VERSION ""

NS_ :

BS_:

BU_: BMS ECC EVBUS_Virtual_ECU GW OBC VCU

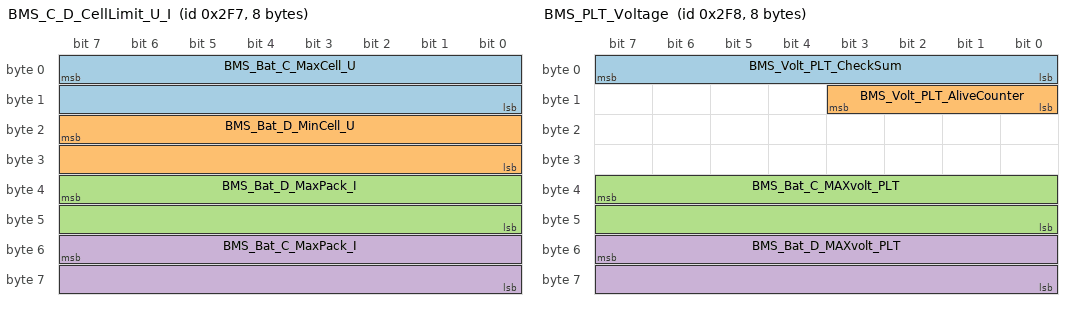
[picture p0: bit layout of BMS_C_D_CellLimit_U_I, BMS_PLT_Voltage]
BO_ 759 BMS_C_D_CellLimit_U_I: 8 BMS
 SG_ BMS_Bat_C_MaxCell_U : 7|16@0+ (0.1,0) [0|6553.5] "mV"  GW,VCU
 SG_ BMS_Bat_D_MinCell_U : 23|16@0+ (0.1,0) [0|6553.5] "mV"  ECC,GW,OBC,VCU
 SG_ BMS_Bat_D_MaxPack_I : 39|16@0+ (0.02,0) [0|1310.7] "A"  ECC,GW,OBC,VCU
 SG_ BMS_Bat_C_MaxPack_I : 55|16@0+ (0.02,0) [0|1310.7] "A"  GW,VCU

BO_ 760 BMS_PLT_Voltage: 8 BMS
 SG_ BMS_Volt_PLT_CheckSum : 7|8@0+ (1,0) [0|255] ""  GW,VCU
 SG_ BMS_Volt_PLT_AliveCounter : 11|4@0+ (1,0) [0|14] ""  GW,VCU
 SG_ BMS_Bat_C_MAXvolt_PLT : 39|16@0+ (0.02,0) [0|1310.7] "V"  GW,VCU
 SG_ BMS_Bat_D_MAXvolt_PLT : 55|16@0+ (0.02,0) [0|1310.7] "V"  GW,VCU

BO_ 792 ESP_0x318: 8 GW
 SG_ ESP_318_CheckSum : 7|8@0+ (1,0) [0|255] ""  BMS,ECC,OBC
 SG_ ESP_318_AliveCounter : 11|4@0+ (1,0) [0|14] ""  BMS,ECC,OBC
 SG_ ESP_BrkPedlStsVld : 13|2@0+ (1,0) [0|3] ""  ECC
 SG_ ESP_BrkPedlSts : 14|1@0+ (1,0) [0|1] ""  ECC
 SG_ ESP_VehSpdVld : 17|2@0+ (1,0) [0|3] ""  BMS,ECC,OBC
 SG_ ESP_SysActv : 20|1@0+ (1,0) [0|1] ""  ECC
 SG_ ESP_LampSwtOffIndcn : 21|1@0+ (1,0) [0|1] ""  ECC
 SG_ ESP_FltIndcn_EBD : 22|1@0+ (1,0) [0|1] ""  ECC
 SG_ ESP_FltIndcn_ABS : 23|1@0+ (1,0) [0|1] ""  ECC
 SG_ ESP_MilgRollgCntr_ODO : 31|16@0+ (1,0) [0|65535] "pulses"  ECC
 SG_ ESP_VehSpd : 47|16@0+ (0.1,0) [0|300] "km/h"  BMS,ECC,OBC
 SG_ ESP_IninModSigIndcn : 56|1@0+ (1,0) [0|1] ""  ECC
 SG_ ESP_FltIndcn_TCS : 57|1@0+ (1,0) [0|1] ""  ECC
 SG_ ESP_CtrlSts_HDC : 59|2@0+ (1,0) [0|3] ""  ECC
 SG_ ESP_AvlIndcn_HDC : 60|1@0+ (1,0) [0|1] ""  ECC
 SG_ ESP_NoBrkP : 61|1@0+ (1,0) [0|1] ""  ECC
 SG_ ESP_RDAEnaFlg : 62|1@0+ (1,0) [0|1] ""  ECC

BO_ 816 BMS_HVBatt_Status_2_TBOX: 16 BMS
 SG_ BMS_330_391_CheckSum : 7|8@0+ (1,0) [0|255] ""  GW,VCU
 SG_ BMS_330_391_AliveCounter : 11|4@0+ (1,0) [0|14] ""  GW,VCU
 SG_ BMS_VehInsulFltDisp : 16|1@0+ (1,0) [0|1] ""  GW
 SG_ BMS_PwrBattSysFltDisp : 17|1@0+ (1,0) [0|1] ""  GW
 SG_ BMS_PwrBattRmngCpSOC : 31|8@0+ (0.4,0) [0|100] "%"  ECC,GW,VCU
 SG_ BMS_PwrBattAvlCp : 39|16@0+ (0.01,0) [0|655.35] "Ah"  GW,VCU
 SG_ BMS_CellMinTAlrm : 48|1@0+ (1,0) [0|1] ""  GW,VCU
 SG_ BMS_PwrBattThermRunawayAlrm : 49|1@0+ (1,0) [0|1] ""  GW,VCU
 SG_ BMS_PwrBattOverT : 53|1@0+ (1,0) [0|1] ""  GW,VCU
 SG_ BMS_PwrBattInsulSts : 55|2@0+ (1,0) [0|3] ""  GW,VCU
 SG_ BMS_330_SSecOC_Fresh_Byte0 : 71|8@0+ (1,0) [0|255] ""  GW,VCU
 SG_ BMS_330_SSecOC_MAC_Byte0 : 79|8@0+ (1,0) [0|255] ""  GW,VCU
 SG_ BMS_330_SSecOC_MAC_Byte1 : 87|8@0+ (1,0) [0|255] ""  GW,VCU
 SG_ BMS_330_SSecOC_MAC_Byte2 : 95|8@0+ (1,0) [0|255] ""  GW,VCU

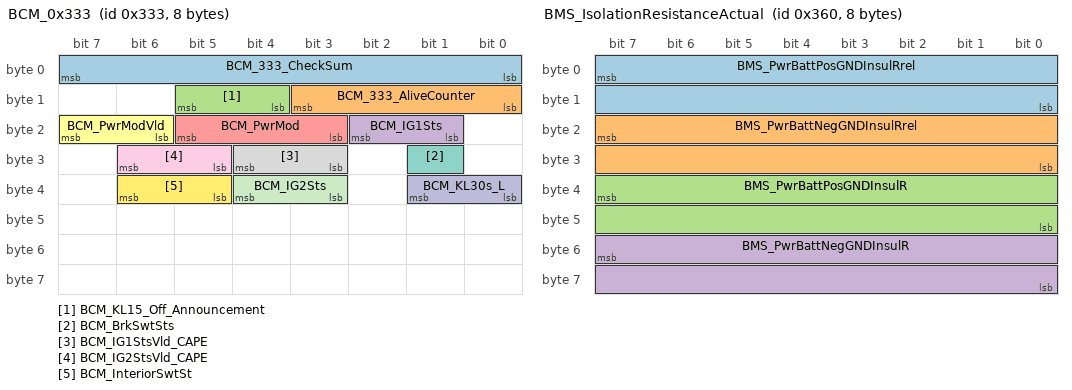
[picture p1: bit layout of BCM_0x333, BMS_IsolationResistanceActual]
BO_ 819 BCM_0x333: 8 GW
 SG_ BCM_333_CheckSum : 7|8@0+ (1,0) [0|255] ""  BMS,ECC,OBC,VCU
 SG_ BCM_333_AliveCounter : 11|4@0+ (1,0) [0|14] ""  BMS,ECC,OBC,VCU
 SG_ BCM_KL15_Off_Announcement : 13|2@0+ (1,0) [0|3] ""  ECC
 SG_ BCM_IG1Sts : 18|2@0+ (1,0) [0|3] ""  BMS,ECC
 SG_ BCM_PwrMod : 21|3@0+ (1,0) [0|7] ""  BMS,ECC,OBC,VCU
 SG_ BCM_PwrModVld : 23|2@0+ (1,0) [0|3] ""  BMS,ECC,OBC,VCU
 SG_ BCM_BrkSwtSts : 25|1@0+ (1,0) [0|1] ""  ECC
 SG_ BCM_IG1StsVld_CAPE : 28|2@0+ (1,0) [0|3] ""  BMS,ECC
 SG_ BCM_IG2StsVld_CAPE : 30|2@0+ (1,0) [0|3] ""  ECC
 SG_ BCM_KL30s_L : 33|2@0+ (1,0) [0|3] ""  ECC
 SG_ BCM_IG2Sts : 36|2@0+ (1,0) [0|3] ""  ECC
 SG_ BCM_InteriorSwtSt : 38|2@0+ (1,0) [0|3] ""  ECC

BO_ 856 VCU_0x358: 8 VCU
 SG_ VCU_358_CheckSum : 7|8@0+ (1,0) [0|255] ""  EVBUS_Virtual_ECU
 SG_ VCU_358_AliveCounter : 11|4@0+ (1,0) [0|14] ""  EVBUS_Virtual_ECU
 SG_ VCU_KickdwnFlg : 13|2@0+ (1,0) [0|3] ""  EVBUS_Virtual_ECU
 SG_ VCU_EPedlEnaSig : 15|1@0+ (1,0) [0|1] ""  EVBUS_Virtual_ECU
 SG_ VCU_ComLostFlt_ESP : 16|1@0+ (1,0) [0|1] ""  EVBUS_Virtual_ECU
 SG_ VCU_ComFlt_iBooster : 17|1@0+ (1,0) [0|1] ""  EVBUS_Virtual_ECU
 SG_ VCU_RegenLvlFb : 19|2@0+ (1,0) [0|3] ""  EVBUS_Virtual_ECU
 SG_ VCU_AccelModFb : 21|2@0+ (1,0) [0|3] ""  EVBUS_Virtual_ECU
 SG_ VCU_EPedlStsFb : 23|2@0+ (1,0) [0|3] ""  EVBUS_Virtual_ECU
 SG_ VCU_CcTrgSpdDisp : 31|8@0+ (1,0) [0|255] ""  EVBUS_Virtual_ECU
 SG_ VCU_Sts_CC_ICC : 35|4@0+ (1,0) [0|15] ""  EVBUS_Virtual_ECU
 SG_ VCU_CCIconDisp : 38|3@0+ (1,0) [0|7] ""  EVBUS_Virtual_ECU
 SG_ VCU_DispSpdUnit_CC : 39|1@0+ (1,0) [0|1] ""  EVBUS_Virtual_ECU
 SG_ VCU_BoostEnStat : 43|4@0+ (1,0) [0|15] ""  EVBUS_Virtual_ECU
 SG_ VCU_OTARdy_Fb : 45|2@0+ (1,0) [0|3] ""  EVBUS_Virtual_ECU
 SG_ VCU_OTA_ECUInhb_Req : 47|2@0+ (1,0) [0|3] ""  EVBUS_Virtual_ECU
 SG_ VCU_OTAVehCdnChk_ASIL : 49|2@0+ (1,0) [0|3] ""  BMS,ECC,OBC
 SG_ VCU_OTAVehInhb_ASIL_Fb : 51|2@0+ (1,0) [0|3] ""  BMS,ECC,OBC

BO_ 864 BMS_IsolationResistanceActual: 8 BMS
 SG_ BMS_PwrBattPosGNDInsulRrel : 7|16@0+ (1,0) [0|65535] "Ohm/V"  GW,VCU
 SG_ BMS_PwrBattNegGNDInsulRrel : 23|16@0+ (1,0) [0|65535] "Ohm/V"  GW,VCU
 SG_ BMS_PwrBattPosGNDInsulR : 39|16@0+ (1,0) [0|65535] "k¦¸"  GW,VCU
 SG_ BMS_PwrBattNegGNDInsulR : 55|16@0+ (1,0) [0|65535] "k¦¸"  GW,VCU

BO_ 882 BMS_CellTemp_CoolingHeating: 16 BMS
 SG_ BMS_372_382_CheckSum : 7|8@0+ (1,0) [0|255] ""  ECC,GW,VCU
 SG_ BMS_372_382_AliveCounter : 11|4@0+ (1,0) [0|14] ""  ECC,GW,VCU
 SG_ BMS_OTARdy_Fb : 13|2@0+ (1,0) [0|3] ""  GW
 SG_ BMS_CellMinT : 23|8@0+ (1,-48) [-48|207] "Degree Celsius"  ECC,GW,VCU
 SG_ BMS_CellDiffT : 31|8@0+ (1,0) [0|255] "Degree Celsius"  ECC,GW,VCU
 SG_ BMS_CellMaxT : 39|8@0+ (1,-48) [-48|207] "Degree Celsius"  ECC,GW,VCU
 SG_ BMS_BattAvrgT : 47|8@0+ (1,-48) [-48|207] "Degree Celsius"  ECC,GW,VCU
 SG_ BMS_PwrBattHeatgMngDmd : 49|2@0+ (1,0) [0|3] ""  ECC,GW,VCU
 SG_ BMS_ECCSysAllwDwnPwrCmd : 50|1@0+ (1,0) [0|1] ""  ECC,GW
 SG_ BMS_BattInlTDmd : 63|8@0+ (1,-48) [-48|207] ""  ECC,GW
 SG_ BMS_372_SSecOC_Fresh_Byte0 : 71|8@0+ (1,0) [0|255] ""  GW,VCU
 SG_ BMS_372_SSecOC_MAC_Byte0 : 79|8@0+ (1,0) [0|255] ""  GW,VCU
 SG_ BMS_372_SSecOC_MAC_Byte1 : 87|8@0+ (1,0) [0|255] ""  GW,VCU
 SG_ BMS_372_SSecOC_MAC_Byte2 : 95|8@0+ (1,0) [0|255] ""  GW,VCU

BO_ 883 ECC_0x373: 8 ECC
 SG_ ECC_CrtSts : 3|4@0+ (1,0) [0|15] ""  GW,VCU
 SG_ ECC_IninSts : 4|1@0+ (1,0) [0|1] ""  GW,VCU
 SG_ ECC_PwrSysHeatMngtSts : 6|2@0+ (1,0) [0|3] ""  GW,VCU
 SG_ ECC_ACSts : 7|1@0+ (1,0) [0|1] ""  GW,VCU
 SG_ ECC_AirClnSts : 8|1@0+ (1,0) [0|1] ""  GW,VCU
 SG_ ECC_WindSpdSts : 12|4@0+ (1,0) [0|15] ""  BMS,GW,VCU
 SG_ ECC_BackRowAirOutlModSts : 15|3@0+ (1,0) [0|7] ""  GW,VCU
 SG_ ECC_DrvrTSetSts : 23|8@0+ (0.5,0) [0|127.5] ""  GW,VCU
 SG_ ECC_PassTSetSts : 31|8@0+ (0.5,0) [0|127.5] ""  GW,VCU
 SG_ ECC_HeatSts : 32|1@0+ (1,0) [0|1] ""  BMS,GW,VCU
 SG_ ECC_AUTOSts : 33|1@0+ (1,0) [0|1] ""  GW,VCU
 SG_ ECC_SYNCSts : 34|1@0+ (1,0) [0|1] ""  GW,VCU
 SG_ ECC_InfoSysWrmColdDisp : 36|2@0+ (1,0) [0|3] ""  GW,VCU
 SG_ ECC_CircSts : 37|1@0+ (1,0) [0|1] ""  GW,VCU
 SG_ ECC_ParticleConcVld : 39|2@0+ (1,0) [0|3] ""  GW,VCU
 SG_ ECC_OutdT : 47|8@0+ (0.5,-48) [-48|79.5] "Degree Celsius"  BMS,GW,VCU
 SG_ ECC_OutdTVld : 49|2@0+ (1,0) [0|3] ""  BMS,GW,VCU
 SG_ ECC_MaxFrntDefrst : 50|1@0+ (1,0) [0|1] ""  GW,VCU
 SG_ ECC_HeatMngtSysFlt : 51|1@0+ (1,0) [0|1] ""  GW,VCU
 SG_ ECC_HeatMngtFctLim : 52|1@0+ (1,0) [0|1] ""  GW,VCU
 SG_ ECC_DrvrAirOutlMod : 55|3@0+ (1,0) [0|7] ""  GW,VCU
 SG_ ECC_PassAirOutlMod : 58|3@0+ (1,0) [0|7] ""  GW,VCU
 SG_ ECC_RemSts : 60|2@0+ (1,0) [0|3] ""  GW,VCU
 SG_ ECC_OTAInhbRdy : 62|2@0+ (1,0) [0|3] ""  GW,VCU

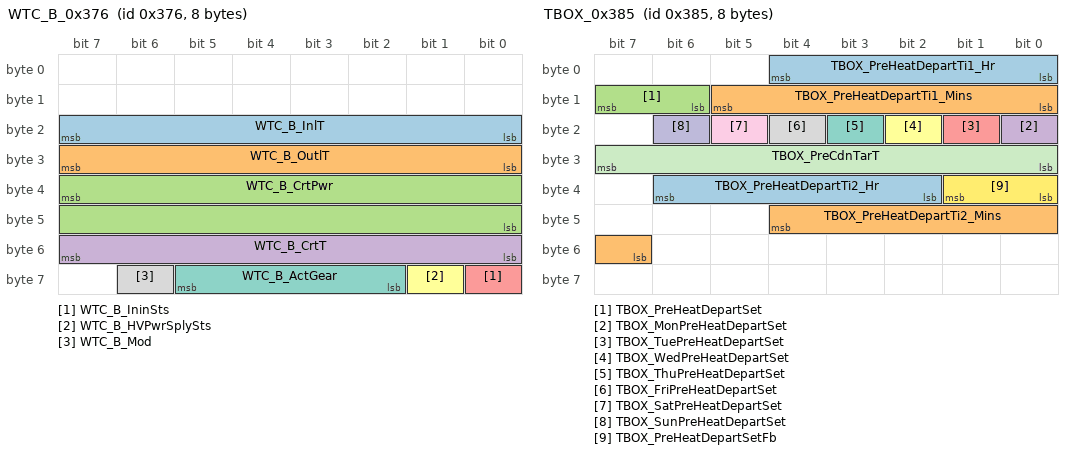
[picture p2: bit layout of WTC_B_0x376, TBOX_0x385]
BO_ 886 WTC_B_0x376: 8 ECC
 SG_ WTC_B_InlT : 23|8@0+ (1,-48) [-48|207] "Degree Celsius"  GW
 SG_ WTC_B_OutlT : 31|8@0+ (1,-48) [-48|207] "Degree Celsius"  GW
 SG_ WTC_B_CrtPwr : 39|16@0+ (1,0) [0|10000] ""  GW,VCU
 SG_ WTC_B_CrtT : 55|8@0+ (1,-48) [-48|207] "Degree Celsius"  GW
 SG_ WTC_B_IninSts : 56|1@0+ (1,0) [0|1] ""  GW
 SG_ WTC_B_HVPwrSplySts : 57|1@0+ (1,0) [0|1] ""  GW
 SG_ WTC_B_ActGear : 61|4@0+ (1,0) [0|15] ""  GW
 SG_ WTC_B_Mod : 62|1@0+ (1,0) [0|1] ""  BMS,GW,VCU

BO_ 901 TBOX_0x385: 8 GW
 SG_ TBOX_PreHeatDepartTi1_Hr : 4|5@0+ (1,0) [0|23] ""  EVBUS_Virtual_ECU
 SG_ TBOX_PreHeatDepartTi1_Mins : 13|6@0+ (1,0) [0|59] ""  EVBUS_Virtual_ECU
 SG_ TBOX_PreHeatDepartSet : 15|2@0+ (1,0) [0|3] ""  EVBUS_Virtual_ECU
 SG_ TBOX_MonPreHeatDepartSet : 16|1@0+ (1,0) [0|1] ""  EVBUS_Virtual_ECU
 SG_ TBOX_TuePreHeatDepartSet : 17|1@0+ (1,0) [0|1] ""  EVBUS_Virtual_ECU
 SG_ TBOX_WedPreHeatDepartSet : 18|1@0+ (1,0) [0|1] ""  EVBUS_Virtual_ECU
 SG_ TBOX_ThuPreHeatDepartSet : 19|1@0+ (1,0) [0|1] ""  EVBUS_Virtual_ECU
 SG_ TBOX_FriPreHeatDepartSet : 20|1@0+ (1,0) [0|1] ""  EVBUS_Virtual_ECU
 SG_ TBOX_SatPreHeatDepartSet : 21|1@0+ (1,0) [0|1] ""  EVBUS_Virtual_ECU
 SG_ TBOX_SunPreHeatDepartSet : 22|1@0+ (1,0) [0|1] ""  EVBUS_Virtual_ECU
 SG_ TBOX_PreCdnTarT : 31|8@0+ (0.5,0) [-48|255] "Degree Celsius"  VCU
 SG_ TBOX_PreHeatDepartSetFb : 33|2@0+ (1,0) [0|3] ""  EVBUS_Virtual_ECU
 SG_ TBOX_PreHeatDepartTi2_Hr : 38|5@0+ (1,0) [0|23] ""  EVBUS_Virtual_ECU
 SG_ TBOX_PreHeatDepartTi2_Mins : 44|6@0+ (1,0) [0|59] ""  EVBUS_Virtual_ECU

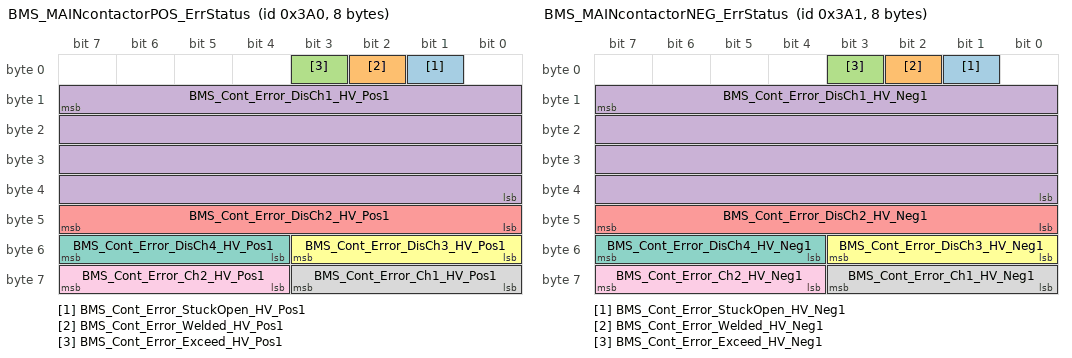
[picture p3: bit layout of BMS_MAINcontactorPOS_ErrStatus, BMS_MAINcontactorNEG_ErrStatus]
BO_ 928 BMS_MAINcontactorPOS_ErrStatus: 8 BMS
 SG_ BMS_Cont_Error_StuckOpen_HV_Pos1 : 1|1@0+ (1,0) [0|1] ""  GW,VCU
 SG_ BMS_Cont_Error_Welded_HV_Pos1 : 2|1@0+ (1,0) [0|1] ""  GW,VCU
 SG_ BMS_Cont_Error_Exceed_HV_Pos1 : 3|1@0+ (1,0) [0|1] ""  GW,VCU
 SG_ BMS_Cont_Error_DisCh1_HV_Pos1 : 15|32@0+ (1,0) [0|4294967295] ""  GW,VCU
 SG_ BMS_Cont_Error_DisCh2_HV_Pos1 : 47|8@0+ (1,0) [0|255] ""  GW,VCU
 SG_ BMS_Cont_Error_DisCh3_HV_Pos1 : 51|4@0+ (1,0) [0|15] ""  GW,VCU
 SG_ BMS_Cont_Error_DisCh4_HV_Pos1 : 55|4@0+ (1,0) [0|15] ""  GW,VCU
 SG_ BMS_Cont_Error_Ch1_HV_Pos1 : 59|4@0+ (1,0) [0|15] ""  GW,VCU
 SG_ BMS_Cont_Error_Ch2_HV_Pos1 : 63|4@0+ (1,0) [0|15] ""  GW,VCU

BO_ 929 BMS_MAINcontactorNEG_ErrStatus: 8 BMS
 SG_ BMS_Cont_Error_StuckOpen_HV_Neg1 : 1|1@0+ (1,0) [0|1] ""  GW,VCU
 SG_ BMS_Cont_Error_Welded_HV_Neg1 : 2|1@0+ (1,0) [0|1] ""  GW,VCU
 SG_ BMS_Cont_Error_Exceed_HV_Neg1 : 3|1@0+ (1,0) [0|1] ""  GW,VCU
 SG_ BMS_Cont_Error_DisCh1_HV_Neg1 : 15|32@0+ (1,0) [0|4294967295] ""  GW,VCU
 SG_ BMS_Cont_Error_DisCh2_HV_Neg1 : 47|8@0+ (1,0) [0|255] ""  GW,VCU
 SG_ BMS_Cont_Error_DisCh3_HV_Neg1 : 51|4@0+ (1,0) [0|15] ""  GW,VCU
 SG_ BMS_Cont_Error_DisCh4_HV_Neg1 : 55|4@0+ (1,0) [0|15] ""  GW,VCU
 SG_ BMS_Cont_Error_Ch1_HV_Neg1 : 59|4@0+ (1,0) [0|15] ""  GW,VCU
 SG_ BMS_Cont_Error_Ch2_HV_Neg1 : 63|4@0+ (1,0) [0|15] ""  GW,VCU

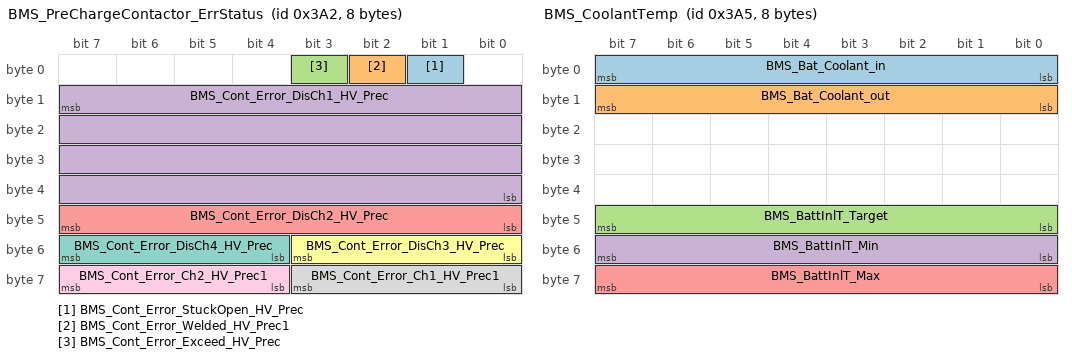
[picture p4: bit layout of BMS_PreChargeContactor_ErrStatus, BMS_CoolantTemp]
BO_ 930 BMS_PreChargeContactor_ErrStatus: 8 BMS
 SG_ BMS_Cont_Error_StuckOpen_HV_Prec : 1|1@0+ (1,0) [0|1] ""  GW,VCU
 SG_ BMS_Cont_Error_Welded_HV_Prec1 : 2|1@0+ (1,0) [0|1] ""  GW,VCU
 SG_ BMS_Cont_Error_Exceed_HV_Prec : 3|1@0+ (1,0) [0|1] ""  GW,VCU
 SG_ BMS_Cont_Error_DisCh1_HV_Prec : 15|32@0+ (1,0) [0|4294967295] ""  GW,VCU
 SG_ BMS_Cont_Error_DisCh2_HV_Prec : 47|8@0+ (1,0) [0|255] ""  GW,VCU
 SG_ BMS_Cont_Error_DisCh3_HV_Prec : 51|4@0+ (1,0) [0|15] ""  GW,VCU
 SG_ BMS_Cont_Error_DisCh4_HV_Prec : 55|4@0+ (1,0) [0|15] ""  GW,VCU
 SG_ BMS_Cont_Error_Ch1_HV_Prec1 : 59|4@0+ (1,0) [0|15] ""  GW,VCU
 SG_ BMS_Cont_Error_Ch2_HV_Prec1 : 63|4@0+ (1,0) [0|15] ""  GW,VCU

BO_ 933 BMS_CoolantTemp: 8 BMS
 SG_ BMS_Bat_Coolant_in : 7|8@0+ (0.5,-40) [-40|87.5] "Degree Celsius"  ECC,GW,VCU
 SG_ BMS_Bat_Coolant_out : 15|8@0+ (0.5,-40) [-40|87.5] "Degree Celsius"  ECC,GW,VCU
 SG_ BMS_BattInlT_Target : 47|8@0+ (1,-48) [-48|207] "Degree Celsius"  ECC,GW,VCU
 SG_ BMS_BattInlT_Min : 55|8@0+ (1,-48) [-48|207] "Degree Celsius"  ECC,GW,VCU
 SG_ BMS_BattInlT_Max : 63|8@0+ (1,-48) [-48|207] "Degree Celsius"  ECC,GW,VCU

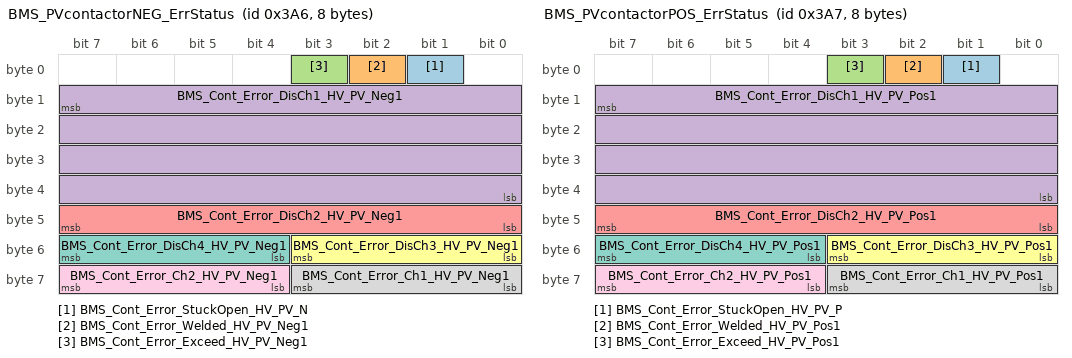
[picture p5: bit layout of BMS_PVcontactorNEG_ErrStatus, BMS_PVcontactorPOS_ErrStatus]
BO_ 934 BMS_PVcontactorNEG_ErrStatus: 8 BMS
 SG_ BMS_Cont_Error_StuckOpen_HV_PV_N : 1|1@0+ (1,0) [0|1] ""  GW,VCU
 SG_ BMS_Cont_Error_Welded_HV_PV_Neg1 : 2|1@0+ (1,0) [0|1] ""  GW,VCU
 SG_ BMS_Cont_Error_Exceed_HV_PV_Neg1 : 3|1@0+ (1,0) [0|1] ""  GW,VCU
 SG_ BMS_Cont_Error_DisCh1_HV_PV_Neg1 : 15|32@0+ (1,0) [0|4294967295] ""  GW,VCU
 SG_ BMS_Cont_Error_DisCh2_HV_PV_Neg1 : 47|8@0+ (1,0) [0|255] ""  GW,VCU
 SG_ BMS_Cont_Error_DisCh3_HV_PV_Neg1 : 51|4@0+ (1,0) [0|15] ""  GW,VCU
 SG_ BMS_Cont_Error_DisCh4_HV_PV_Neg1 : 55|4@0+ (1,0) [0|15] ""  GW,VCU
 SG_ BMS_Cont_Error_Ch1_HV_PV_Neg1 : 59|4@0+ (1,0) [0|15] ""  GW,VCU
 SG_ BMS_Cont_Error_Ch2_HV_PV_Neg1 : 63|4@0+ (1,0) [0|15] ""  GW,VCU

BO_ 935 BMS_PVcontactorPOS_ErrStatus: 8 BMS
 SG_ BMS_Cont_Error_StuckOpen_HV_PV_P : 1|1@0+ (1,0) [0|1] ""  GW,VCU
 SG_ BMS_Cont_Error_Welded_HV_PV_Pos1 : 2|1@0+ (1,0) [0|1] ""  GW,VCU
 SG_ BMS_Cont_Error_Exceed_HV_PV_Pos1 : 3|1@0+ (1,0) [0|1] ""  GW,VCU
 SG_ BMS_Cont_Error_DisCh1_HV_PV_Pos1 : 15|32@0+ (1,0) [0|4294967295] ""  GW,VCU
 SG_ BMS_Cont_Error_DisCh2_HV_PV_Pos1 : 47|8@0+ (1,0) [0|255] ""  GW,VCU
 SG_ BMS_Cont_Error_DisCh3_HV_PV_Pos1 : 51|4@0+ (1,0) [0|15] ""  GW,VCU
 SG_ BMS_Cont_Error_DisCh4_HV_PV_Pos1 : 55|4@0+ (1,0) [0|15] ""  GW,VCU
 SG_ BMS_Cont_Error_Ch1_HV_PV_Pos1 : 59|4@0+ (1,0) [0|15] ""  GW,VCU
 SG_ BMS_Cont_Error_Ch2_HV_PV_Pos1 : 63|4@0+ (1,0) [0|15] ""  GW,VCU

BO_ 1140 TBOX_0x474: 8 GW
 SG_ TBOX_ICC_UpdSched : 1|2@0+ (1,0) [0|3] ""  EVBUS_Virtual_ECU
 SG_ TBOX_OTAReq_BMS : 17|2@0+ (1,0) [0|3] ""  VCU
 SG_ TBOX_OTAReq_VCU : 19|2@0+ (1,0) [0|3] ""  VCU
 SG_ TBOX_OTAReq_ECC : 21|2@0+ (1,0) [0|3] ""  VCU
 SG_ TBOX_OTAReq_OBC : 23|2@0+ (1,0) [0|3] ""  VCU
 SG_ TBOX_OTAReq_MCU_F : 25|2@0+ (1,0) [0|3] ""  VCU
 SG_ TBOX_OTAReq_MCU_R : 27|2@0+ (1,0) [0|3] ""  VCU
 SG_ TBOX_OTAReq_ADAS : 29|2@0+ (1,0) [0|3] ""  VCU
 SG_ TBOX_OTAReq_FCM : 31|2@0+ (1,0) [0|3] ""  VCU
 SG_ TBOX_OTAReq_GW : 33|2@0+ (1,0) [0|3] ""  VCU
 SG_ TBOX_OTAReq_EPS : 35|2@0+ (1,0) [0|3] ""  VCU
 SG_ TBOX_OTAReq_ESP : 37|2@0+ (1,0) [0|3] ""  VCU
 SG_ TBOX_OTAReq_iBooster : 39|2@0+ (1,0) [0|3] ""  VCU
 SG_ TBOX_OTAReq_SCM : 41|2@0+ (1,0) [0|3] ""  VCU
 SG_ TBOX_OTAReq_ICC : 43|2@0+ (1,0) [0|3] ""  VCU
 SG_ TBOX_OTAReq_OHC : 45|2@0+ (1,0) [0|3] ""  VCU
 SG_ TBOX_OTAReq_BCM : 47|2@0+ (1,0) [0|3] ""  VCU
 SG_ TBOX_OTAReq_CIM : 49|2@0+ (1,0) [0|3] ""  VCU
 SG_ TBOX_OTAReq_PKC : 51|2@0+ (1,0) [0|3] ""  VCU
 SG_ TBOX_OTAReq_PLGM : 53|2@0+ (1,0) [0|3] ""  VCU
 SG_ TBOX_OTAReq_TRM : 55|2@0+ (1,0) [0|3] ""  VCU
 SG_ TBOX_OTAReq_DSMC : 57|2@0+ (1,0) [0|3] ""  VCU
 SG_ TBOX_OTAReq_PSM : 59|2@0+ (1,0) [0|3] ""  VCU
 SG_ TBOX_OTAReq_VSP : 61|2@0+ (1,0) [0|3] ""  VCU
 SG_ TBOX_OTAReq_TBOX : 63|2@0+ (1,0) [0|3] ""  VCU

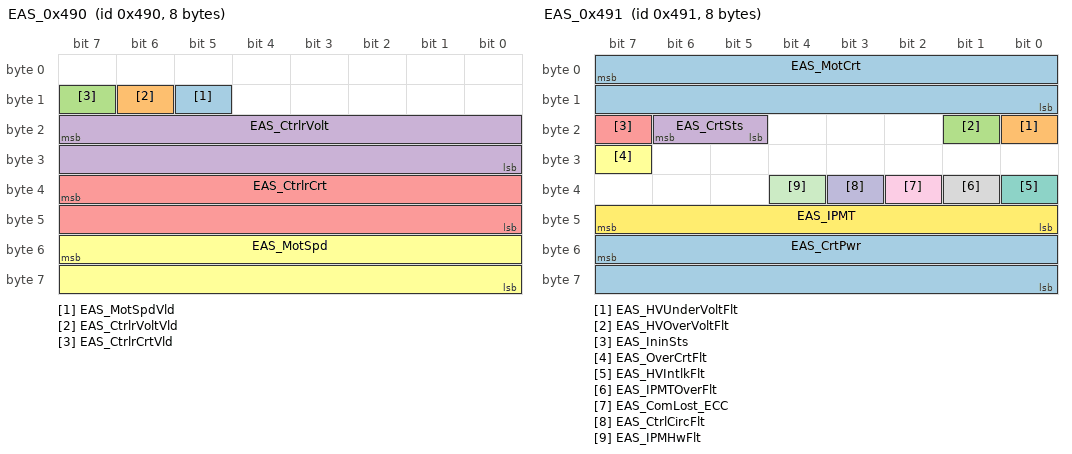
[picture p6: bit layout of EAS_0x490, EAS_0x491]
BO_ 1168 EAS_0x490: 8 ECC
 SG_ EAS_MotSpdVld : 13|1@0+ (1,0) [0|1] ""  BMS,GW,VCU
 SG_ EAS_CtrlrVoltVld : 14|1@0+ (1,0) [0|1] ""  BMS,GW,VCU
 SG_ EAS_CtrlrCrtVld : 15|1@0+ (1,0) [0|1] ""  BMS,GW,VCU
 SG_ EAS_CtrlrVolt : 23|16@0+ (0.02,0) [0|1310.7] "V"  BMS,GW,VCU
 SG_ EAS_CtrlrCrt : 39|16@0+ (0.02,0) [0|1310.7] "A"  BMS,GW,VCU
 SG_ EAS_MotSpd : 55|16@0+ (0.25,0) [0|16383.75] "rpm"  BMS,GW,VCU

BO_ 1169 EAS_0x491: 8 ECC
 SG_ EAS_MotCrt : 7|16@0+ (0.02,0) [0|1310.7] "A"  GW
 SG_ EAS_HVUnderVoltFlt : 16|1@0+ (1,0) [0|1] ""  GW
 SG_ EAS_HVOverVoltFlt : 17|1@0+ (1,0) [0|1] ""  GW
 SG_ EAS_CrtSts : 22|2@0+ (1,0) [0|3] ""  BMS,GW,VCU
 SG_ EAS_IninSts : 23|1@0+ (1,0) [0|1] ""  GW
 SG_ EAS_OverCrtFlt : 31|1@0+ (1,0) [0|1] ""  GW
 SG_ EAS_HVIntlkFlt : 32|1@0+ (1,0) [0|1] ""  GW,VCU
 SG_ EAS_IPMTOverFlt : 33|1@0+ (1,0) [0|1] ""  GW
 SG_ EAS_ComLost_ECC : 34|1@0+ (1,0) [0|1] ""  GW
 SG_ EAS_CtrlCircFlt : 35|1@0+ (1,0) [0|1] ""  GW
 SG_ EAS_IPMHwFlt : 36|1@0+ (1,0) [0|1] ""  GW
 SG_ EAS_IPMT : 47|8@0+ (1,-48) [-48|207] "Degree Celsius"  GW
 SG_ EAS_CrtPwr : 55|16@0+ (0.2,0) [0|13107] "W"  GW,VCU

BO_ 1268 TBOX_0x4F4: 16 GW
 SG_ TBOX_4F4_4F8_CheckSum : 7|8@0+ (1,0) [0|255] ""  EVBUS_Virtual_ECU
 SG_ TBOX_4F4_4F8_AliveCounter : 11|4@0+ (1,0) [0|14] ""  EVBUS_Virtual_ECU
 SG_ TBOX_Sw_upd : 13|2@0+ (1,0) [0|3] ""  VCU
 SG_ TBOX_Flsflg : 18|3@0+ (1,0) [0|7] ""  BMS,ECC,OBC,VCU
 SG_ TBOX_RemFlsh : 21|3@0+ (1,0) [0|7] ""  BMS,ECC,OBC,VCU
 SG_ TBOX_FobdGWPartBUSUDSCom : 23|2@0+ (1,0) [0|3] ""  VCU
 SG_ TBOX_RemChrgInsulFctReq : 25|2@0+ (1,0) [0|3] ""  VCU
 SG_ TBOX_EHUSetTrvlMod : 27|2@0+ (1,0) [0|3] ""  VCU
 SG_ TBOX_ResvACChrgOpenSts : 29|2@0+ (1,0) [0|3] ""  VCU
 SG_ TBOX_RemKL15PwrOnReq : 31|2@0+ (1,0) [0|3] ""  VCU
 SG_ TBOX_SetChrgEndSOC : 38|7@0+ (1,0) [0|100] "%"  VCU
 SG_ TBOX_PreCondTriggerReq : 42|3@0+ (1,0) [0|7] ""  VCU
 SG_ TBOX_BlowLvlReq : 45|3@0+ (1,0) [0|7] ""  VCU
 SG_ TBOX_ICC_UpdStrt : 47|2@0+ (1,0) [0|3] ""  VCU
 SG_ TBOX_VehiMod : 51|4@0+ (1,0) [0|15] ""  VCU
 SG_ TBOX_Crash_cfm : 53|2@0+ (1,0) [0|3] ""  VCU
 SG_ TBOX_SchedChrgnReq : 57|2@0+ (1,0) [0|3] ""  VCU
 SG_ TBOX_4F4_SSecOC_Fresh_Byte0 : 71|8@0+ (1,0) [0|255] ""  VCU
 SG_ TBOX_4F4_SSecOC_MAC_Byte0 : 79|8@0+ (1,0) [0|255] ""  VCU
 SG_ TBOX_4F4_SSecOC_MAC_Byte1 : 87|8@0+ (1,0) [0|255] ""  VCU
 SG_ TBOX_4F4_SSecOC_MAC_Byte2 : 95|8@0+ (1,0) [0|255] ""  VCU

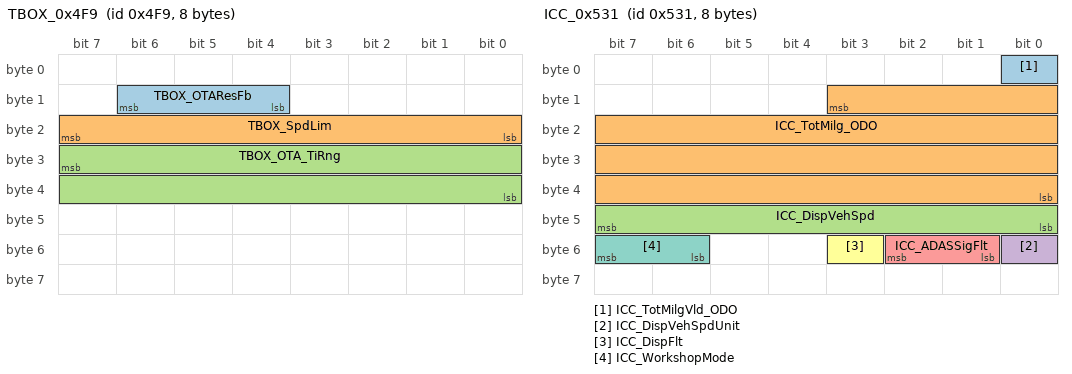
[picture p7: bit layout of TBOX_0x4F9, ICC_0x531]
BO_ 1273 TBOX_0x4F9: 8 GW
 SG_ TBOX_OTAResFb : 14|3@0+ (1,0) [0|7] ""  EVBUS_Virtual_ECU
 SG_ TBOX_SpdLim : 23|8@0+ (1,0) [0|255] "km/h"  EVBUS_Virtual_ECU
 SG_ TBOX_OTA_TiRng : 31|16@0+ (1,0) [0|65534] "mintue"  EVBUS_Virtual_ECU

BO_ 1287 VCU_0x507: 8 VCU
 SG_ VCU_OTAVehInhb_QM_Fb : 5|2@0+ (1,0) [0|3] ""  BMS,ECC,GW,OBC
 SG_ VCU_OTAVehCdnChk_QM_sts : 7|2@0+ (1,0) [0|3] ""  BMS,ECC,GW,OBC
 SG_ VCU_DrvAvl : 8|1@0+ (1,0) [0|1] ""  ECC,GW
 SG_ VCU_CllsnSigSts : 9|1@0+ (1,0) [0|1] ""  ECC,GW
 SG_ VCU_VehSts_GB : 13|2@0+ (1,0) [0|3] ""  ECC,GW
 SG_ VCU_MCUOverTFlt_GB : 14|1@0+ (1,0) [0|1] ""  ECC,GW
 SG_ VCU_DrvrMotOverTFlt_GB : 15|1@0+ (1,0) [0|1] ""  ECC,GW
 SG_ VCU_SOCTooLoAlrm : 16|1@0+ (1,0) [0|1] ""  ECC,GW
 SG_ VCU_SOCJumpAlrm : 17|1@0+ (1,0) [0|1] ""  ECC,GW
 SG_ VCU_PwrBattPackMismatAlrm : 18|1@0+ (1,0) [0|1] ""  ECC,GW
 SG_ VCU_SOCTooHiAlrm : 19|1@0+ (1,0) [0|1] ""  ECC,GW
 SG_ VCU_DCDCEnaCmd : 20|1@0+ (1,0) [0|1] ""  ECC,GW,OBC
 SG_ VCU_PwrBattECCEnaCmd : 22|1@0+ (1,0) [0|1] ""  ECC,GW
 SG_ VCU_MstRlyCtrlCmd : 23|1@0+ (1,0) [0|1] ""  ECC,GW
 SG_ VCU_DCDCOutpVoltCmd : 31|8@0+ (0.1,0) [0|25.5] "V"  ECC,GW,OBC
 SG_ VCU_CCCnctnVolt : 39|8@0+ (0.1,0) [0|25.5] "V"  ECC,GW
 SG_ VCU_GearSig_GB : 43|4@0+ (1,0) [0|15] ""  ECC,GW
 SG_ VCU_DrvrMotNr_GB : 47|4@0+ (1,0) [0|15] ""  ECC,GW
 SG_ VCU_BattVolt : 55|16@0+ (0.001,0) [0|65.535] "V"  BMS,ECC,GW,OBC

BO_ 1297 VCU_0x511: 8 VCU
 SG_ VCU_BMSLVWakeUpSts : 0|1@0+ (1,0) [0|1] ""  GW
 SG_ VCU_ONWakeUpSig : 1|1@0+ (1,0) [0|1] ""  GW
 SG_ VCU_FCWakeUpSig : 2|1@0+ (1,0) [0|1] ""  GW
 SG_ VCU_SCWakeUpSig : 3|1@0+ (1,0) [0|1] ""  GW
 SG_ VCU_RemWakeUpSig : 4|1@0+ (1,0) [0|1] ""  GW
 SG_ VCU_NetWakeUpSig : 5|1@0+ (1,0) [0|1] ""  GW
 SG_ VCU_LVWakeUpSts_PDU : 6|1@0+ (1,0) [0|1] ""  GW
 SG_ VCU_VehEOLFctFlg : 7|1@0+ (1,0) [0|1] ""  GW
 SG_ VCU_LVWakeUpSts_MCU : 8|1@0+ (1,0) [0|1] ""  GW
 SG_ VCU_PwrAntithefAllwtRdyFlg : 9|1@0+ (1,0) [0|1] ""  GW
 SG_ VCU_LVWakeUpSts_CCU : 10|1@0+ (1,0) [0|1] ""  GW
 SG_ VCU_RemECCEndCmd : 11|1@0+ (1,0) [0|1] ""  GW
 SG_ VCU_EvChrgElectcLockCtrlCmd : 13|2@0+ (1,0) [0|3] ""  GW,OBC
 SG_ VCU_RemPwrBattHeatgEndCmd : 14|1@0+ (1,0) [0|1] ""  GW
 SG_ VCU_RemChrgEndCmd : 15|1@0+ (1,0) [0|1] ""  GW
 SG_ VCU_V2L_TrAvl : 16|1@0+ (1,0) [0|1] ""  GW
 SG_ VCU_RemBattHeatgFailReason : 19|3@0+ (1,0) [0|7] ""  GW
 SG_ VCU_RemECCEndReason : 22|3@0+ (1,0) [0|7] ""  GW
 SG_ VCU_V2L_ChrgPortAvl : 23|1@0+ (1,0) [0|1] ""  GW
 SG_ VCU_RemChrgEndReason : 26|3@0+ (1,0) [0|7] ""  GW
 SG_ VCU_SchedChrgnStsFb : 28|2@0+ (1,0) [0|3] ""  GW
 SG_ VCU_V2V_Avl : 29|1@0+ (1,0) [0|1] ""  GW
 SG_ VCU_V2H_Avl : 30|1@0+ (1,0) [0|1] ""  GW
 SG_ VCU_V2G_Avl : 31|1@0+ (1,0) [0|1] ""  GW
 SG_ VCU_VehMod : 39|4@0+ (1,0) [0|15] ""  BMS,ECC,GW,OBC
 SG_ VCU_VehCrtChrgEndSOC : 46|7@0+ (1,0) [0|100] "%"  BMS,GW
 SG_ VCU_CalSwVers : 52|5@0+ (1,0) [0|31] ""  GW
 SG_ VCU_RemPwrBattPreheatgEndFlg : 53|1@0+ (1,0) [0|1] ""  GW
 SG_ VCU_VehOperMod : 60|5@0+ (1,0) [0|31] ""  GW
 SG_ VCU_VehRemRefrshModReq : 62|2@0+ (1,0) [0|3] ""  BMS,ECC,GW,OBC
 SG_ VCU_RemDTCPwrOnReq : 63|1@0+ (1,0) [0|1] ""  ECC,GW

BO_ 1329 ICC_0x531: 8 GW
 SG_ ICC_TotMilgVld_ODO : 0|1@0+ (1,0) [0|1] ""  BMS,ECC,OBC,VCU
 SG_ ICC_TotMilg_ODO : 11|28@0+ (0.01,0) [0|2000000] "km"  BMS,ECC,OBC,VCU
 SG_ ICC_DispVehSpd : 47|8@0+ (1,0) [0|255] ""  ECC,VCU
 SG_ ICC_DispVehSpdUnit : 48|1@0+ (1,0) [0|1] ""  ECC,VCU
 SG_ ICC_ADASSigFlt : 50|2@0+ (1,0) [0|3] ""  ECC
 SG_ ICC_DispFlt : 51|1@0+ (1,0) [0|1] ""  ECC,VCU
 SG_ ICC_WorkshopMode : 55|2@0+ (1,0) [0|3] ""  ECC,VCU

BO_ 1429 BMS_ChargingTime: 8 BMS
 SG_ BMS_RmChrgTi_FullChrg : 7|16@0+ (1,0) [0|65535] "min"  GW,VCU
 SG_ BMS_RmChrgTi_TrgtSoC : 23|16@0+ (1,0) [0|65535] "min"  GW,VCU

BO_ 1476 TBOX_0x5C4: 16 GW
 SG_ TBOX_OTA_ownCondchk : 1|2@0+ (1,0) [0|3] ""  BMS,ECC,OBC,VCU
 SG_ TBOX_TerminalRemWakeupSig : 2|1@0+ (1,0) [0|1] ""  VCU
 SG_ TBOX_RemSCModReq : 4|2@0+ (1,0) [0|3] ""  VCU
 SG_ TBOX_RemPwrBattOpenHeatgReq : 6|2@0+ (1,0) [0|3] ""  ECC,VCU
 SG_ TBOX_RemPwrBattResvHeatgReq : 7|1@0+ (1,0) [0|1] ""  ECC,VCU
 SG_ TBOX_RemInsdInfoDispEna : 12|1@0+ (1,0) [0|1] ""  EVBUS_Virtual_ECU
 SG_ TBOX_RemECCDefrstModReq : 14|2@0+ (1,0) [0|3] ""  ECC,VCU
 SG_ TBOX_RemECCResvDefrstReq : 15|1@0+ (1,0) [0|1] ""  ECC
 SG_ TBOX_RemECCSetT : 31|8@0+ (0.5,0) [0|127.5] "Degree Celsius"  ECC,VCU
 SG_ TBOX_RemResvECCSetT : 39|8@0+ (0.5,0) [0|127.5] "Degree Celsius"  ECC
 SG_ TBOX_RemSOCMax : 47|8@0+ (1,0) [0|100] ""  ECC,VCU
 SG_ TBOX_4GSigIND : 49|2@0+ (1,0) [0|3] ""  EVBUS_Virtual_ECU
 SG_ TBOX_Conn_Typ : 52|3@0+ (1,0) [0|7] ""  EVBUS_Virtual_ECU
 SG_ TBOX_TSPNotConn : 53|1@0+ (1,0) [0|1] ""  EVBUS_Virtual_ECU
 SG_ TBOX_EHUNotCONN : 54|1@0+ (1,0) [0|1] ""  EVBUS_Virtual_ECU
 SG_ TBOX_WIFIError : 55|1@0+ (1,0) [0|1] ""  EVBUS_Virtual_ECU
 SG_ TBOX_InnerBattError : 56|1@0+ (1,0) [0|1] ""  EVBUS_Virtual_ECU
 SG_ TBOX_VoltLow : 57|1@0+ (1,0) [0|1] ""  EVBUS_Virtual_ECU
 SG_ TBOX_VoltHigh : 58|1@0+ (1,0) [0|1] ""  EVBUS_Virtual_ECU
 SG_ TBOX_4GLoss : 59|1@0+ (1,0) [0|1] ""  EVBUS_Virtual_ECU
 SG_ TBOX_RemSWH_Req : 61|2@0+ (1,0) [0|3] ""  EVBUS_Virtual_ECU
 SG_ TBOX_OTAInhbReq : 63|2@0+ (1,0) [0|3] ""  VCU
 SG_ TBOX_5C4_SSecOC_Fresh_Byte0 : 71|8@0+ (1,0) [0|255] ""  ECC,VCU
 SG_ TBOX_5C4_SSecOC_MAC_Byte0 : 79|8@0+ (1,0) [0|255] ""  ECC,VCU
 SG_ TBOX_5C4_SSecOC_MAC_Byte1 : 87|8@0+ (1,0) [0|255] ""  ECC,VCU
 SG_ TBOX_5C4_SSecOC_MAC_Byte2 : 95|8@0+ (1,0) [0|255] ""  ECC,VCU

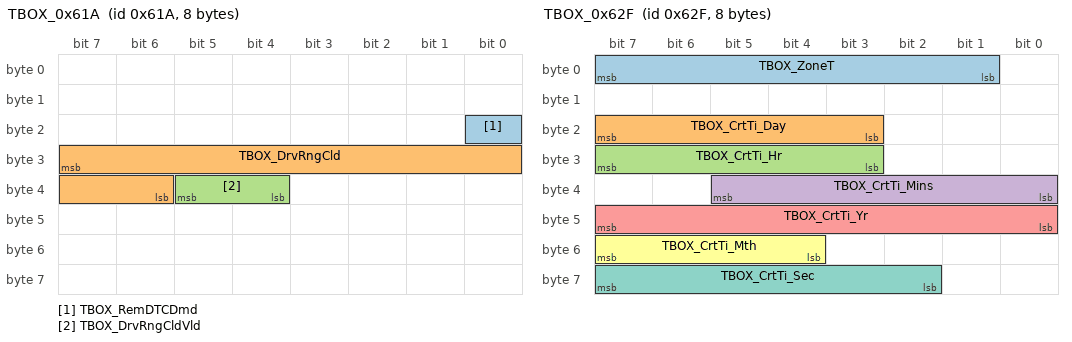
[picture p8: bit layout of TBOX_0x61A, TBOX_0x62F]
BO_ 1562 TBOX_0x61A: 8 GW
 SG_ TBOX_RemDTCDmd : 16|1@0+ (1,0) [0|1] ""  VCU
 SG_ TBOX_DrvRngCld : 31|10@0+ (1,0) [0|1000] "km"  VCU
 SG_ TBOX_DrvRngCldVld : 37|2@0+ (1,0) [0|3] ""  VCU

BO_ 1583 TBOX_0x62F: 8 GW
 SG_ TBOX_ZoneT : 7|7@0+ (15,-720) [-720|1185] "min"  ECC,EVBUS_Virtual_ECU
 SG_ TBOX_CrtTi_Day : 23|5@0+ (1,1) [1|31] "day"  BMS,ECC,OBC,VCU
 SG_ TBOX_CrtTi_Hr : 31|5@0+ (1,0) [0|23] "hour"  BMS,ECC,OBC,VCU
 SG_ TBOX_CrtTi_Mins : 37|6@0+ (1,0) [0|59] "mintue"  BMS,ECC,OBC,VCU
 SG_ TBOX_CrtTi_Yr : 47|8@0+ (1,2015) [2015|2270] "year"  BMS,ECC,OBC,VCU
 SG_ TBOX_CrtTi_Mth : 55|4@0+ (1,1) [1|12] "month"  BMS,ECC,OBC,VCU
 SG_ TBOX_CrtTi_Sec : 63|6@0+ (1,0) [0|59] "second"  BMS,ECC,OBC,VCU

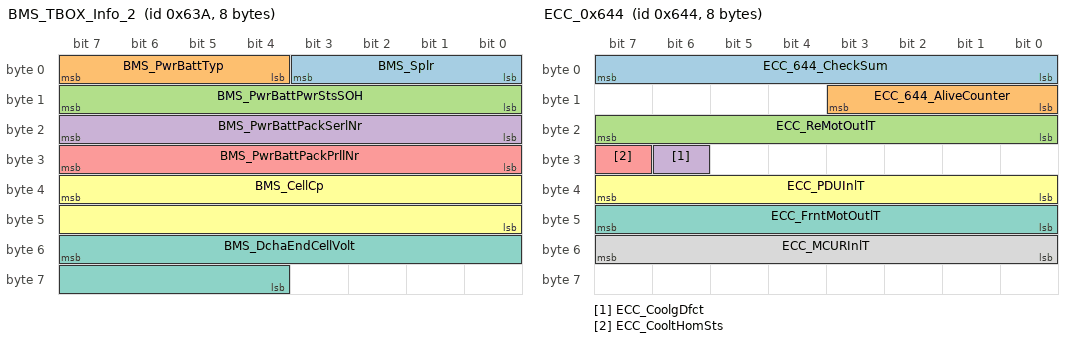
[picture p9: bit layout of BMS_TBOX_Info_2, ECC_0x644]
BO_ 1594 BMS_TBOX_Info_2: 8 BMS
 SG_ BMS_Splr : 3|4@0+ (1,0) [0|15] ""  GW,VCU
 SG_ BMS_PwrBattTyp : 7|4@0+ (1,0) [0|15] ""  GW,VCU
 SG_ BMS_PwrBattPwrStsSOH : 15|8@0+ (0.01,0) [0|2.55] "KW"  GW
 SG_ BMS_PwrBattPackSerlNr : 23|8@0+ (1,0) [0|255] ""  GW,VCU
 SG_ BMS_PwrBattPackPrllNr : 31|8@0+ (1,0) [0|255] ""  GW,VCU
 SG_ BMS_CellCp : 39|16@0+ (0.1,0) [0|6553.5] "Ah"  GW,VCU
 SG_ BMS_DchaEndCellVolt : 55|12@0+ (0.01,0) [0|25.5] "V"  GW,VCU

BO_ 1604 ECC_0x644: 8 ECC
 SG_ ECC_644_CheckSum : 7|8@0+ (1,0) [0|255] ""  GW,VCU
 SG_ ECC_644_AliveCounter : 11|4@0+ (1,0) [0|14] ""  GW,VCU
 SG_ ECC_ReMotOutlT : 23|8@0+ (1,-48) [-48|207] "Degree Celsius"  GW,VCU
 SG_ ECC_CoolgDfct : 30|1@0+ (1,0) [0|1] ""  BMS,GW,VCU
 SG_ ECC_CooltHomSts : 31|1@0+ (1,0) [0|1] ""  BMS,GW,VCU
 SG_ ECC_PDUInlT : 39|8@0+ (1,-48) [-48|207] "Degree Celsius"  GW,VCU
 SG_ ECC_FrntMotOutlT : 47|8@0+ (1,-48) [-48|207] "Degree Celsius"  GW,VCU
 SG_ ECC_MCURInlT : 55|8@0+ (1,-48) [-48|207] "Degree Celsius"  GW,VCU

CM_ SG_ 759 BMS_Bat_C_MaxCell_U "maximum cell voltage which is allowed in charge direction ";
CM_ SG_ 759 BMS_Bat_D_MinCell_U "minimum cell voltage level, which is allowed in discharge";
CM_ SG_ 759 BMS_Bat_D_MaxPack_I " maximum allowed current in discharge direction (depends on temperature)";
CM_ SG_ 759 BMS_Bat_C_MaxPack_I "maximum allowed current in charge direction (depends on temperature) When vehicle driving, this signal is used as a recharging (recuperation) current limit";
CM_ SG_ 760 BMS_Volt_PLT_CheckSum "CheckSum(E2E data ID: 0x89)";
CM_ SG_ 760 BMS_Volt_PLT_AliveCounter "Rolling counter";
CM_ SG_ 760 BMS_Bat_C_MAXvolt_PLT "predicted charge REESS voltage for long time [300s value]";
CM_ SG_ 760 BMS_Bat_D_MAXvolt_PLT "predicted discharge REESS voltage for long time [300s value]";
CM_ SG_ 792 ESP_318_CheckSum "ESP318_Message Checksum ( E2E data ID: 0x79)";
CM_ SG_ 792 ESP_318_AliveCounter "ESP 3318_Message counterESP_318_AliveCounter";
CM_ SG_ 792 ESP_BrkPedlStsVld "Effective position of brake pedal state validity of BRAKE_STATUS_ESP.";
CM_ SG_ 792 ESP_BrkPedlSts "Brake pedal state indicating brake pedal activated by driver or not.";
CM_ SG_ 792 ESP_VehSpdVld "ABS_ESC signal indicates whether the vehicle speed is valid When the diagnostic have set the failure code on this signal the value wil be 2.";
CM_ SG_ 792 ESP_SysActv "ESP works effectively Is used to indicate to the driver that the system is currently active. Not used for ABS.";
CM_ SG_ 792 ESP_LampSwtOffIndcn "ESP OFF indication Signal indicates to light up 'TCS/ESP off' lamp.-manual switch off of ESP function (on/off switch).Not used for ABS.";
CM_ SG_ 792 ESP_FltIndcn_EBD "EBD fault indication Signal indicates to light up EBD lamp.";
CM_ SG_ 792 ESP_FltIndcn_ABS "ABS fault indication Signal indicates to light up ABS lamp.";
CM_ SG_ 792 ESP_MilgRollgCntr_ODO "Mileage statistical pulse Odometer rolling count 1 pulse/bit. The value shall be set to zero at every ignition off and if the counter reach max value it starts from zero again.";
CM_ SG_ 792 ESP_VehSpd "Speed signal";
CM_ SG_ 792 ESP_IninModSigIndcn "The signal needs to cover the time of ESP and ABS fault signals caused by self-inspection. Signal indicates if ESP or ABS is in initialization mode or not.";
CM_ SG_ 792 ESP_FltIndcn_TCS "ESP/TCS fault indication Signal indicates failure monitoring of ESP function. Not used for ABS";
CM_ SG_ 792 ESP_CtrlSts_HDC "Indicate that the HDC is on/off or working, and the ADAS receives this signal to determine whether the ACC is off. HDC control(Off/On, not active braking/On, active braking).";
CM_ SG_ 792 ESP_AvlIndcn_HDC "Effective bit of HDC indicating HDC is available or not.";
CM_ SG_ 792 ESP_NoBrkP "When the vehicle is stationary, whether the function has braking force or not, whether it is braking.no brake pressure applied; generally it regards wheel cylinder presure.";
CM_ SG_ 792 ESP_RDAEnaFlg "ESP remote driving function enable flag position";
CM_ SG_ 816 BMS_330_391_CheckSum "BMS_330_Message checksum (E2E data ID: 0x3F)";
CM_ SG_ 816 BMS_330_391_AliveCounter "BMS_330_AliveCounter";
CM_ SG_ 816 BMS_VehInsulFltDisp "Vehicle insulation fault display";
CM_ SG_ 816 BMS_PwrBattSysFltDisp "Power battery system fault display";
CM_ SG_ 816 BMS_PwrBattRmngCpSOC "Remaining SOC";
CM_ SG_ 816 BMS_PwrBattAvlCp "Power battery capacity in kWh";
CM_ SG_ 816 BMS_CellMinTAlrm "cell temperature too low";
CM_ SG_ 816 BMS_PwrBattThermRunawayAlrm "Thermal Runaway detected ";
CM_ SG_ 816 BMS_PwrBattOverT "cell temperature too high";
CM_ SG_ 816 BMS_PwrBattInsulSts "Traction battery insulation state";
CM_ SG_ 816 BMS_330_SSecOC_Fresh_Byte0 "Short SecOC Fresh signal byte 0 on CAN";
CM_ SG_ 816 BMS_330_SSecOC_MAC_Byte0 "Short SecOC MAC signal byte 0 on CAN";
CM_ SG_ 816 BMS_330_SSecOC_MAC_Byte1 "Short SecOC MAC signal byte 1 on CAN";
CM_ SG_ 816 BMS_330_SSecOC_MAC_Byte2 "Short SecOC MAC signal byte 2 on CAN";
CM_ SG_ 819 BCM_333_CheckSum "BCM333_message checksum ( 0xCB)BCM_333_CheckSum";
CM_ SG_ 819 BCM_333_AliveCounter "BCM333_Packet counterBCM_333_AliveCounter";
CM_ SG_ 819 BCM_KL15_Off_Announcement "Before switching off the KL15 (5s), this signal gets active to inform other ECUs that the KL15 will be disabled in 5seconds if there are still no triggers to keep it active";
CM_ SG_ 819 BCM_IG1Sts "IG1 state";
CM_ SG_ 819 BCM_PwrMod "Power mode";
CM_ SG_ 819 BCM_PwrModVld "Effective value of power mode";
CM_ SG_ 819 BCM_BrkSwtSts "Brake switch status";
CM_ SG_ 819 BCM_IG1StsVld_CAPE "Effective value of IG1 state";
CM_ SG_ 819 BCM_IG2StsVld_CAPE "Effective value of IG2 state";
CM_ SG_ 819 BCM_KL30s_L "Logical State of KL30";
CM_ SG_ 819 BCM_IG2Sts "IG2 state";
CM_ SG_ 819 BCM_InteriorSwtSt "Interior switch status from LIN1";
CM_ SG_ 856 VCU_358_CheckSum "VCU_0x358_Message Check (E2E data ID: 0x47)";
CM_ SG_ 856 VCU_358_AliveCounter "VCU_0x358_Message counter";
CM_ SG_ 856 VCU_KickdwnFlg "status of kickdown function ";
CM_ SG_ 856 VCU_EPedlEnaSig "E-Pedal enable signal (TBD if required)";
CM_ SG_ 856 VCU_ComLostFlt_ESP "VCU and ESP communication related faults";
CM_ SG_ 856 VCU_ComFlt_iBooster "VCU and iBooster communication failure_U101587_E03";
CM_ SG_ 856 VCU_RegenLvlFb "Coasting Mode settings (Off, Normal, high) feedback to ICC";
CM_ SG_ 856 VCU_AccelModFb "Acceleration Mode setting (Low/Mid/High) feedback to ICC";
CM_ SG_ 856 VCU_EPedlStsFb "Pedal Comport Setting (One Pedal Drive / Roll / Creep) feedback to ICC";
CM_ SG_ 856 VCU_CcTrgSpdDisp "Cruise Control Target Speed display";
CM_ SG_ 856 VCU_Sts_CC_ICC "ACC status";
CM_ SG_ 856 VCU_CCIconDisp "ACC icon color";
CM_ SG_ 856 VCU_DispSpdUnit_CC "CC display speed unit";
CM_ SG_ 856 VCU_BoostEnStat "Boost Enable Status";
CM_ SG_ 856 VCU_OTARdy_Fb "VCU OTA ready status feedback";
CM_ SG_ 856 VCU_OTA_ECUInhb_Req "VCU OTA inhibit request to ECUs";
CM_ SG_ 856 VCU_OTAVehCdnChk_ASIL "ASIL A group OTA vehicle condition check status";
CM_ SG_ 856 VCU_OTAVehInhb_ASIL_Fb "ASIL A group OTA vehicle Inhibit feedback";
CM_ SG_ 864 BMS_PwrBattPosGNDInsulRrel "Relative Insulation resistance of positive pole of traction battery to GND";
CM_ SG_ 864 BMS_PwrBattNegGNDInsulRrel "Relative Insulation resistance of negative pole of traction battery to GND";
CM_ SG_ 864 BMS_PwrBattPosGNDInsulR "Insulation resistance of positive pole of traction battery to GND";
CM_ SG_ 864 BMS_PwrBattNegGNDInsulR "Insulation resistance of negative pole of traction battery to GND";
CM_ SG_ 882 BMS_372_382_CheckSum "BMS_372_Message checksum (E2E data ID: 0x1C); ";
CM_ SG_ 882 BMS_372_382_AliveCounter "BMS_372 _Message counterBMS_372_AliveCounter";
CM_ SG_ 882 BMS_OTARdy_Fb "BMS OTA ready status feedback";
CM_ SG_ 882 BMS_CellMinT "Minimum temperature of single cell";
CM_ SG_ 882 BMS_CellDiffT "Single cell temperature range";
CM_ SG_ 882 BMS_CellMaxT "Maximum temperature of single cell";
CM_ SG_ 882 BMS_BattAvrgT "Average temperature of battery pack";
CM_ SG_ 882 BMS_PwrBattHeatgMngDmd "Power battery thermal management requirements";
CM_ SG_ 882 BMS_ECCSysAllwDwnPwrCmd "Allowable power reduction instruction of A/C system";
CM_ SG_ 882 BMS_BattInlTDmd "Water inlet temperature requirements of battery pack";
CM_ SG_ 882 BMS_372_SSecOC_Fresh_Byte0 "Short SecOC Fresh signal byte 0 on CAN";
CM_ SG_ 882 BMS_372_SSecOC_MAC_Byte0 "Short SecOC MAC signal byte 0 on CAN";
CM_ SG_ 882 BMS_372_SSecOC_MAC_Byte1 "Short SecOC MAC signal byte 1 on CAN";
CM_ SG_ 882 BMS_372_SSecOC_MAC_Byte2 "Short SecOC MAC signal byte 2 on CAN";
CM_ SG_ 883 ECC_CrtSts "ECC current state";
CM_ SG_ 883 ECC_IninSts "ECC initialization state";
CM_ SG_ 883 ECC_PwrSysHeatMngtSts "Power system thermal management state";
CM_ SG_ 883 ECC_ACSts "A/C state";
CM_ SG_ 883 ECC_AirClnSts "Air purification state";
CM_ SG_ 883 ECC_WindSpdSts "Wind speed state";
CM_ SG_ 883 ECC_BackRowAirOutlModSts "Rear exhaust mode state";
CM_ SG_ 883 ECC_DrvrTSetSts "Main driving temperature setting state";
CM_ SG_ 883 ECC_PassTSetSts "Temperature setting state of front passenger";
CM_ SG_ 883 ECC_HeatSts "HEAT state";
CM_ SG_ 883 ECC_AUTOSts "A/C AUTO state";
CM_ SG_ 883 ECC_SYNCSts "SYNC state";
CM_ SG_ 883 ECC_InfoSysWrmColdDisp "Display of heating and cooling degree of entertainment system";
CM_ SG_ 883 ECC_CircSts "Cycle state";
CM_ SG_ 883 ECC_ParticleConcVld "Effective position of particle concentration";
CM_ SG_ 883 ECC_OutdT "Ambient temperature outside the vehicle";
CM_ SG_ 883 ECC_OutdTVld "Effective position of ambient temperature outside vehicle";
CM_ SG_ 883 ECC_MaxFrntDefrst "Max Front defrosting";
CM_ SG_ 883 ECC_HeatMngtSysFlt "Fault of thermal management system";
CM_ SG_ 883 ECC_HeatMngtFctLim "Requirement for Thermal Management Function of Occupant Compartment";
CM_ SG_ 883 ECC_DrvrAirOutlMod "Driver Air Outlet Mode";
CM_ SG_ 883 ECC_PassAirOutlMod "Front passenger air-out mode";
CM_ SG_ 883 ECC_RemSts "Operating status of remote A/C";
CM_ SG_ 883 ECC_OTAInhbRdy "OTA pre-condition and Inhibiting of all OTA relevant ECUs";
CM_ SG_ 886 WTC_B_InlT "WTC_B inlet temperature";
CM_ SG_ 886 WTC_B_OutlT "WTC_B outlet temperature";
CM_ SG_ 886 WTC_B_CrtPwr "WTC_B current power";
CM_ SG_ 886 WTC_B_CrtT "WTC_B Current operating temperature";
CM_ SG_ 886 WTC_B_IninSts "WTC_B initialization state";
CM_ SG_ 886 WTC_B_HVPwrSplySts "WTC_B high voltage power supply state";
CM_ SG_ 886 WTC_B_ActGear "WTC_B Actual gear";
CM_ SG_ 886 WTC_B_Mod "WTC_B current operating mode";
CM_ SG_ 901 TBOX_PreHeatDepartTi1_Hr "Time for preheating_Hour";
CM_ SG_ 901 TBOX_PreHeatDepartTi1_Mins "Time for preheating_Minutes";
CM_ SG_ 901 TBOX_PreHeatDepartSet "Preheating depart set";
CM_ SG_ 901 TBOX_MonPreHeatDepartSet "Preheating depart set_Monday";
CM_ SG_ 901 TBOX_TuePreHeatDepartSet "Preheating depart set_Tuesday";
CM_ SG_ 901 TBOX_WedPreHeatDepartSet "Preheating depart set_Wednesday";
CM_ SG_ 901 TBOX_ThuPreHeatDepartSet "Preheating depart set_Thursday";
CM_ SG_ 901 TBOX_FriPreHeatDepartSet "Preheating depart set_Friday";
CM_ SG_ 901 TBOX_SatPreHeatDepartSet "Preheating depart set_Saturday";
CM_ SG_ 901 TBOX_SunPreHeatDepartSet "Preheating depart set_Sunday";
CM_ SG_ 901 TBOX_PreCdnTarT "the pre-conditioning time of a specific tagret temperature";
CM_ SG_ 901 TBOX_PreHeatDepartSetFb "feedback signal for PreHeating time schedule";
CM_ SG_ 901 TBOX_PreHeatDepartTi2_Hr "Time for preheating_Hour";
CM_ SG_ 901 TBOX_PreHeatDepartTi2_Mins "Time for preheating_Minutes";
CM_ SG_ 928 BMS_Cont_Error_StuckOpen_HV_Pos1 "Relay is Open (F)";
CM_ SG_ 928 BMS_Cont_Error_Welded_HV_Pos1 "Relay is Welded (F)";
CM_ SG_ 928 BMS_Cont_Error_Exceed_HV_Pos1 "One of the relay counters is exceeded (F)";
CM_ SG_ 928 BMS_Cont_Error_DisCh1_HV_Pos1 "Number of times contactor opened under high current load";
CM_ SG_ 928 BMS_Cont_Error_DisCh2_HV_Pos1 "Number of times contactor opened under really high current load";
CM_ SG_ 928 BMS_Cont_Error_DisCh3_HV_Pos1 "Number of times contactor opened under really high current load";
CM_ SG_ 928 BMS_Cont_Error_DisCh4_HV_Pos1 "Number of times contactor opened under really high current load";
CM_ SG_ 928 BMS_Cont_Error_Ch1_HV_Pos1 "Number of times contactor opened under really high current load";
CM_ SG_ 928 BMS_Cont_Error_Ch2_HV_Pos1 "Number of times contactor opened under really high current load";
CM_ SG_ 929 BMS_Cont_Error_StuckOpen_HV_Neg1 "Relay is Open (F)";
CM_ SG_ 929 BMS_Cont_Error_Welded_HV_Neg1 "Relay is Welded (F)";
CM_ SG_ 929 BMS_Cont_Error_Exceed_HV_Neg1 "One of the relay counters is exceeded (F)";
CM_ SG_ 929 BMS_Cont_Error_DisCh1_HV_Neg1 "Number of times contactor opened under high current load";
CM_ SG_ 929 BMS_Cont_Error_DisCh2_HV_Neg1 "Number of times contactor opened under really high current load";
CM_ SG_ 929 BMS_Cont_Error_DisCh3_HV_Neg1 "Number of times contactor opened under really high current load";
CM_ SG_ 929 BMS_Cont_Error_DisCh4_HV_Neg1 "Number of times contactor opened under really high current load";
CM_ SG_ 929 BMS_Cont_Error_Ch1_HV_Neg1 "Number of times contactor opened under really high current load";
CM_ SG_ 929 BMS_Cont_Error_Ch2_HV_Neg1 "Number of times contactor opened under really high current load";
CM_ SG_ 930 BMS_Cont_Error_StuckOpen_HV_Prec "Relay is Open (F)";
CM_ SG_ 930 BMS_Cont_Error_Welded_HV_Prec1 "Relay is Welded (F)";
CM_ SG_ 930 BMS_Cont_Error_Exceed_HV_Prec "One of the relay counters is exceeded (F)";
CM_ SG_ 930 BMS_Cont_Error_DisCh1_HV_Prec "Number of times contactor opened under high current load";
CM_ SG_ 930 BMS_Cont_Error_DisCh2_HV_Prec "Number of times contactor opened under really high current load";
CM_ SG_ 930 BMS_Cont_Error_DisCh3_HV_Prec "Number of times contactor opened under really high current load";
CM_ SG_ 930 BMS_Cont_Error_DisCh4_HV_Prec "Number of times contactor opened under really high current load";
CM_ SG_ 930 BMS_Cont_Error_Ch1_HV_Prec1 "Number of times contactor opened under really high current load";
CM_ SG_ 930 BMS_Cont_Error_Ch2_HV_Prec1 "Number of times contactor opened under really high current load";
CM_ SG_ 933 BMS_Bat_Coolant_in "Actual coolant REESS inlet temperature [Deg Cel]";
CM_ SG_ 933 BMS_Bat_Coolant_out "Actual coolant REESS outlet temperature [Deg Cel]";
CM_ SG_ 933 BMS_BattInlT_Target "Target Coolant inlet Temperature of battery";
CM_ SG_ 933 BMS_BattInlT_Min "Target Coolant inlet Minimum Temperature of battery";
CM_ SG_ 933 BMS_BattInlT_Max "Target Coolant inlet Maximum Temperature of battery";
CM_ SG_ 934 BMS_Cont_Error_StuckOpen_HV_PV_N "Relay is Open (F)";
CM_ SG_ 934 BMS_Cont_Error_Welded_HV_PV_Neg1 "Relay is Welded (F)";
CM_ SG_ 934 BMS_Cont_Error_Exceed_HV_PV_Neg1 "One of the relay counters is exceeded (F)";
CM_ SG_ 934 BMS_Cont_Error_DisCh1_HV_PV_Neg1 "Number of times contactor opened under high current load";
CM_ SG_ 934 BMS_Cont_Error_DisCh2_HV_PV_Neg1 "Number of times contactor opened under really high current load";
CM_ SG_ 934 BMS_Cont_Error_DisCh3_HV_PV_Neg1 "Number of times contactor opened under really high current load";
CM_ SG_ 934 BMS_Cont_Error_DisCh4_HV_PV_Neg1 "Number of times contactor opened under really high current load";
CM_ SG_ 934 BMS_Cont_Error_Ch1_HV_PV_Neg1 "Number of times contactor opened under really high current load";
CM_ SG_ 934 BMS_Cont_Error_Ch2_HV_PV_Neg1 "Number of times contactor opened under really high current load";
CM_ SG_ 935 BMS_Cont_Error_StuckOpen_HV_PV_P "Relay is Open (F)";
CM_ SG_ 935 BMS_Cont_Error_Welded_HV_PV_Pos1 "Relay is Welded (F)";
CM_ SG_ 935 BMS_Cont_Error_Exceed_HV_PV_Pos1 "One of the relay counters is exceeded (F)";
CM_ SG_ 935 BMS_Cont_Error_DisCh1_HV_PV_Pos1 "Number of times contactor opened under high current load";
CM_ SG_ 935 BMS_Cont_Error_DisCh2_HV_PV_Pos1 "Number of times contactor opened under really high current load";
CM_ SG_ 935 BMS_Cont_Error_DisCh3_HV_PV_Pos1 "Number of times contactor opened under really high current load";
CM_ SG_ 935 BMS_Cont_Error_DisCh4_HV_PV_Pos1 "Number of times contactor opened under really high current load";
CM_ SG_ 935 BMS_Cont_Error_Ch1_HV_PV_Pos1 "Number of times contactor opened under really high current load";
CM_ SG_ 935 BMS_Cont_Error_Ch2_HV_PV_Pos1 "Number of times contactor opened under really high current load";
CM_ SG_ 1140 TBOX_ICC_UpdSched "TBOX needs to inform ICC when that time arrives so that ICC can display the appropriate notification to the driver";
CM_ SG_ 1140 TBOX_OTAReq_BMS "OTA request on BMS (HV mode and HV light mode)";
CM_ SG_ 1140 TBOX_OTAReq_VCU "OTA request on VCU (HV mode and HV light mode)";
CM_ SG_ 1140 TBOX_OTAReq_ECC "OTA request on ECC (HV mode and HV light mode)";
CM_ SG_ 1140 TBOX_OTAReq_OBC "OTA request on OBC (HV mode and HV light mode)";
CM_ SG_ 1140 TBOX_OTAReq_MCU_F "OTA request on MCU_F (HV mode and HV light mode)";
CM_ SG_ 1140 TBOX_OTAReq_MCU_R "OTA request onMCU_R (HV mode and HV light mode)";
CM_ SG_ 1140 TBOX_OTAReq_ADAS "OTA request on ADAS (HV mode and HV light mode)";
CM_ SG_ 1140 TBOX_OTAReq_FCM "OTA request on FCM (HV mode and HV light mode)";
CM_ SG_ 1140 TBOX_OTAReq_GW "OTA request on GW (HV mode and HV light mode)";
CM_ SG_ 1140 TBOX_OTAReq_EPS "OTA request on EPS (HV mode and HV light mode)";
CM_ SG_ 1140 TBOX_OTAReq_ESP "OTA request on ESp (HV mode and HV light mode)";
CM_ SG_ 1140 TBOX_OTAReq_iBooster "OTA request on iBooster (HV mode and HV light mode)";
CM_ SG_ 1140 TBOX_OTAReq_SCM "OTA request on SCM (HV mode and HV light mode)";
CM_ SG_ 1140 TBOX_OTAReq_ICC "OTA request on ICC (HV mode and HV light mode)";
CM_ SG_ 1140 TBOX_OTAReq_OHC "OTA request on OHC (HV mode and HV light mode)";
CM_ SG_ 1140 TBOX_OTAReq_BCM "OTA request on BCM (HV mode and HV light mode)";
CM_ SG_ 1140 TBOX_OTAReq_CIM "OTA request on CIM (HV mode and HV light mode)";
CM_ SG_ 1140 TBOX_OTAReq_PKC "OTA request on PKC (HV mode and HV light mode)";
CM_ SG_ 1140 TBOX_OTAReq_PLGM "OTA request on PLGM (HV mode and HV light mode)";
CM_ SG_ 1140 TBOX_OTAReq_TRM "OTA request on TRM (HV mode and HV light mode)";
CM_ SG_ 1140 TBOX_OTAReq_DSMC "OTA request on DSMC (HV mode and HV light mode)";
CM_ SG_ 1140 TBOX_OTAReq_PSM "OTA request on PSM (HV mode and HV light mode)";
CM_ SG_ 1140 TBOX_OTAReq_VSP "OTA request on VSP (HV mode and HV light mode)";
CM_ SG_ 1140 TBOX_OTAReq_TBOX "OTA request on TBOX (HV mode and HV light mode)";
CM_ SG_ 1168 EAS_MotSpdVld "Effective position of compressor motor speed value";
CM_ SG_ 1168 EAS_CtrlrVoltVld "Effective bit of compressor controller voltage value";
CM_ SG_ 1168 EAS_CtrlrCrtVld "Effective current value of compressor controller";
CM_ SG_ 1168 EAS_CtrlrVolt "Compressor controller bus voltage";
CM_ SG_ 1168 EAS_CtrlrCrt "Compressor controller bus current";
CM_ SG_ 1168 EAS_MotSpd "Compressor motor speed";
CM_ SG_ 1169 EAS_MotCrt "Compressor motor current";
CM_ SG_ 1169 EAS_HVUnderVoltFlt "Compressor high pressure undervoltage fault_P166616_E00";
CM_ SG_ 1169 EAS_HVOverVoltFlt "Compressor high pressure overvoltage fault_P166517_E00";
CM_ SG_ 1169 EAS_CrtSts "EAS current state";
CM_ SG_ 1169 EAS_IninSts "EAS initialization state";
CM_ SG_ 1169 EAS_OverCrtFlt "Compressor overcurrent fault_P166719_E00";
CM_ SG_ 1169 EAS_HVIntlkFlt "High pressure interlock failure of compressor_P166F94_E00";
CM_ SG_ 1169 EAS_IPMTOverFlt "Compressor IPM overtemperature fault_P166098_E00";
CM_ SG_ 1169 EAS_ComLost_ECC "Lost communication between EAS and ECC_U170187_E00";
CM_ SG_ 1169 EAS_CtrlCircFlt "Compressor control circuit faulty_P166909_E00";
CM_ SG_ 1169 EAS_IPMHwFlt "Compressor IPM hardware faulty_P166200_E00";
CM_ SG_ 1169 EAS_IPMT "Compressor IPM temperature";
CM_ SG_ 1169 EAS_CrtPwr "Compressor current power";
CM_ SG_ 1268 TBOX_4F4_4F8_CheckSum "TBOX_4F8_message checksum ( E2E data ID:0xC2 )";
CM_ SG_ 1268 TBOX_4F4_4F8_AliveCounter "TBOX_4F8_message counter";
CM_ SG_ 1268 TBOX_Flsflg "TBOX Flash flag";
CM_ SG_ 1268 TBOX_FobdGWPartBUSUDSCom "Forbidden UDS communication of some network segments of GW";
CM_ SG_ 1268 TBOX_RemChrgInsulFctReq "Remote charging insulation function request";
CM_ SG_ 1268 TBOX_EHUSetTrvlMod "TBOX Setup Travel Mode";
CM_ SG_ 1268 TBOX_ResvACChrgOpenSts "TBOX reservation AC charging on state";
CM_ SG_ 1268 TBOX_RemKL15PwrOnReq "TBOX remote KL15 power-on request";
CM_ SG_ 1268 TBOX_SetChrgEndSOC "TBOX Set charge cut-off SOC value";
CM_ SG_ 1268 TBOX_PreCondTriggerReq "TBOX sends a trigger [PreCondTrigger] to start pre-conditioning to VCU";
CM_ SG_ 1268 TBOX_BlowLvlReq "TBOX send blowlevel to ECC";
CM_ SG_ 1268 TBOX_VehiMod "Vehicle Mode(TBD)";
CM_ SG_ 1268 TBOX_Crash_cfm "Crash comfirm signal from TBOX to ESP.";
CM_ SG_ 1268 TBOX_SchedChrgnReq "TBOX send the Scheduled Charging Request to VCU";
CM_ SG_ 1268 TBOX_4F4_SSecOC_Fresh_Byte0 "Short SecOC Fresh signal byte 0 on CAN";
CM_ SG_ 1268 TBOX_4F4_SSecOC_MAC_Byte0 "Short SecOC MAC signal byte 0 on CAN";
CM_ SG_ 1268 TBOX_4F4_SSecOC_MAC_Byte1 "Short SecOC MAC signal byte 1 on CAN";
CM_ SG_ 1268 TBOX_4F4_SSecOC_MAC_Byte2 "Short SecOC MAC signal byte 2 on CAN";
CM_ SG_ 1273 TBOX_OTAResFb "OTA flash finished result feedback";
CM_ SG_ 1273 TBOX_SpdLim "Signal which set the speed limit on ICC";
CM_ SG_ 1273 TBOX_OTA_TiRng "TBOX OTA flash Time range to ICC";
CM_ SG_ 1287 VCU_OTAVehInhb_QM_Fb "QM group OTA vehicle Inhibit feedback";
CM_ SG_ 1287 VCU_OTAVehCdnChk_QM_sts "QM group OTA vehicle condition check status";
CM_ SG_ 1287 VCU_DrvAvl "Driving effective";
CM_ SG_ 1287 VCU_CllsnSigSts "Impact signal state_P103C00_E03";
CM_ SG_ 1287 VCU_VehSts_GB "Vehicle state (national standard)";
CM_ SG_ 1287 VCU_MCUOverTFlt_GB "MCU over-temperature fault (national standard)";
CM_ SG_ 1287 VCU_DrvrMotOverTFlt_GB "Over temperature fault of driving motor (national standard)";
CM_ SG_ 1287 VCU_SOCTooLoAlrm "Alarm if SOC is too low_P101221_E00";
CM_ SG_ 1287 VCU_SOCJumpAlrm "SOC jump alarming_P101327_E00";
CM_ SG_ 1287 VCU_PwrBattPackMismatAlrm "Power pack mismatch alarming_P101101_E00";
CM_ SG_ 1287 VCU_SOCTooHiAlrm "Overhigh SOC alarm_P101222_E00";
CM_ SG_ 1287 VCU_DCDCEnaCmd "DCDC Enable Command";
CM_ SG_ 1287 VCU_PwrBattECCEnaCmd "Power battery air conditioning system enable command";
CM_ SG_ 1287 VCU_MstRlyCtrlCmd "VCU main relay control command";
CM_ SG_ 1287 VCU_DCDCOutpVoltCmd "DCDC output voltage command";
CM_ SG_ 1287 VCU_CCCnctnVolt "CC connection voltage value";
CM_ SG_ 1287 VCU_GearSig_GB "Gear signal (national standard)";
CM_ SG_ 1287 VCU_DrvrMotNr_GB "Number of driving motors (national standard)";
CM_ SG_ 1287 VCU_BattVolt "Battery voltage";
CM_ SG_ 1297 VCU_BMSLVWakeUpSts "BMS low-voltage wake-up state";
CM_ SG_ 1297 VCU_ONWakeUpSig "ON gear wake-up signal";
CM_ SG_ 1297 VCU_FCWakeUpSig "Fast charging wake-up signal";
CM_ SG_ 1297 VCU_SCWakeUpSig "Slow charging wake-up signal";
CM_ SG_ 1297 VCU_RemWakeUpSig "Remote wake-up signal";
CM_ SG_ 1297 VCU_NetWakeUpSig "Network wake-up signal";
CM_ SG_ 1297 VCU_LVWakeUpSts_PDU "Low-voltage wake-up state of PDU";
CM_ SG_ 1297 VCU_VehEOLFctFlg "Vehicle EOL function flag position";
CM_ SG_ 1297 VCU_LVWakeUpSts_MCU "MCU low-voltage wake-up state";
CM_ SG_ 1297 VCU_PwrAntithefAllwtRdyFlg "Power anti-theft allowable READY flag position";
CM_ SG_ 1297 VCU_LVWakeUpSts_CCU "CCU low-voltage wake-up state";
CM_ SG_ 1297 VCU_RemECCEndCmd "Remote A/C end instruction";
CM_ SG_ 1297 VCU_EvChrgElectcLockCtrlCmd "EV charge inlet electronic lock command";
CM_ SG_ 1297 VCU_RemPwrBattHeatgEndCmd "Remote traction battery heating end command";
CM_ SG_ 1297 VCU_RemChrgEndCmd "Remote charging end command";
CM_ SG_ 1297 VCU_V2L_TrAvl "V2L Trunk Available from VCU";
CM_ SG_ 1297 VCU_RemBattHeatgFailReason "Failure reason of remote battery heating";
CM_ SG_ 1297 VCU_RemECCEndReason "End reason of remote A/C";
CM_ SG_ 1297 VCU_V2L_ChrgPortAvl "V2L Charge Port Available";
CM_ SG_ 1297 VCU_RemChrgEndReason "End reason of remote charging";
CM_ SG_ 1297 VCU_SchedChrgnStsFb "VCU Feedback the scheduled Charging progress/status to TBOX";
CM_ SG_ 1297 VCU_V2V_Avl "VCU_V2VAvailable";
CM_ SG_ 1297 VCU_V2H_Avl "VCU_V2HAvailable";
CM_ SG_ 1297 VCU_V2G_Avl "VCU_V2GAvailable";
CM_ SG_ 1297 VCU_VehMod "Vehicle mode";
CM_ SG_ 1297 VCU_VehCrtChrgEndSOC "Vehicle current charging cutoff SOC value";
CM_ SG_ 1297 VCU_CalSwVers "VCU calibration software version number";
CM_ SG_ 1297 VCU_RemPwrBattPreheatgEndFlg "The remote traction battery preheating end flag";
CM_ SG_ 1297 VCU_VehOperMod "Vehicle operation condition";
CM_ SG_ 1297 VCU_VehRemRefrshModReq "Vehicle remote flashing mode requirements";
CM_ SG_ 1297 VCU_RemDTCPwrOnReq "Remote diagnosis of power-on demand";
CM_ SG_ 1329 ICC_TotMilgVld_ODO "Effective bit of ODO total mileage";
CM_ SG_ 1329 ICC_TotMilg_ODO "ODO total mileage";
CM_ SG_ 1329 ICC_DispVehSpd "Display speed";
CM_ SG_ 1329 ICC_DispVehSpdUnit "Display vehicle speed unit";
CM_ SG_ 1329 ICC_ADASSigFlt "Instrument ADAS signal fault";
CM_ SG_ 1329 ICC_DispFlt "Instrument display failure";
CM_ SG_ 1329 ICC_WorkshopMode "Setting by customer over display before he wants to tow the vehicle (=Rescue (Workshop Mode)";
CM_ SG_ 1429 BMS_RmChrgTi_FullChrg "Remaining charge time to 100% (full charge)SoC)";
CM_ SG_ 1429 BMS_RmChrgTi_TrgtSoC "Remaining charge time to desired target SOC";
CM_ SG_ 1476 TBOX_OTA_ownCondchk "TBOX request ECUs to check own conditions for OTA";
CM_ SG_ 1476 TBOX_TerminalRemWakeupSig "Terminal remote wake-up signal";
CM_ SG_ 1476 TBOX_RemSCModReq "Remote charging mode request

";
CM_ SG_ 1476 TBOX_RemPwrBattOpenHeatgReq "Remote traction battery ON heating request";
CM_ SG_ 1476 TBOX_RemPwrBattResvHeatgReq "Remote traction battery heating reservation request";
CM_ SG_ 1476 TBOX_RemInsdInfoDispEna "Remote interior information display enabling";
CM_ SG_ 1476 TBOX_RemECCDefrstModReq "A/C defrosting mode request";
CM_ SG_ 1476 TBOX_RemECCResvDefrstReq "Remote A/C Reservation Defrosting Request";
CM_ SG_ 1476 TBOX_RemECCSetT "Remote A/C set temperature value";
CM_ SG_ 1476 TBOX_RemResvECCSetT "Reserved A/C set temperature value remotely";
CM_ SG_ 1476 TBOX_RemSOCMax "User setting of remote power battery heating cutoff SOC value";
CM_ SG_ 1476 TBOX_4GSigIND "4 G signal strength indication";
CM_ SG_ 1476 TBOX_TSPNotConn "Cannot connect to TSP";
CM_ SG_ 1476 TBOX_EHUNotCONN "Fault of USB communication with audio and entertainment system";
CM_ SG_ 1476 TBOX_WIFIError "WIFI fault";
CM_ SG_ 1476 TBOX_InnerBattError "Built-in battery fault";
CM_ SG_ 1476 TBOX_VoltLow "Low voltage fault";
CM_ SG_ 1476 TBOX_VoltHigh "Overvoltage fault";
CM_ SG_ 1476 TBOX_4GLoss "4 G signal loss fault";
CM_ SG_ 1476 TBOX_RemSWH_Req "Remote Function Steering Wheel Heating Request";
CM_ SG_ 1476 TBOX_OTAInhbReq "TBOX request inhibit function to VCU";
CM_ SG_ 1476 TBOX_5C4_SSecOC_Fresh_Byte0 "Short SecOC Fresh signal byte 0 on CAN";
CM_ SG_ 1476 TBOX_5C4_SSecOC_MAC_Byte0 "Short SecOC MAC signal byte 0 on CAN";
CM_ SG_ 1476 TBOX_5C4_SSecOC_MAC_Byte1 "Short SecOC MAC signal byte 1 on CAN";
CM_ SG_ 1476 TBOX_5C4_SSecOC_MAC_Byte2 "Short SecOC MAC signal byte 2 on CAN";
CM_ SG_ 1562 TBOX_RemDTCDmd "Remote diagnosis requirement";
CM_ SG_ 1562 TBOX_DrvRngCld "Driving range prediction from the cloud service";
CM_ SG_ 1562 TBOX_DrvRngCldVld "Valid flag of signal TBOX_DrivRangeCld";
CM_ SG_ 1583 TBOX_CrtTi_Day "Current time_day";
CM_ SG_ 1583 TBOX_CrtTi_Hr "Current time_hour";
CM_ SG_ 1583 TBOX_CrtTi_Mins "Current time_min";
CM_ SG_ 1583 TBOX_CrtTi_Yr "Current time_year";
CM_ SG_ 1583 TBOX_CrtTi_Mth "Current time_month";
CM_ SG_ 1583 TBOX_CrtTi_Sec "Current time_seconds";
CM_ SG_ 1594 BMS_Splr "Power battery supplier";
CM_ SG_ 1594 BMS_PwrBattTyp "Power battery type";
CM_ SG_ 1594 BMS_PwrBattPwrStsSOH "Traction battery power state SOH";
CM_ SG_ 1594 BMS_PwrBattPackSerlNr "series number of traction battery PACK";
CM_ SG_ 1594 BMS_PwrBattPackPrllNr "Traction battery PACK parallel number";
CM_ SG_ 1594 BMS_CellCp "Single cell capacity";
CM_ SG_ 1594 BMS_DchaEndCellVolt "Discharge cut-off monomer voltage value";
CM_ SG_ 1604 ECC_644_CheckSum "ECC_644_Message checksum (E2E data ID: 0x14)";
CM_ SG_ 1604 ECC_644_AliveCounter "ECC_644_Message Counter";
CM_ SG_ 1604 ECC_ReMotOutlT "Rear motor outlet water temperature";
CM_ SG_ 1604 ECC_CoolgDfct "ECC HVB Thermal status:cooling defect";
CM_ SG_ 1604 ECC_CooltHomSts "?Coolant homogenisation status";
CM_ SG_ 1604 ECC_PDUInlT "Water temperature at PDU inlet";
CM_ SG_ 1604 ECC_FrntMotOutlT "Water temperature at front motor outlet";
CM_ SG_ 1604 ECC_MCURInlT "MCU_R inlet temperature";
BA_DEF_ SG_  "sigExplanation" STRING ;
BA_DEF_ SG_  "sigConfig" STRING ;
BA_DEF_ SG_  "sigSecLevel" STRING ;
BA_DEF_ SG_  "GenSigSendType" ENUM  "Cyclic","OnWrite","OnWriteWithRepetition","OnChange","OnChangeWithRepetition","IfActive","IfActiveWithRepetition","NoSigSendType";
BA_DEF_ SG_  "GenSigInactiveValue" INT 0 0;
BA_DEF_ SG_  "GenSigStartValue" INT 0 0;
BA_DEF_ SG_  "GenSigCycleTime" INT 0 0;
BA_DEF_ BO_  "E2EP01DataId" INT 0 65535;
BA_DEF_ BO_  "E2EP01DataLength" INT 0 65535;
BA_DEF_ BO_  "GenMsgStartDelayTime" INT 0 65535;
BA_DEF_ BO_  "GenMsgILSupport" ENUM  "No","Yes";
BA_DEF_ BO_  "VFrameFormat" ENUM  "StandardCAN","ExtendedCAN","reserved","reserved","reserved","reserved","reserved","reserved","reserved","reserved","reserved","reserved","reserved","reserved","StandardCAN_FD","ExtendedCAN_FD";
BA_DEF_ BO_  "CANFD_BRS" ENUM  "0","1";
BA_DEF_ BO_  "GenMsgDelayTime" INT 0 0;
BA_DEF_ BO_  "GenMsgNrOfRepetition" INT 0 0;
BA_DEF_ BO_  "GenMsgCycleTimeFast" INT 0 0;
BA_DEF_ BO_  "SCP_FreshnessValueTxLength" INT 0 512;
BA_DEF_ BO_  "SCL_CryptographicMessageID" INT 0 65535;
BA_DEF_ BO_  "SCP_FreshnessValueLength" INT 0 512;
BA_DEF_ BO_  "SCP_FreshnessValueId" INT 0 65535;
BA_DEF_ BO_  "GenMsgCycleTime" INT 0 0;
BA_DEF_ BO_  "SCP_DataId" INT 0 65535;
BA_DEF_ BO_  "GenMsgSendType" ENUM  "Cyclic","NotUsed","NotUsed","NotUsed","NotUsed","NotUsed","NotUsed","IfActive","NoMsgSendType";
BA_DEF_ BO_  "SCP_AuthInfoTxLength" INT 0 512;
BA_DEF_ BO_  "SC_LinkPos" INT 0 65535;
BA_DEF_ BO_  "SC_Message" ENUM  "No","Yes","Yes, split message";
BA_DEF_ SG_  "SystemSignalLongSymbol" STRING ;
BA_DEF_REL_ BU_SG_REL_  "SC_Verification" ENUM  "No","Yes";
BA_DEF_DEF_  "sigExplanation" "";
BA_DEF_DEF_  "sigConfig" "";
BA_DEF_DEF_  "sigSecLevel" "";
BA_DEF_DEF_  "GenSigSendType" "Cyclic";
BA_DEF_DEF_  "GenSigInactiveValue" 0;
BA_DEF_DEF_  "GenSigStartValue" 0;
BA_DEF_DEF_  "GenSigCycleTime" 0;
BA_DEF_DEF_  "E2EP01DataId" 0;
BA_DEF_DEF_  "E2EP01DataLength" 0;
BA_DEF_DEF_  "GenMsgStartDelayTime" 0;
BA_DEF_DEF_  "GenMsgILSupport" "Yes";
BA_DEF_DEF_  "VFrameFormat" "StandardCAN";
BA_DEF_DEF_  "CANFD_BRS" "1";
BA_DEF_DEF_  "GenMsgDelayTime" 0;
BA_DEF_DEF_  "GenMsgNrOfRepetition" 0;
BA_DEF_DEF_  "GenMsgCycleTimeFast" 0;
BA_DEF_DEF_  "SCP_FreshnessValueTxLength" 0;
BA_DEF_DEF_  "SCL_CryptographicMessageID" 0;
BA_DEF_DEF_  "SCP_FreshnessValueLength" 0;
BA_DEF_DEF_  "SCP_FreshnessValueId" 0;
BA_DEF_DEF_  "GenMsgCycleTime" 0;
BA_DEF_DEF_  "SCP_DataId" 0;
BA_DEF_DEF_  "GenMsgSendType" "Cyclic";
BA_DEF_DEF_  "SCP_AuthInfoTxLength" 0;
BA_DEF_DEF_  "SC_LinkPos" 0;
BA_DEF_DEF_  "SC_Message" "No";
BA_DEF_DEF_REL_ "SC_Verification" "No";
BA_DEF_DEF_  "SystemSignalLongSymbol" "";
BA_ "GenMsgCycleTime" BO_ 759 100;
BA_ "VFrameFormat" BO_ 759 14;
BA_ "GenMsgCycleTime" BO_ 760 100;
BA_ "E2EP01DataLength" BO_ 760 64;
BA_ "E2EP01DataId" BO_ 760 137;
BA_ "VFrameFormat" BO_ 760 14;
BA_ "GenMsgCycleTime" BO_ 792 20;
BA_ "E2EP01DataLength" BO_ 792 64;
BA_ "E2EP01DataId" BO_ 792 121;
BA_ "VFrameFormat" BO_ 792 14;
BA_ "SC_Message" BO_ 816 1;
BA_ "SC_LinkPos" BO_ 816 64;
BA_ "SCP_AuthInfoTxLength" BO_ 816 24;
BA_ "SCP_DataId" BO_ 816 816;
BA_ "GenMsgCycleTime" BO_ 816 50;
BA_ "SCP_FreshnessValueId" BO_ 816 816;
BA_ "SCP_FreshnessValueLength" BO_ 816 64;
BA_ "SCL_CryptographicMessageID" BO_ 816 816;
BA_ "SCP_FreshnessValueTxLength" BO_ 816 8;
BA_ "E2EP01DataLength" BO_ 816 64;
BA_ "E2EP01DataId" BO_ 816 63;
BA_ "VFrameFormat" BO_ 816 14;
BA_ "GenMsgCycleTime" BO_ 819 50;
BA_ "E2EP01DataLength" BO_ 819 64;
BA_ "E2EP01DataId" BO_ 819 203;
BA_ "VFrameFormat" BO_ 819 14;
BA_ "GenMsgCycleTime" BO_ 856 100;
BA_ "E2EP01DataLength" BO_ 856 64;
BA_ "E2EP01DataId" BO_ 856 71;
BA_ "VFrameFormat" BO_ 856 14;
BA_ "GenMsgCycleTime" BO_ 864 100;
BA_ "VFrameFormat" BO_ 864 14;
BA_ "SC_Message" BO_ 882 1;
BA_ "SC_LinkPos" BO_ 882 64;
BA_ "SCP_AuthInfoTxLength" BO_ 882 24;
BA_ "SCP_DataId" BO_ 882 882;
BA_ "GenMsgCycleTime" BO_ 882 100;
BA_ "SCP_FreshnessValueId" BO_ 882 882;
BA_ "SCP_FreshnessValueLength" BO_ 882 64;
BA_ "SCL_CryptographicMessageID" BO_ 882 882;
BA_ "SCP_FreshnessValueTxLength" BO_ 882 8;
BA_ "E2EP01DataLength" BO_ 882 64;
BA_ "E2EP01DataId" BO_ 882 28;
BA_ "VFrameFormat" BO_ 882 14;
BA_ "GenMsgCycleTime" BO_ 883 100;
BA_ "VFrameFormat" BO_ 883 14;
BA_ "GenMsgCycleTime" BO_ 886 100;
BA_ "VFrameFormat" BO_ 886 14;
BA_ "GenMsgCycleTime" BO_ 901 100;
BA_ "GenMsgCycleTimeFast" BO_ 901 10;
BA_ "GenMsgNrOfRepetition" BO_ 901 5;
BA_ "GenMsgDelayTime" BO_ 901 10;
BA_ "VFrameFormat" BO_ 901 14;
BA_ "GenMsgCycleTime" BO_ 928 500;
BA_ "VFrameFormat" BO_ 928 14;
BA_ "GenMsgCycleTime" BO_ 929 500;
BA_ "VFrameFormat" BO_ 929 14;
BA_ "GenMsgCycleTime" BO_ 930 500;
BA_ "VFrameFormat" BO_ 930 14;
BA_ "GenMsgCycleTime" BO_ 933 500;
BA_ "VFrameFormat" BO_ 933 14;
BA_ "GenMsgCycleTime" BO_ 934 500;
BA_ "VFrameFormat" BO_ 934 14;
BA_ "GenMsgCycleTime" BO_ 935 500;
BA_ "VFrameFormat" BO_ 935 14;
BA_ "GenMsgCycleTime" BO_ 1140 1000;
BA_ "VFrameFormat" BO_ 1140 14;
BA_ "GenMsgCycleTime" BO_ 1168 100;
BA_ "VFrameFormat" BO_ 1168 14;
BA_ "GenMsgCycleTime" BO_ 1169 100;
BA_ "VFrameFormat" BO_ 1169 14;
BA_ "SC_Message" BO_ 1268 1;
BA_ "SC_LinkPos" BO_ 1268 64;
BA_ "SCP_AuthInfoTxLength" BO_ 1268 24;
BA_ "SCP_DataId" BO_ 1268 1268;
BA_ "GenMsgCycleTime" BO_ 1268 100;
BA_ "SCP_FreshnessValueId" BO_ 1268 1268;
BA_ "SCP_FreshnessValueLength" BO_ 1268 64;
BA_ "SCL_CryptographicMessageID" BO_ 1268 1268;
BA_ "SCP_FreshnessValueTxLength" BO_ 1268 8;
BA_ "GenMsgCycleTimeFast" BO_ 1268 10;
BA_ "GenMsgNrOfRepetition" BO_ 1268 5;
BA_ "GenMsgDelayTime" BO_ 1268 10;
BA_ "GenMsgStartDelayTime" BO_ 1268 70;
BA_ "E2EP01DataLength" BO_ 1268 64;
BA_ "E2EP01DataId" BO_ 1268 194;
BA_ "VFrameFormat" BO_ 1268 14;
BA_ "GenMsgCycleTime" BO_ 1273 200;
BA_ "GenMsgDelayTime" BO_ 1273 110;
BA_ "GenMsgStartDelayTime" BO_ 1273 110;
BA_ "VFrameFormat" BO_ 1273 14;
BA_ "GenMsgCycleTime" BO_ 1287 100;
BA_ "VFrameFormat" BO_ 1287 14;
BA_ "GenMsgCycleTime" BO_ 1297 100;
BA_ "VFrameFormat" BO_ 1297 14;
BA_ "GenMsgCycleTime" BO_ 1329 100;
BA_ "VFrameFormat" BO_ 1329 14;
BA_ "GenMsgCycleTime" BO_ 1429 1000;
BA_ "VFrameFormat" BO_ 1429 14;
BA_ "SC_Message" BO_ 1476 1;
BA_ "SC_LinkPos" BO_ 1476 64;
BA_ "SCP_AuthInfoTxLength" BO_ 1476 24;
BA_ "SCP_DataId" BO_ 1476 1476;
BA_ "GenMsgCycleTime" BO_ 1476 100;
BA_ "SCP_FreshnessValueId" BO_ 1476 1476;
BA_ "SCP_FreshnessValueLength" BO_ 1476 64;
BA_ "SCL_CryptographicMessageID" BO_ 1476 1476;
BA_ "SCP_FreshnessValueTxLength" BO_ 1476 8;
BA_ "GenMsgDelayTime" BO_ 1476 90;
BA_ "GenMsgStartDelayTime" BO_ 1476 90;
BA_ "VFrameFormat" BO_ 1476 14;
BA_ "GenMsgCycleTime" BO_ 1562 1000;
BA_ "GenMsgCycleTimeFast" BO_ 1562 1000;
BA_ "VFrameFormat" BO_ 1562 14;
BA_ "GenMsgCycleTime" BO_ 1583 1000;
BA_ "GenMsgStartDelayTime" BO_ 1583 195;
BA_ "VFrameFormat" BO_ 1583 14;
BA_ "GenMsgCycleTime" BO_ 1594 1000;
BA_ "VFrameFormat" BO_ 1594 14;
BA_ "GenMsgCycleTime" BO_ 1604 1000;
BA_ "E2EP01DataLength" BO_ 1604 64;
BA_ "E2EP01DataId" BO_ 1604 20;
BA_ "VFrameFormat" BO_ 1604 14;
BA_ "sigSecLevel" SG_ 759 BMS_Bat_C_MaxCell_U "null";
BA_ "sigConfig" SG_ 759 BMS_Bat_C_MaxCell_U "null";
BA_ "sigExplanation" SG_ 759 BMS_Bat_C_MaxCell_U "null";
BA_ "sigSecLevel" SG_ 759 BMS_Bat_D_MinCell_U "B";
BA_ "sigConfig" SG_ 759 BMS_Bat_D_MinCell_U "null";
BA_ "sigExplanation" SG_ 759 BMS_Bat_D_MinCell_U "null";
BA_ "sigSecLevel" SG_ 759 BMS_Bat_D_MaxPack_I "A(B)";
BA_ "sigConfig" SG_ 759 BMS_Bat_D_MaxPack_I "null";
BA_ "sigExplanation" SG_ 759 BMS_Bat_D_MaxPack_I "null";
BA_ "sigSecLevel" SG_ 759 BMS_Bat_C_MaxPack_I "A(B)";
BA_ "sigConfig" SG_ 759 BMS_Bat_C_MaxPack_I "null";
BA_ "sigExplanation" SG_ 759 BMS_Bat_C_MaxPack_I "null";
BA_ "sigSecLevel" SG_ 760 BMS_Volt_PLT_CheckSum "null";
BA_ "sigConfig" SG_ 760 BMS_Volt_PLT_CheckSum "null";
BA_ "sigExplanation" SG_ 760 BMS_Volt_PLT_CheckSum "null";
BA_ "sigSecLevel" SG_ 760 BMS_Volt_PLT_AliveCounter "null";
BA_ "sigConfig" SG_ 760 BMS_Volt_PLT_AliveCounter "null";
BA_ "sigExplanation" SG_ 760 BMS_Volt_PLT_AliveCounter "null";
BA_ "sigSecLevel" SG_ 760 BMS_Bat_C_MAXvolt_PLT "null";
BA_ "sigConfig" SG_ 760 BMS_Bat_C_MAXvolt_PLT "null";
BA_ "sigExplanation" SG_ 760 BMS_Bat_C_MAXvolt_PLT "null";
BA_ "sigSecLevel" SG_ 760 BMS_Bat_D_MAXvolt_PLT "null";
BA_ "sigConfig" SG_ 760 BMS_Bat_D_MAXvolt_PLT "null";
BA_ "sigExplanation" SG_ 760 BMS_Bat_D_MAXvolt_PLT "null";
BA_ "sigSecLevel" SG_ 792 ESP_318_CheckSum "null";
BA_ "sigConfig" SG_ 792 ESP_318_CheckSum "null";
BA_ "sigExplanation" SG_ 792 ESP_318_CheckSum "null";
BA_ "sigSecLevel" SG_ 792 ESP_318_AliveCounter "null";
BA_ "sigConfig" SG_ 792 ESP_318_AliveCounter "null";
BA_ "sigExplanation" SG_ 792 ESP_318_AliveCounter "null";
BA_ "sigSecLevel" SG_ 792 ESP_BrkPedlStsVld "C";
BA_ "sigConfig" SG_ 792 ESP_BrkPedlStsVld "null";
BA_ "sigExplanation" SG_ 792 ESP_BrkPedlStsVld "null";
BA_ "sigSecLevel" SG_ 792 ESP_BrkPedlSts "C";
BA_ "sigConfig" SG_ 792 ESP_BrkPedlSts "null";
BA_ "sigExplanation" SG_ 792 ESP_BrkPedlSts "null";
BA_ "sigSecLevel" SG_ 792 ESP_VehSpdVld "B";
BA_ "sigConfig" SG_ 792 ESP_VehSpdVld "null";
BA_ "sigExplanation" SG_ 792 ESP_VehSpdVld "null";
BA_ "sigSecLevel" SG_ 792 ESP_SysActv "null";
BA_ "sigConfig" SG_ 792 ESP_SysActv "null";
BA_ "sigExplanation" SG_ 792 ESP_SysActv "null";
BA_ "sigSecLevel" SG_ 792 ESP_LampSwtOffIndcn "null";
BA_ "sigConfig" SG_ 792 ESP_LampSwtOffIndcn "null";
BA_ "sigExplanation" SG_ 792 ESP_LampSwtOffIndcn "null";
BA_ "sigSecLevel" SG_ 792 ESP_FltIndcn_EBD "null";
BA_ "sigConfig" SG_ 792 ESP_FltIndcn_EBD "null";
BA_ "sigExplanation" SG_ 792 ESP_FltIndcn_EBD "null";
BA_ "sigSecLevel" SG_ 792 ESP_FltIndcn_ABS "B";
BA_ "sigConfig" SG_ 792 ESP_FltIndcn_ABS "null";
BA_ "sigExplanation" SG_ 792 ESP_FltIndcn_ABS "null";
BA_ "sigSecLevel" SG_ 792 ESP_MilgRollgCntr_ODO "null";
BA_ "sigConfig" SG_ 792 ESP_MilgRollgCntr_ODO "null";
BA_ "sigExplanation" SG_ 792 ESP_MilgRollgCntr_ODO "null";
BA_ "sigSecLevel" SG_ 792 ESP_VehSpd "B";
BA_ "sigConfig" SG_ 792 ESP_VehSpd "null";
BA_ "sigExplanation" SG_ 792 ESP_VehSpd "null";
BA_ "sigSecLevel" SG_ 792 ESP_IninModSigIndcn "null";
BA_ "sigConfig" SG_ 792 ESP_IninModSigIndcn "null";
BA_ "sigExplanation" SG_ 792 ESP_IninModSigIndcn "null";
BA_ "sigSecLevel" SG_ 792 ESP_FltIndcn_TCS "B";
BA_ "sigConfig" SG_ 792 ESP_FltIndcn_TCS "null";
BA_ "sigExplanation" SG_ 792 ESP_FltIndcn_TCS "null";
BA_ "sigSecLevel" SG_ 792 ESP_CtrlSts_HDC "null";
BA_ "sigConfig" SG_ 792 ESP_CtrlSts_HDC "null";
BA_ "sigExplanation" SG_ 792 ESP_CtrlSts_HDC "null";
BA_ "sigSecLevel" SG_ 792 ESP_AvlIndcn_HDC "null";
BA_ "sigConfig" SG_ 792 ESP_AvlIndcn_HDC "null";
BA_ "sigExplanation" SG_ 792 ESP_AvlIndcn_HDC "null";
BA_ "sigSecLevel" SG_ 792 ESP_NoBrkP "null";
BA_ "sigConfig" SG_ 792 ESP_NoBrkP "null";
BA_ "sigExplanation" SG_ 792 ESP_NoBrkP "null";
BA_ "sigSecLevel" SG_ 792 ESP_RDAEnaFlg "null";
BA_ "sigConfig" SG_ 792 ESP_RDAEnaFlg "null";
BA_ "sigExplanation" SG_ 792 ESP_RDAEnaFlg "null";
BA_ "sigSecLevel" SG_ 816 BMS_330_391_CheckSum "null";
BA_ "sigConfig" SG_ 816 BMS_330_391_CheckSum "null";
BA_ "sigExplanation" SG_ 816 BMS_330_391_CheckSum "null";
BA_ "sigSecLevel" SG_ 816 BMS_330_391_AliveCounter "null";
BA_ "sigConfig" SG_ 816 BMS_330_391_AliveCounter "null";
BA_ "sigExplanation" SG_ 816 BMS_330_391_AliveCounter "null";
BA_ "sigSecLevel" SG_ 816 BMS_VehInsulFltDisp "null";
BA_ "sigConfig" SG_ 816 BMS_VehInsulFltDisp "null";
BA_ "sigExplanation" SG_ 816 BMS_VehInsulFltDisp "null";
BA_ "sigSecLevel" SG_ 816 BMS_PwrBattSysFltDisp "null";
BA_ "sigConfig" SG_ 816 BMS_PwrBattSysFltDisp "null";
BA_ "sigExplanation" SG_ 816 BMS_PwrBattSysFltDisp "null";
BA_ "sigSecLevel" SG_ 816 BMS_PwrBattRmngCpSOC "null";
BA_ "sigConfig" SG_ 816 BMS_PwrBattRmngCpSOC "null";
BA_ "sigExplanation" SG_ 816 BMS_PwrBattRmngCpSOC "null";
BA_ "sigSecLevel" SG_ 816 BMS_PwrBattAvlCp "null";
BA_ "sigConfig" SG_ 816 BMS_PwrBattAvlCp "null";
BA_ "sigExplanation" SG_ 816 BMS_PwrBattAvlCp "null";
BA_ "sigSecLevel" SG_ 816 BMS_CellMinTAlrm "null";
BA_ "sigConfig" SG_ 816 BMS_CellMinTAlrm "null";
BA_ "sigExplanation" SG_ 816 BMS_CellMinTAlrm "null";
BA_ "sigSecLevel" SG_ 816 BMS_PwrBattThermRunawayAlrm "null";
BA_ "sigConfig" SG_ 816 BMS_PwrBattThermRunawayAlrm "null";
BA_ "sigExplanation" SG_ 816 BMS_PwrBattThermRunawayAlrm "null";
BA_ "sigSecLevel" SG_ 816 BMS_PwrBattOverT "null";
BA_ "sigConfig" SG_ 816 BMS_PwrBattOverT "null";
BA_ "sigExplanation" SG_ 816 BMS_PwrBattOverT "null";
BA_ "sigSecLevel" SG_ 816 BMS_PwrBattInsulSts "null";
BA_ "sigConfig" SG_ 816 BMS_PwrBattInsulSts "null";
BA_ "sigExplanation" SG_ 816 BMS_PwrBattInsulSts "null";
BA_ "sigSecLevel" SG_ 816 BMS_330_SSecOC_Fresh_Byte0 "null";
BA_ "sigConfig" SG_ 816 BMS_330_SSecOC_Fresh_Byte0 "null";
BA_ "sigExplanation" SG_ 816 BMS_330_SSecOC_Fresh_Byte0 "null";
BA_ "sigSecLevel" SG_ 816 BMS_330_SSecOC_MAC_Byte0 "null";
BA_ "sigConfig" SG_ 816 BMS_330_SSecOC_MAC_Byte0 "null";
BA_ "sigExplanation" SG_ 816 BMS_330_SSecOC_MAC_Byte0 "null";
BA_ "sigSecLevel" SG_ 816 BMS_330_SSecOC_MAC_Byte1 "null";
BA_ "sigConfig" SG_ 816 BMS_330_SSecOC_MAC_Byte1 "null";
BA_ "sigExplanation" SG_ 816 BMS_330_SSecOC_MAC_Byte1 "null";
BA_ "sigSecLevel" SG_ 816 BMS_330_SSecOC_MAC_Byte2 "null";
BA_ "sigConfig" SG_ 816 BMS_330_SSecOC_MAC_Byte2 "null";
BA_ "sigExplanation" SG_ 816 BMS_330_SSecOC_MAC_Byte2 "null";
BA_ "sigSecLevel" SG_ 819 BCM_333_CheckSum "null";
BA_ "sigConfig" SG_ 819 BCM_333_CheckSum "null";
BA_ "sigExplanation" SG_ 819 BCM_333_CheckSum "null";
BA_ "sigSecLevel" SG_ 819 BCM_333_AliveCounter "null";
BA_ "sigConfig" SG_ 819 BCM_333_AliveCounter "null";
BA_ "sigExplanation" SG_ 819 BCM_333_AliveCounter "null";
BA_ "sigSecLevel" SG_ 819 BCM_KL15_Off_Announcement "null";
BA_ "sigConfig" SG_ 819 BCM_KL15_Off_Announcement "null";
BA_ "sigExplanation" SG_ 819 BCM_KL15_Off_Announcement "null";
BA_ "sigSecLevel" SG_ 819 BCM_IG1Sts "null";
BA_ "sigConfig" SG_ 819 BCM_IG1Sts "null";
BA_ "sigExplanation" SG_ 819 BCM_IG1Sts "null";
BA_ "sigSecLevel" SG_ 819 BCM_PwrMod "B";
BA_ "sigConfig" SG_ 819 BCM_PwrMod "null";
BA_ "sigExplanation" SG_ 819 BCM_PwrMod "null";
BA_ "sigSecLevel" SG_ 819 BCM_PwrModVld "B";
BA_ "sigConfig" SG_ 819 BCM_PwrModVld "null";
BA_ "sigExplanation" SG_ 819 BCM_PwrModVld "null";
BA_ "sigSecLevel" SG_ 819 BCM_BrkSwtSts "null";
BA_ "sigConfig" SG_ 819 BCM_BrkSwtSts "null";
BA_ "sigExplanation" SG_ 819 BCM_BrkSwtSts "null";
BA_ "sigSecLevel" SG_ 819 BCM_IG1StsVld_CAPE "null";
BA_ "sigConfig" SG_ 819 BCM_IG1StsVld_CAPE "null";
BA_ "sigExplanation" SG_ 819 BCM_IG1StsVld_CAPE "null";
BA_ "sigSecLevel" SG_ 819 BCM_IG2StsVld_CAPE "null";
BA_ "sigConfig" SG_ 819 BCM_IG2StsVld_CAPE "null";
BA_ "sigExplanation" SG_ 819 BCM_IG2StsVld_CAPE "null";
BA_ "sigSecLevel" SG_ 819 BCM_KL30s_L "null";
BA_ "sigConfig" SG_ 819 BCM_KL30s_L "null";
BA_ "sigExplanation" SG_ 819 BCM_KL30s_L "null";
BA_ "sigSecLevel" SG_ 819 BCM_IG2Sts "null";
BA_ "sigConfig" SG_ 819 BCM_IG2Sts "null";
BA_ "sigExplanation" SG_ 819 BCM_IG2Sts "null";
BA_ "sigSecLevel" SG_ 819 BCM_InteriorSwtSt "null";
BA_ "sigConfig" SG_ 819 BCM_InteriorSwtSt "null";
BA_ "sigExplanation" SG_ 819 BCM_InteriorSwtSt "null";
BA_ "sigSecLevel" SG_ 856 VCU_358_CheckSum "null";
BA_ "sigConfig" SG_ 856 VCU_358_CheckSum "null";
BA_ "sigExplanation" SG_ 856 VCU_358_CheckSum "null";
BA_ "sigSecLevel" SG_ 856 VCU_358_AliveCounter "null";
BA_ "sigConfig" SG_ 856 VCU_358_AliveCounter "null";
BA_ "sigExplanation" SG_ 856 VCU_358_AliveCounter "null";
BA_ "sigSecLevel" SG_ 856 VCU_EPedlEnaSig "null";
BA_ "sigConfig" SG_ 856 VCU_EPedlEnaSig "null";
BA_ "sigExplanation" SG_ 856 VCU_EPedlEnaSig "null";
BA_ "sigSecLevel" SG_ 856 VCU_ComLostFlt_ESP "null";
BA_ "sigConfig" SG_ 856 VCU_ComLostFlt_ESP "null";
BA_ "sigExplanation" SG_ 856 VCU_ComLostFlt_ESP "null";
BA_ "sigSecLevel" SG_ 856 VCU_ComFlt_iBooster "null";
BA_ "sigConfig" SG_ 856 VCU_ComFlt_iBooster "null";
BA_ "sigExplanation" SG_ 856 VCU_ComFlt_iBooster "null";
BA_ "sigSecLevel" SG_ 856 VCU_RegenLvlFb "null";
BA_ "sigConfig" SG_ 856 VCU_RegenLvlFb "null";
BA_ "sigExplanation" SG_ 856 VCU_RegenLvlFb "null";
BA_ "sigSecLevel" SG_ 856 VCU_AccelModFb "null";
BA_ "sigConfig" SG_ 856 VCU_AccelModFb "null";
BA_ "sigExplanation" SG_ 856 VCU_AccelModFb "null";
BA_ "sigSecLevel" SG_ 856 VCU_EPedlStsFb "null";
BA_ "sigConfig" SG_ 856 VCU_EPedlStsFb "null";
BA_ "sigExplanation" SG_ 856 VCU_EPedlStsFb "null";
BA_ "sigSecLevel" SG_ 856 VCU_CcTrgSpdDisp "null";
BA_ "sigConfig" SG_ 856 VCU_CcTrgSpdDisp "null";
BA_ "sigExplanation" SG_ 856 VCU_CcTrgSpdDisp "null";
BA_ "sigSecLevel" SG_ 856 VCU_Sts_CC_ICC "null";
BA_ "sigConfig" SG_ 856 VCU_Sts_CC_ICC "null";
BA_ "sigExplanation" SG_ 856 VCU_Sts_CC_ICC "null";
BA_ "sigSecLevel" SG_ 856 VCU_CCIconDisp "null";
BA_ "sigConfig" SG_ 856 VCU_CCIconDisp "null";
BA_ "sigExplanation" SG_ 856 VCU_CCIconDisp "null";
BA_ "sigSecLevel" SG_ 856 VCU_DispSpdUnit_CC "null";
BA_ "sigConfig" SG_ 856 VCU_DispSpdUnit_CC "null";
BA_ "sigExplanation" SG_ 856 VCU_DispSpdUnit_CC "null";
BA_ "sigSecLevel" SG_ 864 BMS_PwrBattPosGNDInsulRrel "null";
BA_ "sigConfig" SG_ 864 BMS_PwrBattPosGNDInsulRrel "null";
BA_ "sigExplanation" SG_ 864 BMS_PwrBattPosGNDInsulRrel "null";
BA_ "sigSecLevel" SG_ 864 BMS_PwrBattNegGNDInsulRrel "null";
BA_ "sigConfig" SG_ 864 BMS_PwrBattNegGNDInsulRrel "null";
BA_ "sigExplanation" SG_ 864 BMS_PwrBattNegGNDInsulRrel "null";
BA_ "sigSecLevel" SG_ 864 BMS_PwrBattPosGNDInsulR "null";
BA_ "sigConfig" SG_ 864 BMS_PwrBattPosGNDInsulR "null";
BA_ "sigExplanation" SG_ 864 BMS_PwrBattPosGNDInsulR "null";
BA_ "sigSecLevel" SG_ 864 BMS_PwrBattNegGNDInsulR "null";
BA_ "sigConfig" SG_ 864 BMS_PwrBattNegGNDInsulR "null";
BA_ "sigExplanation" SG_ 864 BMS_PwrBattNegGNDInsulR "null";
BA_ "sigSecLevel" SG_ 882 BMS_372_382_CheckSum "null";
BA_ "sigConfig" SG_ 882 BMS_372_382_CheckSum "null";
BA_ "sigExplanation" SG_ 882 BMS_372_382_CheckSum "null";
BA_ "sigSecLevel" SG_ 882 BMS_372_382_AliveCounter "null";
BA_ "sigConfig" SG_ 882 BMS_372_382_AliveCounter "null";
BA_ "sigExplanation" SG_ 882 BMS_372_382_AliveCounter "null";
BA_ "GenSigStartValue" SG_ 882 BMS_CellMinT 48;
BA_ "sigSecLevel" SG_ 882 BMS_CellMinT "null";
BA_ "sigConfig" SG_ 882 BMS_CellMinT "null";
BA_ "sigExplanation" SG_ 882 BMS_CellMinT "null";
BA_ "sigSecLevel" SG_ 882 BMS_CellDiffT "null";
BA_ "sigConfig" SG_ 882 BMS_CellDiffT "null";
BA_ "sigExplanation" SG_ 882 BMS_CellDiffT "null";
BA_ "GenSigStartValue" SG_ 882 BMS_CellMaxT 48;
BA_ "sigSecLevel" SG_ 882 BMS_CellMaxT "A(B)";
BA_ "sigConfig" SG_ 882 BMS_CellMaxT "null";
BA_ "sigExplanation" SG_ 882 BMS_CellMaxT "null";
BA_ "GenSigStartValue" SG_ 882 BMS_BattAvrgT 48;
BA_ "sigSecLevel" SG_ 882 BMS_BattAvrgT "null";
BA_ "sigConfig" SG_ 882 BMS_BattAvrgT "null";
BA_ "sigExplanation" SG_ 882 BMS_BattAvrgT "null";
BA_ "sigSecLevel" SG_ 882 BMS_PwrBattHeatgMngDmd "null";
BA_ "sigConfig" SG_ 882 BMS_PwrBattHeatgMngDmd "null";
BA_ "sigExplanation" SG_ 882 BMS_PwrBattHeatgMngDmd "null";
BA_ "sigSecLevel" SG_ 882 BMS_ECCSysAllwDwnPwrCmd "null";
BA_ "sigConfig" SG_ 882 BMS_ECCSysAllwDwnPwrCmd "null";
BA_ "sigExplanation" SG_ 882 BMS_ECCSysAllwDwnPwrCmd "null";
BA_ "GenSigStartValue" SG_ 882 BMS_BattInlTDmd 48;
BA_ "sigSecLevel" SG_ 882 BMS_BattInlTDmd "null";
BA_ "sigConfig" SG_ 882 BMS_BattInlTDmd "null";
BA_ "sigExplanation" SG_ 882 BMS_BattInlTDmd "null";
BA_ "sigSecLevel" SG_ 882 BMS_372_SSecOC_Fresh_Byte0 "null";
BA_ "sigConfig" SG_ 882 BMS_372_SSecOC_Fresh_Byte0 "null";
BA_ "sigExplanation" SG_ 882 BMS_372_SSecOC_Fresh_Byte0 "null";
BA_ "sigSecLevel" SG_ 882 BMS_372_SSecOC_MAC_Byte0 "null";
BA_ "sigConfig" SG_ 882 BMS_372_SSecOC_MAC_Byte0 "null";
BA_ "sigExplanation" SG_ 882 BMS_372_SSecOC_MAC_Byte0 "null";
BA_ "sigSecLevel" SG_ 882 BMS_372_SSecOC_MAC_Byte1 "null";
BA_ "sigConfig" SG_ 882 BMS_372_SSecOC_MAC_Byte1 "null";
BA_ "sigExplanation" SG_ 882 BMS_372_SSecOC_MAC_Byte1 "null";
BA_ "sigSecLevel" SG_ 882 BMS_372_SSecOC_MAC_Byte2 "null";
BA_ "sigConfig" SG_ 882 BMS_372_SSecOC_MAC_Byte2 "null";
BA_ "sigExplanation" SG_ 882 BMS_372_SSecOC_MAC_Byte2 "null";
BA_ "sigSecLevel" SG_ 883 ECC_CrtSts "null";
BA_ "sigConfig" SG_ 883 ECC_CrtSts "null";
BA_ "sigExplanation" SG_ 883 ECC_CrtSts "null";
BA_ "sigSecLevel" SG_ 883 ECC_IninSts "null";
BA_ "sigConfig" SG_ 883 ECC_IninSts "null";
BA_ "sigExplanation" SG_ 883 ECC_IninSts "null";
BA_ "sigSecLevel" SG_ 883 ECC_PwrSysHeatMngtSts "null";
BA_ "sigConfig" SG_ 883 ECC_PwrSysHeatMngtSts "null";
BA_ "sigExplanation" SG_ 883 ECC_PwrSysHeatMngtSts "null";
BA_ "sigSecLevel" SG_ 883 ECC_ACSts "null";
BA_ "sigConfig" SG_ 883 ECC_ACSts "null";
BA_ "sigExplanation" SG_ 883 ECC_ACSts "null";
BA_ "sigSecLevel" SG_ 883 ECC_AirClnSts "null";
BA_ "sigConfig" SG_ 883 ECC_AirClnSts "null";
BA_ "sigExplanation" SG_ 883 ECC_AirClnSts "null";
BA_ "sigSecLevel" SG_ 883 ECC_WindSpdSts "null";
BA_ "sigConfig" SG_ 883 ECC_WindSpdSts "null";
BA_ "sigExplanation" SG_ 883 ECC_WindSpdSts "null";
BA_ "sigSecLevel" SG_ 883 ECC_BackRowAirOutlModSts "null";
BA_ "sigConfig" SG_ 883 ECC_BackRowAirOutlModSts "null";
BA_ "sigExplanation" SG_ 883 ECC_BackRowAirOutlModSts "null";
BA_ "sigSecLevel" SG_ 883 ECC_DrvrTSetSts "null";
BA_ "sigConfig" SG_ 883 ECC_DrvrTSetSts "null";
BA_ "sigExplanation" SG_ 883 ECC_DrvrTSetSts "null";
BA_ "sigSecLevel" SG_ 883 ECC_PassTSetSts "null";
BA_ "sigConfig" SG_ 883 ECC_PassTSetSts "null";
BA_ "sigExplanation" SG_ 883 ECC_PassTSetSts "null";
BA_ "sigSecLevel" SG_ 883 ECC_HeatSts "null";
BA_ "sigConfig" SG_ 883 ECC_HeatSts "null";
BA_ "sigExplanation" SG_ 883 ECC_HeatSts "null";
BA_ "sigSecLevel" SG_ 883 ECC_AUTOSts "null";
BA_ "sigConfig" SG_ 883 ECC_AUTOSts "null";
BA_ "sigExplanation" SG_ 883 ECC_AUTOSts "null";
BA_ "sigSecLevel" SG_ 883 ECC_SYNCSts "null";
BA_ "sigConfig" SG_ 883 ECC_SYNCSts "null";
BA_ "sigExplanation" SG_ 883 ECC_SYNCSts "null";
BA_ "sigSecLevel" SG_ 883 ECC_InfoSysWrmColdDisp "null";
BA_ "sigConfig" SG_ 883 ECC_InfoSysWrmColdDisp "null";
BA_ "sigExplanation" SG_ 883 ECC_InfoSysWrmColdDisp "null";
BA_ "sigSecLevel" SG_ 883 ECC_CircSts "null";
BA_ "sigConfig" SG_ 883 ECC_CircSts "null";
BA_ "sigExplanation" SG_ 883 ECC_CircSts "null";
BA_ "sigSecLevel" SG_ 883 ECC_ParticleConcVld "null";
BA_ "sigConfig" SG_ 883 ECC_ParticleConcVld "null";
BA_ "sigExplanation" SG_ 883 ECC_ParticleConcVld "null";
BA_ "GenSigStartValue" SG_ 883 ECC_OutdT 48;
BA_ "sigSecLevel" SG_ 883 ECC_OutdT "null";
BA_ "sigConfig" SG_ 883 ECC_OutdT "null";
BA_ "sigExplanation" SG_ 883 ECC_OutdT "null";
BA_ "sigSecLevel" SG_ 883 ECC_OutdTVld "null";
BA_ "sigConfig" SG_ 883 ECC_OutdTVld "null";
BA_ "sigExplanation" SG_ 883 ECC_OutdTVld "null";
BA_ "sigSecLevel" SG_ 883 ECC_MaxFrntDefrst "null";
BA_ "sigConfig" SG_ 883 ECC_MaxFrntDefrst "null";
BA_ "sigExplanation" SG_ 883 ECC_MaxFrntDefrst "null";
BA_ "sigSecLevel" SG_ 883 ECC_HeatMngtSysFlt "null";
BA_ "sigConfig" SG_ 883 ECC_HeatMngtSysFlt "null";
BA_ "sigExplanation" SG_ 883 ECC_HeatMngtSysFlt "null";
BA_ "sigSecLevel" SG_ 883 ECC_HeatMngtFctLim "null";
BA_ "sigConfig" SG_ 883 ECC_HeatMngtFctLim "null";
BA_ "sigExplanation" SG_ 883 ECC_HeatMngtFctLim "null";
BA_ "sigSecLevel" SG_ 883 ECC_DrvrAirOutlMod "null";
BA_ "sigConfig" SG_ 883 ECC_DrvrAirOutlMod "null";
BA_ "sigExplanation" SG_ 883 ECC_DrvrAirOutlMod "null";
BA_ "sigSecLevel" SG_ 883 ECC_PassAirOutlMod "null";
BA_ "sigConfig" SG_ 883 ECC_PassAirOutlMod "null";
BA_ "sigExplanation" SG_ 883 ECC_PassAirOutlMod "null";
BA_ "sigSecLevel" SG_ 883 ECC_RemSts "null";
BA_ "sigConfig" SG_ 883 ECC_RemSts "null";
BA_ "sigExplanation" SG_ 883 ECC_RemSts "null";
BA_ "sigSecLevel" SG_ 886 WTC_B_InlT "null";
BA_ "sigConfig" SG_ 886 WTC_B_InlT "null";
BA_ "sigExplanation" SG_ 886 WTC_B_InlT "null";
BA_ "sigSecLevel" SG_ 886 WTC_B_OutlT "null";
BA_ "sigConfig" SG_ 886 WTC_B_OutlT "null";
BA_ "sigExplanation" SG_ 886 WTC_B_OutlT "null";
BA_ "sigSecLevel" SG_ 886 WTC_B_CrtPwr "null";
BA_ "sigConfig" SG_ 886 WTC_B_CrtPwr "null";
BA_ "sigExplanation" SG_ 886 WTC_B_CrtPwr "null";
BA_ "sigSecLevel" SG_ 886 WTC_B_CrtT "null";
BA_ "sigConfig" SG_ 886 WTC_B_CrtT "null";
BA_ "sigExplanation" SG_ 886 WTC_B_CrtT "null";
BA_ "sigSecLevel" SG_ 886 WTC_B_IninSts "null";
BA_ "sigConfig" SG_ 886 WTC_B_IninSts "null";
BA_ "sigExplanation" SG_ 886 WTC_B_IninSts "null";
BA_ "sigSecLevel" SG_ 886 WTC_B_HVPwrSplySts "null";
BA_ "sigConfig" SG_ 886 WTC_B_HVPwrSplySts "null";
BA_ "sigExplanation" SG_ 886 WTC_B_HVPwrSplySts "null";
BA_ "sigSecLevel" SG_ 886 WTC_B_ActGear "null";
BA_ "sigConfig" SG_ 886 WTC_B_ActGear "null";
BA_ "sigExplanation" SG_ 886 WTC_B_ActGear "null";
BA_ "sigSecLevel" SG_ 886 WTC_B_Mod "null";
BA_ "sigConfig" SG_ 886 WTC_B_Mod "null";
BA_ "sigExplanation" SG_ 886 WTC_B_Mod "null";
BA_ "sigSecLevel" SG_ 901 TBOX_PreHeatDepartTi1_Hr "null";
BA_ "sigConfig" SG_ 901 TBOX_PreHeatDepartTi1_Hr "null";
BA_ "sigExplanation" SG_ 901 TBOX_PreHeatDepartTi1_Hr "null";
BA_ "sigSecLevel" SG_ 901 TBOX_PreHeatDepartTi1_Mins "null";
BA_ "sigConfig" SG_ 901 TBOX_PreHeatDepartTi1_Mins "null";
BA_ "sigExplanation" SG_ 901 TBOX_PreHeatDepartTi1_Mins "null";
BA_ "sigSecLevel" SG_ 901 TBOX_PreHeatDepartSet "null";
BA_ "sigConfig" SG_ 901 TBOX_PreHeatDepartSet "null";
BA_ "sigExplanation" SG_ 901 TBOX_PreHeatDepartSet "null";
BA_ "sigSecLevel" SG_ 901 TBOX_MonPreHeatDepartSet "null";
BA_ "sigConfig" SG_ 901 TBOX_MonPreHeatDepartSet "null";
BA_ "sigExplanation" SG_ 901 TBOX_MonPreHeatDepartSet "null";
BA_ "sigSecLevel" SG_ 901 TBOX_TuePreHeatDepartSet "null";
BA_ "sigConfig" SG_ 901 TBOX_TuePreHeatDepartSet "null";
BA_ "sigExplanation" SG_ 901 TBOX_TuePreHeatDepartSet "null";
BA_ "sigSecLevel" SG_ 901 TBOX_WedPreHeatDepartSet "null";
BA_ "sigConfig" SG_ 901 TBOX_WedPreHeatDepartSet "null";
BA_ "sigExplanation" SG_ 901 TBOX_WedPreHeatDepartSet "null";
BA_ "sigSecLevel" SG_ 901 TBOX_ThuPreHeatDepartSet "null";
BA_ "sigConfig" SG_ 901 TBOX_ThuPreHeatDepartSet "null";
BA_ "sigExplanation" SG_ 901 TBOX_ThuPreHeatDepartSet "null";
BA_ "sigSecLevel" SG_ 901 TBOX_FriPreHeatDepartSet "null";
BA_ "sigConfig" SG_ 901 TBOX_FriPreHeatDepartSet "null";
BA_ "sigExplanation" SG_ 901 TBOX_FriPreHeatDepartSet "null";
BA_ "sigSecLevel" SG_ 901 TBOX_SatPreHeatDepartSet "null";
BA_ "sigConfig" SG_ 901 TBOX_SatPreHeatDepartSet "null";
BA_ "sigExplanation" SG_ 901 TBOX_SatPreHeatDepartSet "null";
BA_ "sigSecLevel" SG_ 901 TBOX_SunPreHeatDepartSet "null";
BA_ "sigConfig" SG_ 901 TBOX_SunPreHeatDepartSet "null";
BA_ "sigExplanation" SG_ 901 TBOX_SunPreHeatDepartSet "null";
BA_ "sigSecLevel" SG_ 901 TBOX_PreCdnTarT "null";
BA_ "sigConfig" SG_ 901 TBOX_PreCdnTarT "null";
BA_ "sigExplanation" SG_ 901 TBOX_PreCdnTarT "null";
BA_ "sigSecLevel" SG_ 928 BMS_Cont_Error_StuckOpen_HV_Pos1 "null";
BA_ "sigConfig" SG_ 928 BMS_Cont_Error_StuckOpen_HV_Pos1 "null";
BA_ "sigExplanation" SG_ 928 BMS_Cont_Error_StuckOpen_HV_Pos1 "null";
BA_ "sigSecLevel" SG_ 928 BMS_Cont_Error_Welded_HV_Pos1 "null";
BA_ "sigConfig" SG_ 928 BMS_Cont_Error_Welded_HV_Pos1 "null";
BA_ "sigExplanation" SG_ 928 BMS_Cont_Error_Welded_HV_Pos1 "null";
BA_ "sigSecLevel" SG_ 928 BMS_Cont_Error_Exceed_HV_Pos1 "null";
BA_ "sigConfig" SG_ 928 BMS_Cont_Error_Exceed_HV_Pos1 "null";
BA_ "sigExplanation" SG_ 928 BMS_Cont_Error_Exceed_HV_Pos1 "null";
BA_ "sigSecLevel" SG_ 928 BMS_Cont_Error_DisCh1_HV_Pos1 "null";
BA_ "sigConfig" SG_ 928 BMS_Cont_Error_DisCh1_HV_Pos1 "null";
BA_ "sigExplanation" SG_ 928 BMS_Cont_Error_DisCh1_HV_Pos1 "null";
BA_ "sigSecLevel" SG_ 928 BMS_Cont_Error_DisCh2_HV_Pos1 "null";
BA_ "sigConfig" SG_ 928 BMS_Cont_Error_DisCh2_HV_Pos1 "null";
BA_ "sigExplanation" SG_ 928 BMS_Cont_Error_DisCh2_HV_Pos1 "null";
BA_ "sigSecLevel" SG_ 928 BMS_Cont_Error_DisCh3_HV_Pos1 "null";
BA_ "sigConfig" SG_ 928 BMS_Cont_Error_DisCh3_HV_Pos1 "null";
BA_ "sigExplanation" SG_ 928 BMS_Cont_Error_DisCh3_HV_Pos1 "null";
BA_ "sigSecLevel" SG_ 928 BMS_Cont_Error_DisCh4_HV_Pos1 "null";
BA_ "sigConfig" SG_ 928 BMS_Cont_Error_DisCh4_HV_Pos1 "null";
BA_ "sigExplanation" SG_ 928 BMS_Cont_Error_DisCh4_HV_Pos1 "null";
BA_ "sigSecLevel" SG_ 928 BMS_Cont_Error_Ch1_HV_Pos1 "null";
BA_ "sigConfig" SG_ 928 BMS_Cont_Error_Ch1_HV_Pos1 "null";
BA_ "sigExplanation" SG_ 928 BMS_Cont_Error_Ch1_HV_Pos1 "null";
BA_ "sigSecLevel" SG_ 928 BMS_Cont_Error_Ch2_HV_Pos1 "null";
BA_ "sigConfig" SG_ 928 BMS_Cont_Error_Ch2_HV_Pos1 "null";
BA_ "sigExplanation" SG_ 928 BMS_Cont_Error_Ch2_HV_Pos1 "null";
BA_ "sigSecLevel" SG_ 929 BMS_Cont_Error_StuckOpen_HV_Neg1 "null";
BA_ "sigConfig" SG_ 929 BMS_Cont_Error_StuckOpen_HV_Neg1 "null";
BA_ "sigExplanation" SG_ 929 BMS_Cont_Error_StuckOpen_HV_Neg1 "null";
BA_ "sigSecLevel" SG_ 929 BMS_Cont_Error_Welded_HV_Neg1 "null";
BA_ "sigConfig" SG_ 929 BMS_Cont_Error_Welded_HV_Neg1 "null";
BA_ "sigExplanation" SG_ 929 BMS_Cont_Error_Welded_HV_Neg1 "null";
BA_ "sigSecLevel" SG_ 929 BMS_Cont_Error_Exceed_HV_Neg1 "null";
BA_ "sigConfig" SG_ 929 BMS_Cont_Error_Exceed_HV_Neg1 "null";
BA_ "sigExplanation" SG_ 929 BMS_Cont_Error_Exceed_HV_Neg1 "null";
BA_ "sigSecLevel" SG_ 929 BMS_Cont_Error_DisCh1_HV_Neg1 "null";
BA_ "sigConfig" SG_ 929 BMS_Cont_Error_DisCh1_HV_Neg1 "null";
BA_ "sigExplanation" SG_ 929 BMS_Cont_Error_DisCh1_HV_Neg1 "null";
BA_ "sigSecLevel" SG_ 929 BMS_Cont_Error_DisCh2_HV_Neg1 "null";
BA_ "sigConfig" SG_ 929 BMS_Cont_Error_DisCh2_HV_Neg1 "null";
BA_ "sigExplanation" SG_ 929 BMS_Cont_Error_DisCh2_HV_Neg1 "null";
BA_ "sigSecLevel" SG_ 929 BMS_Cont_Error_DisCh3_HV_Neg1 "null";
BA_ "sigConfig" SG_ 929 BMS_Cont_Error_DisCh3_HV_Neg1 "null";
BA_ "sigExplanation" SG_ 929 BMS_Cont_Error_DisCh3_HV_Neg1 "null";
BA_ "sigSecLevel" SG_ 929 BMS_Cont_Error_DisCh4_HV_Neg1 "null";
BA_ "sigConfig" SG_ 929 BMS_Cont_Error_DisCh4_HV_Neg1 "null";
BA_ "sigExplanation" SG_ 929 BMS_Cont_Error_DisCh4_HV_Neg1 "null";
BA_ "sigSecLevel" SG_ 929 BMS_Cont_Error_Ch1_HV_Neg1 "null";
BA_ "sigConfig" SG_ 929 BMS_Cont_Error_Ch1_HV_Neg1 "null";
BA_ "sigExplanation" SG_ 929 BMS_Cont_Error_Ch1_HV_Neg1 "null";
BA_ "sigSecLevel" SG_ 929 BMS_Cont_Error_Ch2_HV_Neg1 "null";
BA_ "sigConfig" SG_ 929 BMS_Cont_Error_Ch2_HV_Neg1 "null";
BA_ "sigExplanation" SG_ 929 BMS_Cont_Error_Ch2_HV_Neg1 "null";
BA_ "sigSecLevel" SG_ 930 BMS_Cont_Error_StuckOpen_HV_Prec "null";
BA_ "sigConfig" SG_ 930 BMS_Cont_Error_StuckOpen_HV_Prec "null";
BA_ "sigExplanation" SG_ 930 BMS_Cont_Error_StuckOpen_HV_Prec "null";
BA_ "SystemSignalLongSymbol" SG_ 930 BMS_Cont_Error_StuckOpen_HV_Prec "BMS_Cont_Error_StuckOpen_HV_Prec1";
BA_ "sigSecLevel" SG_ 930 BMS_Cont_Error_Welded_HV_Prec1 "null";
BA_ "sigConfig" SG_ 930 BMS_Cont_Error_Welded_HV_Prec1 "null";
BA_ "sigExplanation" SG_ 930 BMS_Cont_Error_Welded_HV_Prec1 "null";
BA_ "sigSecLevel" SG_ 930 BMS_Cont_Error_Exceed_HV_Prec "null";
BA_ "sigConfig" SG_ 930 BMS_Cont_Error_Exceed_HV_Prec "null";
BA_ "sigExplanation" SG_ 930 BMS_Cont_Error_Exceed_HV_Prec "null";
BA_ "sigSecLevel" SG_ 930 BMS_Cont_Error_DisCh1_HV_Prec "null";
BA_ "sigConfig" SG_ 930 BMS_Cont_Error_DisCh1_HV_Prec "null";
BA_ "sigExplanation" SG_ 930 BMS_Cont_Error_DisCh1_HV_Prec "null";
BA_ "sigSecLevel" SG_ 930 BMS_Cont_Error_DisCh2_HV_Prec "null";
BA_ "sigConfig" SG_ 930 BMS_Cont_Error_DisCh2_HV_Prec "null";
BA_ "sigExplanation" SG_ 930 BMS_Cont_Error_DisCh2_HV_Prec "null";
BA_ "sigSecLevel" SG_ 930 BMS_Cont_Error_DisCh3_HV_Prec "null";
BA_ "sigConfig" SG_ 930 BMS_Cont_Error_DisCh3_HV_Prec "null";
BA_ "sigExplanation" SG_ 930 BMS_Cont_Error_DisCh3_HV_Prec "null";
BA_ "sigSecLevel" SG_ 930 BMS_Cont_Error_DisCh4_HV_Prec "null";
BA_ "sigConfig" SG_ 930 BMS_Cont_Error_DisCh4_HV_Prec "null";
BA_ "sigExplanation" SG_ 930 BMS_Cont_Error_DisCh4_HV_Prec "null";
BA_ "sigSecLevel" SG_ 930 BMS_Cont_Error_Ch1_HV_Prec1 "null";
BA_ "sigConfig" SG_ 930 BMS_Cont_Error_Ch1_HV_Prec1 "null";
BA_ "sigExplanation" SG_ 930 BMS_Cont_Error_Ch1_HV_Prec1 "null";
BA_ "sigSecLevel" SG_ 930 BMS_Cont_Error_Ch2_HV_Prec1 "null";
BA_ "sigConfig" SG_ 930 BMS_Cont_Error_Ch2_HV_Prec1 "null";
BA_ "sigExplanation" SG_ 930 BMS_Cont_Error_Ch2_HV_Prec1 "null";
BA_ "sigSecLevel" SG_ 933 BMS_Bat_Coolant_in "null";
BA_ "sigConfig" SG_ 933 BMS_Bat_Coolant_in "null";
BA_ "sigExplanation" SG_ 933 BMS_Bat_Coolant_in "null";
BA_ "sigSecLevel" SG_ 933 BMS_Bat_Coolant_out "null";
BA_ "sigConfig" SG_ 933 BMS_Bat_Coolant_out "null";
BA_ "sigExplanation" SG_ 933 BMS_Bat_Coolant_out "null";
BA_ "GenSigStartValue" SG_ 933 BMS_BattInlT_Target 48;
BA_ "sigSecLevel" SG_ 933 BMS_BattInlT_Target "null";
BA_ "sigConfig" SG_ 933 BMS_BattInlT_Target "null";
BA_ "sigExplanation" SG_ 933 BMS_BattInlT_Target "null";
BA_ "GenSigStartValue" SG_ 933 BMS_BattInlT_Min 48;
BA_ "sigSecLevel" SG_ 933 BMS_BattInlT_Min "null";
BA_ "sigConfig" SG_ 933 BMS_BattInlT_Min "null";
BA_ "sigExplanation" SG_ 933 BMS_BattInlT_Min "null";
BA_ "GenSigStartValue" SG_ 933 BMS_BattInlT_Max 48;
BA_ "sigSecLevel" SG_ 933 BMS_BattInlT_Max "null";
BA_ "sigConfig" SG_ 933 BMS_BattInlT_Max "null";
BA_ "sigExplanation" SG_ 933 BMS_BattInlT_Max "null";
BA_ "sigSecLevel" SG_ 934 BMS_Cont_Error_StuckOpen_HV_PV_N "null";
BA_ "sigConfig" SG_ 934 BMS_Cont_Error_StuckOpen_HV_PV_N "null";
BA_ "sigExplanation" SG_ 934 BMS_Cont_Error_StuckOpen_HV_PV_N "null";
BA_ "SystemSignalLongSymbol" SG_ 934 BMS_Cont_Error_StuckOpen_HV_PV_N "BMS_Cont_Error_StuckOpen_HV_PV_Neg1";
BA_ "sigSecLevel" SG_ 934 BMS_Cont_Error_Welded_HV_PV_Neg1 "null";
BA_ "sigConfig" SG_ 934 BMS_Cont_Error_Welded_HV_PV_Neg1 "null";
BA_ "sigExplanation" SG_ 934 BMS_Cont_Error_Welded_HV_PV_Neg1 "null";
BA_ "sigSecLevel" SG_ 934 BMS_Cont_Error_Exceed_HV_PV_Neg1 "null";
BA_ "sigConfig" SG_ 934 BMS_Cont_Error_Exceed_HV_PV_Neg1 "null";
BA_ "sigExplanation" SG_ 934 BMS_Cont_Error_Exceed_HV_PV_Neg1 "null";
BA_ "sigSecLevel" SG_ 934 BMS_Cont_Error_DisCh1_HV_PV_Neg1 "null";
BA_ "sigConfig" SG_ 934 BMS_Cont_Error_DisCh1_HV_PV_Neg1 "null";
BA_ "sigExplanation" SG_ 934 BMS_Cont_Error_DisCh1_HV_PV_Neg1 "null";
BA_ "sigSecLevel" SG_ 934 BMS_Cont_Error_DisCh2_HV_PV_Neg1 "null";
BA_ "sigConfig" SG_ 934 BMS_Cont_Error_DisCh2_HV_PV_Neg1 "null";
BA_ "sigExplanation" SG_ 934 BMS_Cont_Error_DisCh2_HV_PV_Neg1 "null";
BA_ "sigSecLevel" SG_ 934 BMS_Cont_Error_DisCh3_HV_PV_Neg1 "null";
BA_ "sigConfig" SG_ 934 BMS_Cont_Error_DisCh3_HV_PV_Neg1 "null";
BA_ "sigExplanation" SG_ 934 BMS_Cont_Error_DisCh3_HV_PV_Neg1 "null";
BA_ "sigSecLevel" SG_ 934 BMS_Cont_Error_DisCh4_HV_PV_Neg1 "null";
BA_ "sigConfig" SG_ 934 BMS_Cont_Error_DisCh4_HV_PV_Neg1 "null";
BA_ "sigExplanation" SG_ 934 BMS_Cont_Error_DisCh4_HV_PV_Neg1 "null";
BA_ "sigSecLevel" SG_ 934 BMS_Cont_Error_Ch1_HV_PV_Neg1 "null";
BA_ "sigConfig" SG_ 934 BMS_Cont_Error_Ch1_HV_PV_Neg1 "null";
BA_ "sigExplanation" SG_ 934 BMS_Cont_Error_Ch1_HV_PV_Neg1 "null";
BA_ "sigSecLevel" SG_ 934 BMS_Cont_Error_Ch2_HV_PV_Neg1 "null";
BA_ "sigConfig" SG_ 934 BMS_Cont_Error_Ch2_HV_PV_Neg1 "null";
BA_ "sigExplanation" SG_ 934 BMS_Cont_Error_Ch2_HV_PV_Neg1 "null";
BA_ "sigSecLevel" SG_ 935 BMS_Cont_Error_StuckOpen_HV_PV_P "null";
BA_ "sigConfig" SG_ 935 BMS_Cont_Error_StuckOpen_HV_PV_P "null";
BA_ "sigExplanation" SG_ 935 BMS_Cont_Error_StuckOpen_HV_PV_P "null";
BA_ "SystemSignalLongSymbol" SG_ 935 BMS_Cont_Error_StuckOpen_HV_PV_P "BMS_Cont_Error_StuckOpen_HV_PV_Pos1";
BA_ "sigSecLevel" SG_ 935 BMS_Cont_Error_Welded_HV_PV_Pos1 "null";
BA_ "sigConfig" SG_ 935 BMS_Cont_Error_Welded_HV_PV_Pos1 "null";
BA_ "sigExplanation" SG_ 935 BMS_Cont_Error_Welded_HV_PV_Pos1 "null";
BA_ "sigSecLevel" SG_ 935 BMS_Cont_Error_Exceed_HV_PV_Pos1 "null";
BA_ "sigConfig" SG_ 935 BMS_Cont_Error_Exceed_HV_PV_Pos1 "null";
BA_ "sigExplanation" SG_ 935 BMS_Cont_Error_Exceed_HV_PV_Pos1 "null";
BA_ "sigSecLevel" SG_ 935 BMS_Cont_Error_DisCh1_HV_PV_Pos1 "null";
BA_ "sigConfig" SG_ 935 BMS_Cont_Error_DisCh1_HV_PV_Pos1 "null";
BA_ "sigExplanation" SG_ 935 BMS_Cont_Error_DisCh1_HV_PV_Pos1 "null";
BA_ "sigSecLevel" SG_ 935 BMS_Cont_Error_DisCh2_HV_PV_Pos1 "null";
BA_ "sigConfig" SG_ 935 BMS_Cont_Error_DisCh2_HV_PV_Pos1 "null";
BA_ "sigExplanation" SG_ 935 BMS_Cont_Error_DisCh2_HV_PV_Pos1 "null";
BA_ "sigSecLevel" SG_ 935 BMS_Cont_Error_DisCh3_HV_PV_Pos1 "null";
BA_ "sigConfig" SG_ 935 BMS_Cont_Error_DisCh3_HV_PV_Pos1 "null";
BA_ "sigExplanation" SG_ 935 BMS_Cont_Error_DisCh3_HV_PV_Pos1 "null";
BA_ "sigSecLevel" SG_ 935 BMS_Cont_Error_DisCh4_HV_PV_Pos1 "null";
BA_ "sigConfig" SG_ 935 BMS_Cont_Error_DisCh4_HV_PV_Pos1 "null";
BA_ "sigExplanation" SG_ 935 BMS_Cont_Error_DisCh4_HV_PV_Pos1 "null";
BA_ "sigSecLevel" SG_ 935 BMS_Cont_Error_Ch1_HV_PV_Pos1 "null";
BA_ "sigConfig" SG_ 935 BMS_Cont_Error_Ch1_HV_PV_Pos1 "null";
BA_ "sigExplanation" SG_ 935 BMS_Cont_Error_Ch1_HV_PV_Pos1 "null";
BA_ "sigSecLevel" SG_ 935 BMS_Cont_Error_Ch2_HV_PV_Pos1 "null";
BA_ "sigConfig" SG_ 935 BMS_Cont_Error_Ch2_HV_PV_Pos1 "null";
BA_ "sigExplanation" SG_ 935 BMS_Cont_Error_Ch2_HV_PV_Pos1 "null";
BA_ "GenSigSendType" SG_ 1140 TBOX_ICC_UpdSched 1;
BA_ "sigSecLevel" SG_ 1168 EAS_MotSpdVld "null";
BA_ "sigConfig" SG_ 1168 EAS_MotSpdVld "null";
BA_ "sigExplanation" SG_ 1168 EAS_MotSpdVld "null";
BA_ "sigSecLevel" SG_ 1168 EAS_CtrlrVoltVld "null";
BA_ "sigConfig" SG_ 1168 EAS_CtrlrVoltVld "null";
BA_ "sigExplanation" SG_ 1168 EAS_CtrlrVoltVld "null";
BA_ "sigSecLevel" SG_ 1168 EAS_CtrlrCrtVld "null";
BA_ "sigConfig" SG_ 1168 EAS_CtrlrCrtVld "null";
BA_ "sigExplanation" SG_ 1168 EAS_CtrlrCrtVld "null";
BA_ "sigSecLevel" SG_ 1168 EAS_CtrlrVolt "null";
BA_ "sigConfig" SG_ 1168 EAS_CtrlrVolt "null";
BA_ "sigExplanation" SG_ 1168 EAS_CtrlrVolt "null";
BA_ "sigSecLevel" SG_ 1168 EAS_CtrlrCrt "null";
BA_ "sigConfig" SG_ 1168 EAS_CtrlrCrt "null";
BA_ "sigExplanation" SG_ 1168 EAS_CtrlrCrt "null";
BA_ "sigSecLevel" SG_ 1168 EAS_MotSpd "null";
BA_ "sigConfig" SG_ 1168 EAS_MotSpd "null";
BA_ "sigExplanation" SG_ 1168 EAS_MotSpd "null";
BA_ "sigSecLevel" SG_ 1169 EAS_MotCrt "null";
BA_ "sigConfig" SG_ 1169 EAS_MotCrt "null";
BA_ "sigExplanation" SG_ 1169 EAS_MotCrt "null";
BA_ "sigSecLevel" SG_ 1169 EAS_HVUnderVoltFlt "null";
BA_ "sigConfig" SG_ 1169 EAS_HVUnderVoltFlt "null";
BA_ "sigExplanation" SG_ 1169 EAS_HVUnderVoltFlt "null";
BA_ "sigSecLevel" SG_ 1169 EAS_HVOverVoltFlt "null";
BA_ "sigConfig" SG_ 1169 EAS_HVOverVoltFlt "null";
BA_ "sigExplanation" SG_ 1169 EAS_HVOverVoltFlt "null";
BA_ "sigSecLevel" SG_ 1169 EAS_CrtSts "null";
BA_ "sigConfig" SG_ 1169 EAS_CrtSts "null";
BA_ "sigExplanation" SG_ 1169 EAS_CrtSts "null";
BA_ "sigSecLevel" SG_ 1169 EAS_IninSts "null";
BA_ "sigConfig" SG_ 1169 EAS_IninSts "null";
BA_ "sigExplanation" SG_ 1169 EAS_IninSts "null";
BA_ "sigSecLevel" SG_ 1169 EAS_OverCrtFlt "null";
BA_ "sigConfig" SG_ 1169 EAS_OverCrtFlt "null";
BA_ "sigExplanation" SG_ 1169 EAS_OverCrtFlt "null";
BA_ "sigSecLevel" SG_ 1169 EAS_HVIntlkFlt "null";
BA_ "sigConfig" SG_ 1169 EAS_HVIntlkFlt "null";
BA_ "sigExplanation" SG_ 1169 EAS_HVIntlkFlt "null";
BA_ "sigSecLevel" SG_ 1169 EAS_IPMTOverFlt "null";
BA_ "sigConfig" SG_ 1169 EAS_IPMTOverFlt "null";
BA_ "sigExplanation" SG_ 1169 EAS_IPMTOverFlt "null";
BA_ "sigSecLevel" SG_ 1169 EAS_ComLost_ECC "null";
BA_ "sigConfig" SG_ 1169 EAS_ComLost_ECC "null";
BA_ "sigExplanation" SG_ 1169 EAS_ComLost_ECC "null";
BA_ "sigSecLevel" SG_ 1169 EAS_CtrlCircFlt "null";
BA_ "sigConfig" SG_ 1169 EAS_CtrlCircFlt "null";
BA_ "sigExplanation" SG_ 1169 EAS_CtrlCircFlt "null";
BA_ "sigSecLevel" SG_ 1169 EAS_IPMHwFlt "null";
BA_ "sigConfig" SG_ 1169 EAS_IPMHwFlt "null";
BA_ "sigExplanation" SG_ 1169 EAS_IPMHwFlt "null";
BA_ "sigSecLevel" SG_ 1169 EAS_IPMT "null";
BA_ "sigConfig" SG_ 1169 EAS_IPMT "null";
BA_ "sigExplanation" SG_ 1169 EAS_IPMT "null";
BA_ "sigSecLevel" SG_ 1169 EAS_CrtPwr "null";
BA_ "sigConfig" SG_ 1169 EAS_CrtPwr "null";
BA_ "sigExplanation" SG_ 1169 EAS_CrtPwr "null";
BA_ "sigSecLevel" SG_ 1268 TBOX_4F4_4F8_CheckSum "null";
BA_ "sigConfig" SG_ 1268 TBOX_4F4_4F8_CheckSum "null";
BA_ "sigExplanation" SG_ 1268 TBOX_4F4_4F8_CheckSum "null";
BA_ "sigSecLevel" SG_ 1268 TBOX_4F4_4F8_AliveCounter "null";
BA_ "sigConfig" SG_ 1268 TBOX_4F4_4F8_AliveCounter "null";
BA_ "sigExplanation" SG_ 1268 TBOX_4F4_4F8_AliveCounter "null";
BA_ "GenSigSendType" SG_ 1268 TBOX_Sw_upd 2;
BA_ "GenSigSendType" SG_ 1268 TBOX_RemFlsh 2;
BA_ "GenSigSendType" SG_ 1268 TBOX_FobdGWPartBUSUDSCom 2;
BA_ "sigSecLevel" SG_ 1268 TBOX_FobdGWPartBUSUDSCom "null";
BA_ "sigConfig" SG_ 1268 TBOX_FobdGWPartBUSUDSCom "null";
BA_ "sigExplanation" SG_ 1268 TBOX_FobdGWPartBUSUDSCom "null";
BA_ "GenSigSendType" SG_ 1268 TBOX_RemChrgInsulFctReq 2;
BA_ "sigSecLevel" SG_ 1268 TBOX_RemChrgInsulFctReq "null";
BA_ "sigConfig" SG_ 1268 TBOX_RemChrgInsulFctReq "null";
BA_ "sigExplanation" SG_ 1268 TBOX_RemChrgInsulFctReq "null";
BA_ "sigSecLevel" SG_ 1268 TBOX_EHUSetTrvlMod "null";
BA_ "sigConfig" SG_ 1268 TBOX_EHUSetTrvlMod "null";
BA_ "sigExplanation" SG_ 1268 TBOX_EHUSetTrvlMod "null";
BA_ "sigSecLevel" SG_ 1268 TBOX_ResvACChrgOpenSts "null";
BA_ "sigConfig" SG_ 1268 TBOX_ResvACChrgOpenSts "null";
BA_ "sigExplanation" SG_ 1268 TBOX_ResvACChrgOpenSts "null";
BA_ "GenSigSendType" SG_ 1268 TBOX_RemKL15PwrOnReq 2;
BA_ "sigSecLevel" SG_ 1268 TBOX_RemKL15PwrOnReq "null";
BA_ "sigConfig" SG_ 1268 TBOX_RemKL15PwrOnReq "null";
BA_ "sigExplanation" SG_ 1268 TBOX_RemKL15PwrOnReq "null";
BA_ "sigSecLevel" SG_ 1268 TBOX_SetChrgEndSOC "null";
BA_ "sigConfig" SG_ 1268 TBOX_SetChrgEndSOC "null";
BA_ "sigExplanation" SG_ 1268 TBOX_SetChrgEndSOC "null";
BA_ "sigSecLevel" SG_ 1268 TBOX_PreCondTriggerReq "null";
BA_ "sigConfig" SG_ 1268 TBOX_PreCondTriggerReq "null";
BA_ "sigExplanation" SG_ 1268 TBOX_PreCondTriggerReq "null";
BA_ "sigSecLevel" SG_ 1268 TBOX_BlowLvlReq "null";
BA_ "sigConfig" SG_ 1268 TBOX_BlowLvlReq "null";
BA_ "sigExplanation" SG_ 1268 TBOX_BlowLvlReq "null";
BA_ "GenSigSendType" SG_ 1268 TBOX_ICC_UpdStrt 2;
BA_ "sigSecLevel" SG_ 1268 TBOX_VehiMod "null";
BA_ "sigConfig" SG_ 1268 TBOX_VehiMod "null";
BA_ "sigExplanation" SG_ 1268 TBOX_VehiMod "null";
BA_ "GenSigCycleTime" SG_ 1268 TBOX_Crash_cfm 100;
BA_ "GenSigInactiveValue" SG_ 1268 TBOX_Crash_cfm 1;
BA_ "GenSigSendType" SG_ 1268 TBOX_Crash_cfm 4;
BA_ "sigSecLevel" SG_ 1268 TBOX_4F4_SSecOC_Fresh_Byte0 "null";
BA_ "sigConfig" SG_ 1268 TBOX_4F4_SSecOC_Fresh_Byte0 "null";
BA_ "sigExplanation" SG_ 1268 TBOX_4F4_SSecOC_Fresh_Byte0 "null";
BA_ "sigSecLevel" SG_ 1268 TBOX_4F4_SSecOC_MAC_Byte0 "null";
BA_ "sigConfig" SG_ 1268 TBOX_4F4_SSecOC_MAC_Byte0 "null";
BA_ "sigExplanation" SG_ 1268 TBOX_4F4_SSecOC_MAC_Byte0 "null";
BA_ "sigSecLevel" SG_ 1268 TBOX_4F4_SSecOC_MAC_Byte1 "null";
BA_ "sigConfig" SG_ 1268 TBOX_4F4_SSecOC_MAC_Byte1 "null";
BA_ "sigExplanation" SG_ 1268 TBOX_4F4_SSecOC_MAC_Byte1 "null";
BA_ "sigSecLevel" SG_ 1268 TBOX_4F4_SSecOC_MAC_Byte2 "null";
BA_ "sigConfig" SG_ 1268 TBOX_4F4_SSecOC_MAC_Byte2 "null";
BA_ "sigExplanation" SG_ 1268 TBOX_4F4_SSecOC_MAC_Byte2 "null";
BA_ "sigSecLevel" SG_ 1287 VCU_DrvAvl "null";
BA_ "sigConfig" SG_ 1287 VCU_DrvAvl "null";
BA_ "sigExplanation" SG_ 1287 VCU_DrvAvl "null";
BA_ "sigSecLevel" SG_ 1287 VCU_CllsnSigSts "null";
BA_ "sigConfig" SG_ 1287 VCU_CllsnSigSts "null";
BA_ "sigExplanation" SG_ 1287 VCU_CllsnSigSts "null";
BA_ "sigSecLevel" SG_ 1287 VCU_VehSts_GB "null";
BA_ "sigConfig" SG_ 1287 VCU_VehSts_GB "null";
BA_ "sigExplanation" SG_ 1287 VCU_VehSts_GB "null";
BA_ "sigSecLevel" SG_ 1287 VCU_MCUOverTFlt_GB "null";
BA_ "sigConfig" SG_ 1287 VCU_MCUOverTFlt_GB "null";
BA_ "sigExplanation" SG_ 1287 VCU_MCUOverTFlt_GB "null";
BA_ "sigSecLevel" SG_ 1287 VCU_DrvrMotOverTFlt_GB "null";
BA_ "sigConfig" SG_ 1287 VCU_DrvrMotOverTFlt_GB "null";
BA_ "sigExplanation" SG_ 1287 VCU_DrvrMotOverTFlt_GB "null";
BA_ "sigSecLevel" SG_ 1287 VCU_SOCTooLoAlrm "null";
BA_ "sigConfig" SG_ 1287 VCU_SOCTooLoAlrm "null";
BA_ "sigExplanation" SG_ 1287 VCU_SOCTooLoAlrm "null";
BA_ "sigSecLevel" SG_ 1287 VCU_SOCJumpAlrm "null";
BA_ "sigConfig" SG_ 1287 VCU_SOCJumpAlrm "null";
BA_ "sigExplanation" SG_ 1287 VCU_SOCJumpAlrm "null";
BA_ "sigSecLevel" SG_ 1287 VCU_PwrBattPackMismatAlrm "null";
BA_ "sigConfig" SG_ 1287 VCU_PwrBattPackMismatAlrm "null";
BA_ "sigExplanation" SG_ 1287 VCU_PwrBattPackMismatAlrm "null";
BA_ "sigSecLevel" SG_ 1287 VCU_SOCTooHiAlrm "null";
BA_ "sigConfig" SG_ 1287 VCU_SOCTooHiAlrm "null";
BA_ "sigExplanation" SG_ 1287 VCU_SOCTooHiAlrm "null";
BA_ "sigSecLevel" SG_ 1287 VCU_DCDCEnaCmd "null";
BA_ "sigConfig" SG_ 1287 VCU_DCDCEnaCmd "null";
BA_ "sigExplanation" SG_ 1287 VCU_DCDCEnaCmd "null";
BA_ "sigSecLevel" SG_ 1287 VCU_PwrBattECCEnaCmd "null";
BA_ "sigConfig" SG_ 1287 VCU_PwrBattECCEnaCmd "null";
BA_ "sigExplanation" SG_ 1287 VCU_PwrBattECCEnaCmd "null";
BA_ "sigSecLevel" SG_ 1287 VCU_MstRlyCtrlCmd "null";
BA_ "sigConfig" SG_ 1287 VCU_MstRlyCtrlCmd "null";
BA_ "sigExplanation" SG_ 1287 VCU_MstRlyCtrlCmd "null";
BA_ "sigSecLevel" SG_ 1287 VCU_DCDCOutpVoltCmd "null";
BA_ "sigConfig" SG_ 1287 VCU_DCDCOutpVoltCmd "null";
BA_ "sigExplanation" SG_ 1287 VCU_DCDCOutpVoltCmd "null";
BA_ "sigSecLevel" SG_ 1287 VCU_CCCnctnVolt "null";
BA_ "sigConfig" SG_ 1287 VCU_CCCnctnVolt "null";
BA_ "sigExplanation" SG_ 1287 VCU_CCCnctnVolt "null";
BA_ "sigSecLevel" SG_ 1287 VCU_GearSig_GB "null";
BA_ "sigConfig" SG_ 1287 VCU_GearSig_GB "null";
BA_ "sigExplanation" SG_ 1287 VCU_GearSig_GB "null";
BA_ "sigSecLevel" SG_ 1287 VCU_DrvrMotNr_GB "null";
BA_ "sigConfig" SG_ 1287 VCU_DrvrMotNr_GB "null";
BA_ "sigExplanation" SG_ 1287 VCU_DrvrMotNr_GB "null";
BA_ "sigSecLevel" SG_ 1287 VCU_BattVolt "null";
BA_ "sigConfig" SG_ 1287 VCU_BattVolt "null";
BA_ "sigExplanation" SG_ 1287 VCU_BattVolt "null";
BA_ "sigSecLevel" SG_ 1297 VCU_BMSLVWakeUpSts "null";
BA_ "sigConfig" SG_ 1297 VCU_BMSLVWakeUpSts "null";
BA_ "sigExplanation" SG_ 1297 VCU_BMSLVWakeUpSts "null";
BA_ "sigSecLevel" SG_ 1297 VCU_ONWakeUpSig "null";
BA_ "sigConfig" SG_ 1297 VCU_ONWakeUpSig "null";
BA_ "sigExplanation" SG_ 1297 VCU_ONWakeUpSig "null";
BA_ "sigSecLevel" SG_ 1297 VCU_FCWakeUpSig "null";
BA_ "sigConfig" SG_ 1297 VCU_FCWakeUpSig "null";
BA_ "sigExplanation" SG_ 1297 VCU_FCWakeUpSig "null";
BA_ "sigSecLevel" SG_ 1297 VCU_SCWakeUpSig "null";
BA_ "sigConfig" SG_ 1297 VCU_SCWakeUpSig "null";
BA_ "sigExplanation" SG_ 1297 VCU_SCWakeUpSig "null";
BA_ "sigSecLevel" SG_ 1297 VCU_RemWakeUpSig "null";
BA_ "sigConfig" SG_ 1297 VCU_RemWakeUpSig "null";
BA_ "sigExplanation" SG_ 1297 VCU_RemWakeUpSig "null";
BA_ "sigSecLevel" SG_ 1297 VCU_NetWakeUpSig "null";
BA_ "sigConfig" SG_ 1297 VCU_NetWakeUpSig "null";
BA_ "sigExplanation" SG_ 1297 VCU_NetWakeUpSig "null";
BA_ "sigSecLevel" SG_ 1297 VCU_LVWakeUpSts_PDU "null";
BA_ "sigConfig" SG_ 1297 VCU_LVWakeUpSts_PDU "null";
BA_ "sigExplanation" SG_ 1297 VCU_LVWakeUpSts_PDU "null";
BA_ "sigSecLevel" SG_ 1297 VCU_VehEOLFctFlg "null";
BA_ "sigConfig" SG_ 1297 VCU_VehEOLFctFlg "null";
BA_ "sigExplanation" SG_ 1297 VCU_VehEOLFctFlg "null";
BA_ "sigSecLevel" SG_ 1297 VCU_LVWakeUpSts_MCU "null";
BA_ "sigConfig" SG_ 1297 VCU_LVWakeUpSts_MCU "null";
BA_ "sigExplanation" SG_ 1297 VCU_LVWakeUpSts_MCU "null";
BA_ "sigSecLevel" SG_ 1297 VCU_PwrAntithefAllwtRdyFlg "null";
BA_ "sigConfig" SG_ 1297 VCU_PwrAntithefAllwtRdyFlg "null";
BA_ "sigExplanation" SG_ 1297 VCU_PwrAntithefAllwtRdyFlg "null";
BA_ "sigSecLevel" SG_ 1297 VCU_LVWakeUpSts_CCU "null";
BA_ "sigConfig" SG_ 1297 VCU_LVWakeUpSts_CCU "null";
BA_ "sigExplanation" SG_ 1297 VCU_LVWakeUpSts_CCU "null";
BA_ "sigSecLevel" SG_ 1297 VCU_RemECCEndCmd "null";
BA_ "sigConfig" SG_ 1297 VCU_RemECCEndCmd "null";
BA_ "sigExplanation" SG_ 1297 VCU_RemECCEndCmd "null";
BA_ "sigSecLevel" SG_ 1297 VCU_EvChrgElectcLockCtrlCmd "null";
BA_ "sigConfig" SG_ 1297 VCU_EvChrgElectcLockCtrlCmd "null";
BA_ "sigExplanation" SG_ 1297 VCU_EvChrgElectcLockCtrlCmd "null";
BA_ "sigSecLevel" SG_ 1297 VCU_RemPwrBattHeatgEndCmd "null";
BA_ "sigConfig" SG_ 1297 VCU_RemPwrBattHeatgEndCmd "null";
BA_ "sigExplanation" SG_ 1297 VCU_RemPwrBattHeatgEndCmd "null";
BA_ "sigSecLevel" SG_ 1297 VCU_RemChrgEndCmd "null";
BA_ "sigConfig" SG_ 1297 VCU_RemChrgEndCmd "null";
BA_ "sigExplanation" SG_ 1297 VCU_RemChrgEndCmd "null";
BA_ "sigSecLevel" SG_ 1297 VCU_RemBattHeatgFailReason "null";
BA_ "sigConfig" SG_ 1297 VCU_RemBattHeatgFailReason "null";
BA_ "sigExplanation" SG_ 1297 VCU_RemBattHeatgFailReason "null";
BA_ "sigSecLevel" SG_ 1297 VCU_RemECCEndReason "null";
BA_ "sigConfig" SG_ 1297 VCU_RemECCEndReason "null";
BA_ "sigExplanation" SG_ 1297 VCU_RemECCEndReason "null";
BA_ "sigSecLevel" SG_ 1297 VCU_RemChrgEndReason "null";
BA_ "sigConfig" SG_ 1297 VCU_RemChrgEndReason "null";
BA_ "sigExplanation" SG_ 1297 VCU_RemChrgEndReason "null";
BA_ "GenSigStartValue" SG_ 1297 VCU_VehMod 14;
BA_ "sigSecLevel" SG_ 1297 VCU_VehMod "null";
BA_ "sigConfig" SG_ 1297 VCU_VehMod "null";
BA_ "sigExplanation" SG_ 1297 VCU_VehMod "null";
BA_ "sigSecLevel" SG_ 1297 VCU_VehCrtChrgEndSOC "null";
BA_ "sigConfig" SG_ 1297 VCU_VehCrtChrgEndSOC "null";
BA_ "sigExplanation" SG_ 1297 VCU_VehCrtChrgEndSOC "null";
BA_ "sigSecLevel" SG_ 1297 VCU_CalSwVers "null";
BA_ "sigConfig" SG_ 1297 VCU_CalSwVers "null";
BA_ "sigExplanation" SG_ 1297 VCU_CalSwVers "null";
BA_ "sigSecLevel" SG_ 1297 VCU_RemPwrBattPreheatgEndFlg "null";
BA_ "sigConfig" SG_ 1297 VCU_RemPwrBattPreheatgEndFlg "null";
BA_ "sigExplanation" SG_ 1297 VCU_RemPwrBattPreheatgEndFlg "null";
BA_ "sigSecLevel" SG_ 1297 VCU_VehOperMod "null";
BA_ "sigConfig" SG_ 1297 VCU_VehOperMod "null";
BA_ "sigExplanation" SG_ 1297 VCU_VehOperMod "null";
BA_ "sigSecLevel" SG_ 1297 VCU_VehRemRefrshModReq "null";
BA_ "sigConfig" SG_ 1297 VCU_VehRemRefrshModReq "null";
BA_ "sigExplanation" SG_ 1297 VCU_VehRemRefrshModReq "null";
BA_ "sigSecLevel" SG_ 1297 VCU_RemDTCPwrOnReq "null";
BA_ "sigConfig" SG_ 1297 VCU_RemDTCPwrOnReq "null";
BA_ "sigExplanation" SG_ 1297 VCU_RemDTCPwrOnReq "null";
BA_ "sigSecLevel" SG_ 1329 ICC_TotMilgVld_ODO "null";
BA_ "sigConfig" SG_ 1329 ICC_TotMilgVld_ODO "null";
BA_ "sigExplanation" SG_ 1329 ICC_TotMilgVld_ODO "null";
BA_ "sigSecLevel" SG_ 1329 ICC_TotMilg_ODO "null";
BA_ "sigConfig" SG_ 1329 ICC_TotMilg_ODO "null";
BA_ "sigExplanation" SG_ 1329 ICC_TotMilg_ODO "null";
BA_ "sigSecLevel" SG_ 1329 ICC_DispVehSpd "null";
BA_ "sigConfig" SG_ 1329 ICC_DispVehSpd "null";
BA_ "sigExplanation" SG_ 1329 ICC_DispVehSpd "null";
BA_ "sigSecLevel" SG_ 1329 ICC_DispVehSpdUnit "null";
BA_ "sigConfig" SG_ 1329 ICC_DispVehSpdUnit "null";
BA_ "sigExplanation" SG_ 1329 ICC_DispVehSpdUnit "null";
BA_ "sigSecLevel" SG_ 1329 ICC_ADASSigFlt "null";
BA_ "sigConfig" SG_ 1329 ICC_ADASSigFlt "null";
BA_ "sigExplanation" SG_ 1329 ICC_ADASSigFlt "null";
BA_ "sigSecLevel" SG_ 1329 ICC_DispFlt "null";
BA_ "sigConfig" SG_ 1329 ICC_DispFlt "null";
BA_ "sigExplanation" SG_ 1329 ICC_DispFlt "null";
BA_ "sigSecLevel" SG_ 1429 BMS_RmChrgTi_FullChrg "null";
BA_ "sigConfig" SG_ 1429 BMS_RmChrgTi_FullChrg "null";
BA_ "sigExplanation" SG_ 1429 BMS_RmChrgTi_FullChrg "null";
BA_ "sigSecLevel" SG_ 1429 BMS_RmChrgTi_TrgtSoC "null";
BA_ "sigConfig" SG_ 1429 BMS_RmChrgTi_TrgtSoC "null";
BA_ "sigExplanation" SG_ 1429 BMS_RmChrgTi_TrgtSoC "null";
BA_ "sigSecLevel" SG_ 1476 TBOX_TerminalRemWakeupSig "null";
BA_ "sigConfig" SG_ 1476 TBOX_TerminalRemWakeupSig "null";
BA_ "sigExplanation" SG_ 1476 TBOX_TerminalRemWakeupSig "null";
BA_ "sigSecLevel" SG_ 1476 TBOX_RemSCModReq "null";
BA_ "sigConfig" SG_ 1476 TBOX_RemSCModReq "null";
BA_ "sigExplanation" SG_ 1476 TBOX_RemSCModReq "null";
BA_ "sigSecLevel" SG_ 1476 TBOX_RemPwrBattOpenHeatgReq "null";
BA_ "sigConfig" SG_ 1476 TBOX_RemPwrBattOpenHeatgReq "null";
BA_ "sigExplanation" SG_ 1476 TBOX_RemPwrBattOpenHeatgReq "null";
BA_ "sigSecLevel" SG_ 1476 TBOX_RemPwrBattResvHeatgReq "null";
BA_ "sigConfig" SG_ 1476 TBOX_RemPwrBattResvHeatgReq "null";
BA_ "sigExplanation" SG_ 1476 TBOX_RemPwrBattResvHeatgReq "null";
BA_ "sigSecLevel" SG_ 1476 TBOX_RemInsdInfoDispEna "null";
BA_ "sigConfig" SG_ 1476 TBOX_RemInsdInfoDispEna "null";
BA_ "sigExplanation" SG_ 1476 TBOX_RemInsdInfoDispEna "null";
BA_ "sigSecLevel" SG_ 1476 TBOX_RemECCDefrstModReq "null";
BA_ "sigConfig" SG_ 1476 TBOX_RemECCDefrstModReq "null";
BA_ "sigExplanation" SG_ 1476 TBOX_RemECCDefrstModReq "null";
BA_ "sigSecLevel" SG_ 1476 TBOX_RemECCResvDefrstReq "null";
BA_ "sigConfig" SG_ 1476 TBOX_RemECCResvDefrstReq "null";
BA_ "sigExplanation" SG_ 1476 TBOX_RemECCResvDefrstReq "null";
BA_ "sigSecLevel" SG_ 1476 TBOX_RemECCSetT "null";
BA_ "sigConfig" SG_ 1476 TBOX_RemECCSetT "null";
BA_ "sigExplanation" SG_ 1476 TBOX_RemECCSetT "null";
BA_ "sigSecLevel" SG_ 1476 TBOX_RemResvECCSetT "null";
BA_ "sigConfig" SG_ 1476 TBOX_RemResvECCSetT "null";
BA_ "sigExplanation" SG_ 1476 TBOX_RemResvECCSetT "null";
BA_ "sigSecLevel" SG_ 1476 TBOX_RemSOCMax "null";
BA_ "sigConfig" SG_ 1476 TBOX_RemSOCMax "null";
BA_ "sigExplanation" SG_ 1476 TBOX_RemSOCMax "null";
BA_ "sigSecLevel" SG_ 1476 TBOX_4GSigIND "null";
BA_ "sigConfig" SG_ 1476 TBOX_4GSigIND "null";
BA_ "sigExplanation" SG_ 1476 TBOX_4GSigIND "null";
BA_ "sigSecLevel" SG_ 1476 TBOX_TSPNotConn "null";
BA_ "sigConfig" SG_ 1476 TBOX_TSPNotConn "null";
BA_ "sigExplanation" SG_ 1476 TBOX_TSPNotConn "null";
BA_ "sigSecLevel" SG_ 1476 TBOX_EHUNotCONN "null";
BA_ "sigConfig" SG_ 1476 TBOX_EHUNotCONN "null";
BA_ "sigExplanation" SG_ 1476 TBOX_EHUNotCONN "null";
BA_ "sigSecLevel" SG_ 1476 TBOX_WIFIError "null";
BA_ "sigConfig" SG_ 1476 TBOX_WIFIError "null";
BA_ "sigExplanation" SG_ 1476 TBOX_WIFIError "null";
BA_ "sigSecLevel" SG_ 1476 TBOX_InnerBattError "null";
BA_ "sigConfig" SG_ 1476 TBOX_InnerBattError "null";
BA_ "sigExplanation" SG_ 1476 TBOX_InnerBattError "null";
BA_ "sigSecLevel" SG_ 1476 TBOX_VoltLow "null";
BA_ "sigConfig" SG_ 1476 TBOX_VoltLow "null";
BA_ "sigExplanation" SG_ 1476 TBOX_VoltLow "null";
BA_ "sigSecLevel" SG_ 1476 TBOX_VoltHigh "null";
BA_ "sigConfig" SG_ 1476 TBOX_VoltHigh "null";
BA_ "sigExplanation" SG_ 1476 TBOX_VoltHigh "null";
BA_ "sigSecLevel" SG_ 1476 TBOX_4GLoss "null";
BA_ "sigConfig" SG_ 1476 TBOX_4GLoss "null";
BA_ "sigExplanation" SG_ 1476 TBOX_4GLoss "null";
BA_ "sigSecLevel" SG_ 1476 TBOX_RemSWH_Req "null";
BA_ "sigConfig" SG_ 1476 TBOX_RemSWH_Req "null";
BA_ "sigExplanation" SG_ 1476 TBOX_RemSWH_Req "null";
BA_ "sigSecLevel" SG_ 1476 TBOX_5C4_SSecOC_Fresh_Byte0 "null";
BA_ "sigConfig" SG_ 1476 TBOX_5C4_SSecOC_Fresh_Byte0 "null";
BA_ "sigExplanation" SG_ 1476 TBOX_5C4_SSecOC_Fresh_Byte0 "null";
BA_ "sigSecLevel" SG_ 1476 TBOX_5C4_SSecOC_MAC_Byte0 "null";
BA_ "sigConfig" SG_ 1476 TBOX_5C4_SSecOC_MAC_Byte0 "null";
BA_ "sigExplanation" SG_ 1476 TBOX_5C4_SSecOC_MAC_Byte0 "null";
BA_ "sigSecLevel" SG_ 1476 TBOX_5C4_SSecOC_MAC_Byte1 "null";
BA_ "sigConfig" SG_ 1476 TBOX_5C4_SSecOC_MAC_Byte1 "null";
BA_ "sigExplanation" SG_ 1476 TBOX_5C4_SSecOC_MAC_Byte1 "null";
BA_ "sigSecLevel" SG_ 1476 TBOX_5C4_SSecOC_MAC_Byte2 "null";
BA_ "sigConfig" SG_ 1476 TBOX_5C4_SSecOC_MAC_Byte2 "null";
BA_ "sigExplanation" SG_ 1476 TBOX_5C4_SSecOC_MAC_Byte2 "null";
BA_ "GenSigSendType" SG_ 1562 TBOX_RemDTCDmd 5;
BA_ "sigSecLevel" SG_ 1562 TBOX_RemDTCDmd "null";
BA_ "sigConfig" SG_ 1562 TBOX_RemDTCDmd "null";
BA_ "sigExplanation" SG_ 1562 TBOX_RemDTCDmd "null";
BA_ "GenSigStartValue" SG_ 1583 TBOX_ZoneT 48;
BA_ "sigSecLevel" SG_ 1583 TBOX_CrtTi_Day "null";
BA_ "sigConfig" SG_ 1583 TBOX_CrtTi_Day "null";
BA_ "sigExplanation" SG_ 1583 TBOX_CrtTi_Day "null";
BA_ "sigSecLevel" SG_ 1583 TBOX_CrtTi_Hr "null";
BA_ "sigConfig" SG_ 1583 TBOX_CrtTi_Hr "null";
BA_ "sigExplanation" SG_ 1583 TBOX_CrtTi_Hr "null";
BA_ "sigSecLevel" SG_ 1583 TBOX_CrtTi_Mins "null";
BA_ "sigConfig" SG_ 1583 TBOX_CrtTi_Mins "null";
BA_ "sigExplanation" SG_ 1583 TBOX_CrtTi_Mins "null";
BA_ "sigSecLevel" SG_ 1583 TBOX_CrtTi_Yr "null";
BA_ "sigConfig" SG_ 1583 TBOX_CrtTi_Yr "null";
BA_ "sigExplanation" SG_ 1583 TBOX_CrtTi_Yr "null";
BA_ "sigSecLevel" SG_ 1583 TBOX_CrtTi_Mth "null";
BA_ "sigConfig" SG_ 1583 TBOX_CrtTi_Mth "null";
BA_ "sigExplanation" SG_ 1583 TBOX_CrtTi_Mth "null";
BA_ "sigSecLevel" SG_ 1583 TBOX_CrtTi_Sec "null";
BA_ "sigConfig" SG_ 1583 TBOX_CrtTi_Sec "null";
BA_ "sigExplanation" SG_ 1583 TBOX_CrtTi_Sec "null";
BA_ "sigSecLevel" SG_ 1594 BMS_Splr "null";
BA_ "sigConfig" SG_ 1594 BMS_Splr "null";
BA_ "sigExplanation" SG_ 1594 BMS_Splr "null";
BA_ "sigSecLevel" SG_ 1594 BMS_PwrBattTyp "null";
BA_ "sigConfig" SG_ 1594 BMS_PwrBattTyp "null";
BA_ "sigExplanation" SG_ 1594 BMS_PwrBattTyp "null";
BA_ "sigSecLevel" SG_ 1594 BMS_PwrBattPwrStsSOH "null";
BA_ "sigConfig" SG_ 1594 BMS_PwrBattPwrStsSOH "null";
BA_ "sigExplanation" SG_ 1594 BMS_PwrBattPwrStsSOH "null";
BA_ "sigSecLevel" SG_ 1594 BMS_PwrBattPackSerlNr "null";
BA_ "sigConfig" SG_ 1594 BMS_PwrBattPackSerlNr "null";
BA_ "sigExplanation" SG_ 1594 BMS_PwrBattPackSerlNr "null";
BA_ "sigSecLevel" SG_ 1594 BMS_PwrBattPackPrllNr "null";
BA_ "sigConfig" SG_ 1594 BMS_PwrBattPackPrllNr "null";
BA_ "sigExplanation" SG_ 1594 BMS_PwrBattPackPrllNr "null";
BA_ "sigSecLevel" SG_ 1594 BMS_CellCp "null";
BA_ "sigConfig" SG_ 1594 BMS_CellCp "null";
BA_ "sigExplanation" SG_ 1594 BMS_CellCp "null";
BA_ "sigSecLevel" SG_ 1594 BMS_DchaEndCellVolt "null";
BA_ "sigConfig" SG_ 1594 BMS_DchaEndCellVolt "null";
BA_ "sigExplanation" SG_ 1594 BMS_DchaEndCellVolt "null";
BA_ "sigSecLevel" SG_ 1604 ECC_644_CheckSum "null";
BA_ "sigConfig" SG_ 1604 ECC_644_CheckSum "null";
BA_ "sigExplanation" SG_ 1604 ECC_644_CheckSum "null";
BA_ "sigSecLevel" SG_ 1604 ECC_644_AliveCounter "null";
BA_ "sigConfig" SG_ 1604 ECC_644_AliveCounter "null";
BA_ "sigExplanation" SG_ 1604 ECC_644_AliveCounter "null";
BA_ "GenSigStartValue" SG_ 1604 ECC_ReMotOutlT 48;
BA_ "sigSecLevel" SG_ 1604 ECC_ReMotOutlT "null";
BA_ "sigConfig" SG_ 1604 ECC_ReMotOutlT "null";
BA_ "sigExplanation" SG_ 1604 ECC_ReMotOutlT "null";
BA_ "sigSecLevel" SG_ 1604 ECC_CoolgDfct "null";
BA_ "sigConfig" SG_ 1604 ECC_CoolgDfct "null";
BA_ "sigExplanation" SG_ 1604 ECC_CoolgDfct "null";
BA_ "sigSecLevel" SG_ 1604 ECC_CooltHomSts "null";
BA_ "sigConfig" SG_ 1604 ECC_CooltHomSts "null";
BA_ "sigExplanation" SG_ 1604 ECC_CooltHomSts "null";
BA_ "GenSigStartValue" SG_ 1604 ECC_PDUInlT 48;
BA_ "sigSecLevel" SG_ 1604 ECC_PDUInlT "null";
BA_ "sigConfig" SG_ 1604 ECC_PDUInlT "null";
BA_ "sigExplanation" SG_ 1604 ECC_PDUInlT "null";
BA_ "GenSigStartValue" SG_ 1604 ECC_FrntMotOutlT 48;
BA_ "sigSecLevel" SG_ 1604 ECC_FrntMotOutlT "null";
BA_ "sigConfig" SG_ 1604 ECC_FrntMotOutlT "null";
BA_ "sigExplanation" SG_ 1604 ECC_FrntMotOutlT "null";
BA_ "GenSigStartValue" SG_ 1604 ECC_MCURInlT 48;
BA_ "sigSecLevel" SG_ 1604 ECC_MCURInlT "null";
BA_ "sigConfig" SG_ 1604 ECC_MCURInlT "null";
BA_ "sigExplanation" SG_ 1604 ECC_MCURInlT "null";
VAL_ 792 ESP_BrkPedlStsVld 0 "Initializing" 1 "Valid" 2 "Invalid" 3 "Reserved" ;
VAL_ 792 ESP_BrkPedlSts 0 "Brake_Pedal_Not_Pressed" 1 "Brake_Pedal_Pressed" ;
VAL_ 792 ESP_VehSpdVld 0 "Initializing" 1 "Valid" 2 "Invalid" 3 "Reserved" ;
VAL_ 792 ESP_SysActv 0 "No_Telltale_Requested" 1 "Telltale_Requested" ;
VAL_ 792 ESP_LampSwtOffIndcn 0 "No_Telltale_Requested" 1 "Telltale_Requested" ;
VAL_ 792 ESP_FltIndcn_EBD 0 "No_Telltale_Requested" 1 "Telltale_Requested" ;
VAL_ 792 ESP_FltIndcn_ABS 0 "No_Telltale_Requested" 1 "Telltale_Requested" ;
VAL_ 792 ESP_IninModSigIndcn 0 "Not_In_Initialization_Mode" 1 "In_Intialization_Mode" ;
VAL_ 792 ESP_FltIndcn_TCS 0 "No_Telltale_Requested" 1 "Telltale_Requested" ;
VAL_ 792 ESP_CtrlSts_HDC 0 "Off" 1 "On_Active_Braking" 2 "On_Not_Active_Braking" 3 "Reserved" ;
VAL_ 792 ESP_AvlIndcn_HDC 0 "Available" 1 "Not_Available" ;
VAL_ 792 ESP_NoBrkP 0 "Exist_Brk_Force" 1 "No_Brk_Force" ;
VAL_ 792 ESP_RDAEnaFlg 0 "Inactive_not_enabled" 1 "Active_enable" ;
VAL_ 816 BMS_VehInsulFltDisp 0 "Normal" 1 "Abnormal" ;
VAL_ 816 BMS_PwrBattSysFltDisp 0 "Normal" 1 "Abnormal" ;
VAL_ 816 BMS_PwrBattAvlCp 65535 "Invalid" ;
VAL_ 816 BMS_CellMinTAlrm 0 "No_fault" 1 "Fault" ;
VAL_ 816 BMS_PwrBattThermRunawayAlrm 0 "No_Thermal_Runaway" 1 "Thermal_Runaway_Detected" ;
VAL_ 816 BMS_PwrBattOverT 0 "Normal" 1 "Abnormal" ;
VAL_ 816 BMS_PwrBattInsulSts 0 "Initial_value" 1 "Not_thermally_insulated" 2 "Thermally_insulated" 3 "Thermal_insulation_is_on_for_the_power_battery_is_at_low_temperature" ;
VAL_ 819 BCM_KL15_Off_Announcement 0 "NotAvailable" 1 "No_Announcement" 2 "KL15_shutdown_announced" 3 "Reserved" ;
VAL_ 819 BCM_IG1Sts 0 "NotAvailable" 1 "Inactive" 2 "Active" 3 "Reserved" ;
VAL_ 819 BCM_PwrMod 0 "Off" 1 "ACC_(Reserved)" 2 "IGN_On" 3 "Crank_Pending_(Power_Anti-theft_Certification_Process)" 4 "Run" 5 "Crank_Off_(Reserved)" 6 "Reserved" 7 "Reserved" ;
VAL_ 819 BCM_PwrModVld 0 "Initializing" 1 "Valid" 2 "Invalid" 3 "Reserved" ;
VAL_ 819 BCM_BrkSwtSts 0 "No_Pressed" 1 "Pressed" ;
VAL_ 819 BCM_IG1StsVld_CAPE 0 "Initializing" 1 "Valid" 2 "Invalid" 3 "Reserved" ;
VAL_ 819 BCM_IG2StsVld_CAPE 0 "Initializing" 1 "Valid" 2 "Invalid" 3 "Reserved" ;
VAL_ 819 BCM_KL30s_L 0 "Not_Available" 1 "Inactive" 2 "Active" 3 "Reserved" ;
VAL_ 819 BCM_IG2Sts 0 "Not_Available" 1 "Inactive" 2 "Active" 3 "Reserved" ;
VAL_ 819 BCM_InteriorSwtSt 0 "Inactive" 1 "pressed" 2 "reserved" 3 "reserved" ;
VAL_ 856 VCU_KickdwnFlg 0 "Inactive" 1 "Active" 3 "Invalid" ;
VAL_ 856 VCU_EPedlEnaSig 0 "Not_enabled" 1 "Enable" ;
VAL_ 856 VCU_ComLostFlt_ESP 0 "Normal" 1 "Abnormal" ;
VAL_ 856 VCU_ComFlt_iBooster 0 "Normal" 1 "Abnormal" ;
VAL_ 856 VCU_RegenLvlFb 0 "Off" 1 "Normal" 2 "High" 3 "Invalid" ;
VAL_ 856 VCU_AccelModFb 0 "Low" 1 "Medium_" 2 "High" 3 "Invalid" ;
VAL_ 856 VCU_EPedlStsFb 0 "OnePedalDrive" 1 "Roll" 2 "Creep" 3 "Invalid" ;
VAL_ 856 VCU_CcTrgSpdDisp 255 "no_display" ;
VAL_ 856 VCU_Sts_CC_ICC 0 "Off" 1 "Initialization" 2 "Standby" 3 "Active" 4 "Override" 5 "Reserved" 6 "Reserved" 7 "Deactivation_brake" 8 "Deactivation_other" 9 "Failure_reversible" 10 "Failure_irreversible" 11 "Reserved" 12 "Reserved" 13 "Reserved" 14 "Reserved" 15 "Reserved" ;
VAL_ 856 VCU_CCIconDisp 0 "No_Display" 1 "White" 2 "Green" 3 "Fault" 4 "Reserved" 5 "Reserved" 6 "Reserved" 7 "Reserved" ;
VAL_ 856 VCU_DispSpdUnit_CC 0 "KMH" 1 "MPH" ;
VAL_ 856 VCU_BoostEnStat 0 "Default" 1 "Boost_unavailable:_Max_activation_number_exceeded" 2 "Boost_unavailable:_Drive_Mode" 3 "Boost_unavailable:_EDU_Coolant_Inlet_Temperature" 4 "Boost_unavailable:_EDU_Coolant_Flow" 5 "Boost_unavailable:_EDU_Stator/_Rotor_Temperature" 6 "Boost_unavailable:_EDU_Decoupling_Unit_open" 7 "Boost_unavailable:_Battery_limitation" 8 "Boost_available" 9 "Boost_active" 10 "Boost_unavailable:_vehicle_not_in_standstil" 11 "Boost_unavailable:_multiple_causes" 15 "invalid" ;
VAL_ 856 VCU_OTARdy_Fb 0 "Initial" 1 "Ready" 2 "Not_Ready" 3 "Invalid" ;
VAL_ 856 VCU_OTA_ECUInhb_Req 0 "Init" 1 "Inhibit_Request" 2 "No_Inhibit_request" 3 "Invalid" ;
VAL_ 856 VCU_OTAVehCdnChk_ASIL 0 "OTA_veh_cond_not_ok" 1 "OTA_veh_cond_ok" 2 "Fault" 3 "Invalid" ;
VAL_ 856 VCU_OTAVehInhb_ASIL_Fb 0 "Inhibition_not_ok" 1 "Inhibition_ok" 2 "Reserved" 3 "Invalid" ;
VAL_ 864 BMS_PwrBattPosGNDInsulRrel 65535 "Invalid" ;
VAL_ 864 BMS_PwrBattNegGNDInsulRrel 65535 "Invalid" ;
VAL_ 864 BMS_PwrBattPosGNDInsulR 65535 "Invalid" ;
VAL_ 864 BMS_PwrBattNegGNDInsulR 65535 "Invalid" ;
VAL_ 882 BMS_OTARdy_Fb 0 "Initial" 1 "Ready" 2 "Not_Ready" 3 "Invalid" ;
VAL_ 882 BMS_CellMinT 255 "Invalid" ;
VAL_ 882 BMS_CellMaxT 255 "Invalid" ;
VAL_ 882 BMS_BattAvrgT 255 "Invalid" ;
VAL_ 882 BMS_PwrBattHeatgMngDmd 0 "BMS_initialisation" 1 "Heating_demand" 2 "Cooling_demand" 3 "cycling" ;
VAL_ 882 BMS_ECCSysAllwDwnPwrCmd 0 "Power_reduction_not_allowed" 1 "Power_reduction_allowed" ;
VAL_ 882 BMS_BattInlTDmd 255 "Invalid" ;
VAL_ 883 ECC_CrtSts 0 "Load_initialization" 1 "Low-voltage_state" 2 "Local_high_voltage_state" 3 "Local_charge_state" 4 "Remote_working_state" 5 "High_voltage_discharge_state" 6 "Delay_state" 7 "Reserved" 8 "Reserved" 9 "Reserved" 10 "Reserved" 11 "Reserved" 12 "Reserved" 13 "Reserved" 14 "Reserved" 15 "Reserved" ;
VAL_ 883 ECC_IninSts 0 "Incomplete_initialization" 1 "initialization_completed" ;
VAL_ 883 ECC_PwrSysHeatMngtSts 0 "No_action" 1 "Self_circulation_state" 2 "Forced_cooling" 3 "Reserved" ;
VAL_ 883 ECC_ACSts 0 "Off_state" 1 "ON_state" ;
VAL_ 883 ECC_AirClnSts 0 "Not_ON" 1 "On" ;
VAL_ 883 ECC_WindSpdSts 0 "Windless_gear" 1 "First_gear_of_wind_speed" 2 "Wind_speed_second_gear" 3 "third_gear_of_wind_speed" 4 "wind_speed_fourth_gear" 5 "Wind_speed_fifth_gear" 6 "Wind_speed_six" 7 "Wind_speed_seven_gear" 8 "Reserved" 9 "Reserved" 10 "Reserved" 11 "Reserved" 12 "Reserved" 13 "Reserved" 14 "Reserved" 15 "Reserved" ;
VAL_ 883 ECC_BackRowAirOutlModSts 0 "Rear_face_blowing" 1 "Face_blowing_foot_blowing_of_rear_row" 2 "Foot_blowing_of_rear_row" 3 "Back_row_cutoff" 4 "Reserved" 5 "Reserved" 6 "Reserved" 7 "Reserved" ;
VAL_ 883 ECC_DrvrTSetSts 0 "Inactive" 1 "Low" 2 "Low" 3 "Low" 4 "Low" 5 "Low" 6 "Low" 7 "Low" 8 "Low" 9 "Low" 10 "Low" 11 "Low" 12 "Low" 13 "Low" 14 "Low" 15 "Low" 16 "Low" 17 "Low" 18 "Low" 19 "Low" 20 "Low" 21 "Low" 22 "Low" 23 "Low" 24 "Low" 25 "Low" 26 "Low" 27 "Low" 28 "Low" 29 "Low" 30 "Low" 31 "Low" 32 "Low" 33 "Low" 34 "Low" 35 "Low" 36 "18¡æ" 37 "18.5¡æ" 38 "19¡æ" 39 "19.5¡æ" 40 "20¡æ" 41 "20.5¡æ" 42 "21¡æ" 43 "21.5¡æ" 44 "22¡æ" 45 "22.5¡æ" 46 "23¡æ" 47 "23.5¡æ" 48 "24¡æ" 49 "24.5¡æ" 50 "25¡æ" 51 "25.5¡æ" 52 "26¡æ" 53 "26.5¡æ" 54 "27¡æ" 55 "27.5¡æ" 56 "28¡æ" 57 "28.5¡æ" 58 "29¡æ" 59 "29.5¡æ" 60 "30¡æ" 61 "30.5¡æ" 62 "31¡æ" 63 "31.5¡æ" 64 "32¡æ" 65 "High" 66 "High" 67 "High" 68 "High" 69 "High" 70 "High" 71 "High" 72 "High" 73 "High" 74 "High" 75 "High" 76 "High" 77 "High" 78 "High" 79 "High" 80 "High" 81 "High" 82 "High" 83 "High" 84 "High" 85 "High" 86 "High" 87 "High" 88 "High" 89 "High" 90 "High" 91 "High" 92 "High" 93 "High" 94 "High" 95 "High" 96 "High" 97 "High" 98 "High" 99 "High" 100 "High" 101 "High" 102 "High" 103 "High" 104 "High" 105 "High" 106 "High" 107 "High" 108 "High" 109 "High" 110 "High" 111 "High" 112 "High" 113 "High" 114 "High" 115 "High" 116 "High" 117 "High" 118 "High" 119 "High" 120 "High" 121 "High" 122 "High" 123 "High" 124 "High" 125 "High" 126 "High" 127 "High" 128 "High" 129 "High" 130 "High" 131 "High" 132 "High" 133 "High" 134 "High" 135 "High" 136 "High" 137 "High" 138 "High" 139 "High" 140 "High" 141 "High" 142 "High" 143 "High" 144 "High" 145 "High" 146 "High" 147 "High" 148 "High" 149 "High" 150 "High" 151 "High" 152 "High" 153 "High" 154 "High" 155 "High" 156 "High" 157 "High" 158 "High" 159 "High" 160 "High" 161 "High" 162 "High" 163 "High" 164 "High" 165 "High" 166 "High" 167 "High" 168 "High" 169 "High" 170 "High" 171 "High" 172 "High" 173 "High" 174 "High" 175 "High" 176 "High" 177 "High" 178 "High" 179 "High" 180 "High" 181 "High" 182 "High" 183 "High" 184 "High" 185 "High" 186 "High" 187 "High" 188 "High" 189 "High" 190 "High" 191 "High" 192 "High" 193 "High" 194 "High" 195 "High" 196 "High" 197 "High" 198 "High" 199 "High" 200 "High" 201 "High" 202 "High" 203 "High" 204 "High" 205 "High" 206 "High" 207 "High" 208 "High" 209 "High" 210 "High" 211 "High" 212 "High" 213 "High" 214 "High" 215 "High" 216 "High" 217 "High" 218 "High" 219 "High" 220 "High" 221 "High" 222 "High" 223 "High" 224 "High" 225 "High" 226 "High" 227 "High" 228 "High" 229 "High" 230 "High" 231 "High" 232 "High" 233 "High" 234 "High" 235 "High" 236 "High" 237 "High" 238 "High" 239 "High" 240 "High" 241 "High" 242 "High" 243 "High" 244 "High" 245 "High" 246 "High" 247 "High" 248 "High" 249 "High" 250 "High" 251 "High" 252 "High" 253 "High" 254 "High" 255 "Invalid" ;
VAL_ 883 ECC_PassTSetSts 0 "Inactive" 1 "Low" 2 "Low" 3 "Low" 4 "Low" 5 "Low" 6 "Low" 7 "Low" 8 "Low" 9 "Low" 10 "Low" 11 "Low" 12 "Low" 13 "Low" 14 "Low" 15 "Low" 16 "Low" 17 "Low" 18 "Low" 19 "Low" 20 "Low" 21 "Low" 22 "Low" 23 "Low" 24 "Low" 25 "Low" 26 "Low" 27 "Low" 28 "Low" 29 "Low" 30 "Low" 31 "Low" 32 "Low" 33 "Low" 34 "Low" 35 "Low" 36 "18¡æ" 37 "18.5¡æ" 38 "19¡æ" 39 "19.5¡æ" 40 "20¡æ" 41 "20.5¡æ" 42 "21¡æ" 43 "21.5¡æ" 44 "22¡æ" 45 "22.5¡æ" 46 "23¡æ" 47 "23.5¡æ" 48 "24¡æ" 49 "24.5¡æ" 50 "25¡æ" 51 "25.5¡æ" 52 "26¡æ" 53 "26.5¡æ" 54 "27¡æ" 55 "27.5¡æ" 56 "28¡æ" 57 "28.5¡æ" 58 "29¡æ" 59 "29.5¡æ" 60 "30¡æ" 61 "30.5¡æ" 62 "31¡æ" 63 "31.5¡æ" 64 "32¡æ" 65 "High" 66 "High" 67 "High" 68 "High" 69 "High" 70 "High" 71 "High" 72 "High" 73 "High" 74 "High" 75 "High" 76 "High" 77 "High" 78 "High" 79 "High" 80 "High" 81 "High" 82 "High" 83 "High" 84 "High" 85 "High" 86 "High" 87 "High" 88 "High" 89 "High" 90 "High" 91 "High" 92 "High" 93 "High" 94 "High" 95 "High" 96 "High" 97 "High" 98 "High" 99 "High" 100 "High" 101 "High" 102 "High" 103 "High" 104 "High" 105 "High" 106 "High" 107 "High" 108 "High" 109 "High" 110 "High" 111 "High" 112 "High" 113 "High" 114 "High" 115 "High" 116 "High" 117 "High" 118 "High" 119 "High" 120 "High" 121 "High" 122 "High" 123 "High" 124 "High" 125 "High" 126 "High" 127 "High" 128 "High" 129 "High" 130 "High" 131 "High" 132 "High" 133 "High" 134 "High" 135 "High" 136 "High" 137 "High" 138 "High" 139 "High" 140 "High" 141 "High" 142 "High" 143 "High" 144 "High" 145 "High" 146 "High" 147 "High" 148 "High" 149 "High" 150 "High" 151 "High" 152 "High" 153 "High" 154 "High" 155 "High" 156 "High" 157 "High" 158 "High" 159 "High" 160 "High" 161 "High" 162 "High" 163 "High" 164 "High" 165 "High" 166 "High" 167 "High" 168 "High" 169 "High" 170 "High" 171 "High" 172 "High" 173 "High" 174 "High" 175 "High" 176 "High" 177 "High" 178 "High" 179 "High" 180 "High" 181 "High" 182 "High" 183 "High" 184 "High" 185 "High" 186 "High" 187 "High" 188 "High" 189 "High" 190 "High" 191 "High" 192 "High" 193 "High" 194 "High" 195 "High" 196 "High" 197 "High" 198 "High" 199 "High" 200 "High" 201 "High" 202 "High" 203 "High" 204 "High" 205 "High" 206 "High" 207 "High" 208 "High" 209 "High" 210 "High" 211 "High" 212 "High" 213 "High" 214 "High" 215 "High" 216 "High" 217 "High" 218 "High" 219 "High" 220 "High" 221 "High" 222 "High" 223 "High" 224 "High" 225 "High" 226 "High" 227 "High" 228 "High" 229 "High" 230 "High" 231 "High" 232 "High" 233 "High" 234 "High" 235 "High" 236 "High" 237 "High" 238 "High" 239 "High" 240 "High" 241 "High" 242 "High" 243 "High" 244 "High" 245 "High" 246 "High" 247 "High" 248 "High" 249 "High" 250 "High" 251 "High" 252 "High" 253 "High" 254 "High" 255 "Invalid" ;
VAL_ 883 ECC_HeatSts 0 "Off_state" 1 "ON_state" ;
VAL_ 883 ECC_AUTOSts 0 "Off" 1 "On" ;
VAL_ 883 ECC_SYNCSts 0 "Off" 1 "On" ;
VAL_ 883 ECC_InfoSysWrmColdDisp 0 "No_action" 1 "Natural_wind" 2 "Cold_air" 3 "Hot_air" ;
VAL_ 883 ECC_CircSts 0 "Inner_circulation_state" 1 "outer_circulation_state" ;
VAL_ 883 ECC_ParticleConcVld 0 "Initializing" 1 "Valid" 2 "Invalid" 3 "Reserved" ;
VAL_ 883 ECC_OutdT 255 "Invalid" ;
VAL_ 883 ECC_OutdTVld 0 "Initializing" 1 "Valid" 2 "Invalid" 3 "Reserved" ;
VAL_ 883 ECC_MaxFrntDefrst 0 "Not_opened" 1 "Open" ;
VAL_ 883 ECC_HeatMngtSysFlt 0 "Normal" 1 "Fault" ;
VAL_ 883 ECC_HeatMngtFctLim 0 "Functional" 1 "function_limit" ;
VAL_ 883 ECC_DrvrAirOutlMod 0 "Reserved" 1 "driver_face_blowing_mode" 2 "driver_face_blowing/foot_blowing_mode" 3 "Driver_foot_blowing_mode" 4 "driver_foot/window_mode" 5 "Window_blowing_mode" 6 "Reserved" 7 "Reserved" ;
VAL_ 883 ECC_PassAirOutlMod 0 "Reserved" 1 "front_passenger_face_blowing_mode" 2 "front_passenger_face_blowing/foot_blowing_mode" 3 "Front_passenger_foot_mode" 4 "Front_passenger_foot/window_mode" 5 "Reserved" 6 "Reserved" 7 "Reserved" ;
VAL_ 883 ECC_RemSts 0 "Standby" 1 "Working" 2 "Fault" 3 "Reserved" ;
VAL_ 883 ECC_OTAInhbRdy 0 "Initial" 1 "Inhibit" 2 "Not_Inhibit" 3 "Invalid" ;
VAL_ 886 WTC_B_InlT 255 "Invalid" ;
VAL_ 886 WTC_B_OutlT 255 "Invalid" ;
VAL_ 886 WTC_B_CrtT 255 "Invalid" ;
VAL_ 886 WTC_B_IninSts 0 "initializing" 1 "initialized" ;
VAL_ 886 WTC_B_HVPwrSplySts 0 "No_power_supply" 1 "Power_supply" ;
VAL_ 886 WTC_B_ActGear 0 "Gear_0" 1 "Gear_1" 2 "Gear_2" 3 "Gear_3" 4 "Gear_4" 5 "Gear_5" 6 "Gear_6" 7 "Reserved" 8 "Reserved" 9 "Reserved" 10 "Reserved" 11 "Reserved" 12 "Reserved" 13 "Reserved" 14 "Reserved" 15 "Reserved" ;
VAL_ 886 WTC_B_Mod 0 "Gear_working_mode" 1 "Power_working_mode" ;
VAL_ 901 TBOX_PreHeatDepartTi1_Hr 31 "INVALID" ;
VAL_ 901 TBOX_PreHeatDepartTi1_Mins 63 "INVALID" ;
VAL_ 901 TBOX_PreHeatDepartSet 0 "init" 1 "Deactivated" 2 "Start_now" 3 "Start_with_timer" ;
VAL_ 901 TBOX_MonPreHeatDepartSet 0 "Not_repeated" 1 "Repeat" ;
VAL_ 901 TBOX_TuePreHeatDepartSet 0 "Not_repeated" 1 "Repeat" ;
VAL_ 901 TBOX_WedPreHeatDepartSet 0 "Not_repeated" 1 "Repeat" ;
VAL_ 901 TBOX_ThuPreHeatDepartSet 0 "Not_repeated" 1 "Repeat" ;
VAL_ 901 TBOX_FriPreHeatDepartSet 0 "Not_repeated" 1 "Repeat" ;
VAL_ 901 TBOX_SatPreHeatDepartSet 0 "Not_repeated" 1 "Repeat" ;
VAL_ 901 TBOX_SunPreHeatDepartSet 0 "Not_repeated" 1 "Repeat" ;
VAL_ 901 TBOX_PreCdnTarT 255 "Invalid" ;
VAL_ 901 TBOX_PreHeatDepartSetFb 0 "Invalid" 1 "Successful" 2 "Failed" 3 "Reserved" ;
VAL_ 901 TBOX_PreHeatDepartTi2_Hr 31 "INVALID" ;
VAL_ 901 TBOX_PreHeatDepartTi2_Mins 63 "INVALID" ;
VAL_ 928 BMS_Cont_Error_StuckOpen_HV_Pos1 0 "RelayOK" 1 "RelayOpen" ;
VAL_ 928 BMS_Cont_Error_Welded_HV_Pos1 0 "RelayOK" 1 "RelayWelded" ;
VAL_ 928 BMS_Cont_Error_Exceed_HV_Pos1 0 "CountersOK" 1 "CountersExceeded" ;
VAL_ 929 BMS_Cont_Error_StuckOpen_HV_Neg1 0 "RelayOK" 1 "RelayOpen" ;
VAL_ 929 BMS_Cont_Error_Welded_HV_Neg1 0 "RelayOK" 1 "RelayWelded" ;
VAL_ 929 BMS_Cont_Error_Exceed_HV_Neg1 0 "CountersOK" 1 "CountersExceeded" ;
VAL_ 930 BMS_Cont_Error_StuckOpen_HV_Prec 0 "RelayOK" 1 "RelayOpen" ;
VAL_ 930 BMS_Cont_Error_Welded_HV_Prec1 0 "RelayOK" 1 "RelayWelded" ;
VAL_ 930 BMS_Cont_Error_Exceed_HV_Prec 0 "CountersOK" 1 "CountersExceeded" ;
VAL_ 933 BMS_BattInlT_Target 255 "Invalid" ;
VAL_ 933 BMS_BattInlT_Min 255 "Invalid" ;
VAL_ 933 BMS_BattInlT_Max 255 "Invalid" ;
VAL_ 934 BMS_Cont_Error_StuckOpen_HV_PV_N 0 "RelayOK" 1 "RelayOpen" ;
VAL_ 934 BMS_Cont_Error_Welded_HV_PV_Neg1 0 "RelayOK" 1 "RelayWelded" ;
VAL_ 934 BMS_Cont_Error_Exceed_HV_PV_Neg1 0 "CountersOK" 1 "CountersExceeded" ;
VAL_ 935 BMS_Cont_Error_StuckOpen_HV_PV_P 0 "RelayOK" 1 "RelayOpen" ;
VAL_ 935 BMS_Cont_Error_Welded_HV_PV_Pos1 0 "RelayOK" 1 "RelayWelded" ;
VAL_ 935 BMS_Cont_Error_Exceed_HV_PV_Pos1 0 "CountersOK" 1 "CountersExceeded" ;
VAL_ 1140 TBOX_ICC_UpdSched 0 "Initial_Value" 1 "Scheduled_time_reached" 2 "Reserved" 3 "Reserved" ;
VAL_ 1140 TBOX_OTAReq_BMS 0 "No_request" 1 "Request" 3 "Invalid" ;
VAL_ 1140 TBOX_OTAReq_VCU 0 "No_request" 1 "Request" 3 "Invalid" ;
VAL_ 1140 TBOX_OTAReq_ECC 0 "No_request" 1 "Request" 3 "Invalid" ;
VAL_ 1140 TBOX_OTAReq_OBC 0 "No_request" 1 "Request" 3 "Invalid" ;
VAL_ 1140 TBOX_OTAReq_MCU_F 0 "No_request" 1 "Request" 3 "Invalid" ;
VAL_ 1140 TBOX_OTAReq_MCU_R 0 "No_request" 1 "Request" 3 "Invalid" ;
VAL_ 1140 TBOX_OTAReq_ADAS 0 "No_request" 1 "Request" 3 "Invalid" ;
VAL_ 1140 TBOX_OTAReq_FCM 0 "No_request" 1 "Request" 3 "Invalid" ;
VAL_ 1140 TBOX_OTAReq_GW 0 "No_request" 1 "Request" 3 "Invalid" ;
VAL_ 1140 TBOX_OTAReq_EPS 0 "No_request" 1 "Request" 3 "Invalid" ;
VAL_ 1140 TBOX_OTAReq_ESP 0 "No_request" 1 "Request" 3 "Invalid" ;
VAL_ 1140 TBOX_OTAReq_iBooster 0 "No_request" 1 "Request" 3 "Invalid" ;
VAL_ 1140 TBOX_OTAReq_SCM 0 "No_request" 1 "Request" 3 "Invalid" ;
VAL_ 1140 TBOX_OTAReq_ICC 0 "No_request" 1 "Request" 3 "Invalid" ;
VAL_ 1140 TBOX_OTAReq_OHC 0 "No_request" 1 "Request" 3 "Invalid" ;
VAL_ 1140 TBOX_OTAReq_BCM 0 "No_request" 1 "Request" 3 "Invalid" ;
VAL_ 1140 TBOX_OTAReq_CIM 0 "No_request" 1 "Request" 3 "Invalid" ;
VAL_ 1140 TBOX_OTAReq_PKC 0 "No_request" 1 "Request" 3 "Invalid" ;
VAL_ 1140 TBOX_OTAReq_PLGM 0 "No_request" 1 "Request" 3 "Invalid" ;
VAL_ 1140 TBOX_OTAReq_TRM 0 "No_request" 1 "Request" 3 "Invalid" ;
VAL_ 1140 TBOX_OTAReq_DSMC 0 "No_request" 1 "Request" 3 "Invalid" ;
VAL_ 1140 TBOX_OTAReq_PSM 0 "No_request" 1 "Request" 3 "Invalid" ;
VAL_ 1140 TBOX_OTAReq_VSP 0 "No_request" 1 "Request" 3 "Invalid" ;
VAL_ 1140 TBOX_OTAReq_TBOX 0 "No_request" 1 "Request" 3 "Invalid" ;
VAL_ 1168 EAS_MotSpdVld 0 "Valid" 1 "Invalid" ;
VAL_ 1168 EAS_CtrlrVoltVld 0 "Valid" 1 "Invalid" ;
VAL_ 1168 EAS_CtrlrCrtVld 0 "Valid" 1 "Invalid" ;
VAL_ 1169 EAS_HVUnderVoltFlt 0 "Normal" 1 "Abnormal" ;
VAL_ 1169 EAS_HVOverVoltFlt 0 "Normal" 1 "Abnormal" ;
VAL_ 1169 EAS_CrtSts 0 "Standby" 1 "Working" 2 "Fault" 3 "Reserved" ;
VAL_ 1169 EAS_IninSts 0 "initializing" 1 "initialized" ;
VAL_ 1169 EAS_OverCrtFlt 0 "Normal" 1 "Abnormal" ;
VAL_ 1169 EAS_HVIntlkFlt 0 "Normal" 1 "Abnormal" ;
VAL_ 1169 EAS_IPMTOverFlt 0 "Normal" 1 "Abnormal" ;
VAL_ 1169 EAS_ComLost_ECC 0 "Normal" 1 "Abnormal" ;
VAL_ 1169 EAS_CtrlCircFlt 0 "Normal" 1 "Abnormal" ;
VAL_ 1169 EAS_IPMHwFlt 0 "Normal" 1 "Abnormal" ;
VAL_ 1268 TBOX_Sw_upd 0 "Initial" 1 "Flashing" 2 "Coding" 3 "Invalid" ;
VAL_ 1268 TBOX_Flsflg 0 "Initial_Value" 1 "HV_Flash_Mode" 2 "LV_Flash_Mode" 3 "HV_Light_Flash_Mode" 7 "Invalid" ;
VAL_ 1268 TBOX_RemFlsh 0 "Without_Request" 1 "RemFlash_Req_Active" 2 "RemCoding_Req_Active" 3 "Precheck_Req_Active" 7 "Invalid" ;
VAL_ 1268 TBOX_FobdGWPartBUSUDSCom 0 "Initial_value" 1 "Not_allowed" 2 "Recovery" 3 "Void" ;
VAL_ 1268 TBOX_RemChrgInsulFctReq 0 "No_action" 1 "On" 2 "Off" 3 "Reserved" ;
VAL_ 1268 TBOX_EHUSetTrvlMod 0 "Initial_value" 1 "Daily_commuter_mode" 2 "Long-distance_travel_mode" 3 "Reserved" ;
VAL_ 1268 TBOX_ResvACChrgOpenSts 0 "Initial_value" 1 "On" 2 "Off" 3 "Reserved" ;
VAL_ 1268 TBOX_RemKL15PwrOnReq 0 "Init_value" 1 "Request" 2 "No_Request" 3 "Invalid" ;
VAL_ 1268 TBOX_PreCondTriggerReq 0 "no_trigger" 1 "Start_Precond._Battery" 2 "Start_Precond._Battery_+_Cabin" 3 "Start_Precond._Cabin" 4 "Stop_Precond." 5 "Reserved" 6 "Reserved" 7 "Reserved" ;
VAL_ 1268 TBOX_BlowLvlReq 0 "off" 1 "Step1" 2 "Step2" 3 "Step3" 4 "Step4" 5 "Step5" 6 "Step6" 7 "Step7" ;
VAL_ 1268 TBOX_ICC_UpdStrt 0 "Initial_Value" 1 "With_Request" 2 "Reserved" ;
VAL_ 1268 TBOX_VehiMod 0 "Default_Mode" 1 "California_mode" 2 "Pet_mode" 3 "Camping_mode" 4 "Mode4" 5 "Mode5" 6 "Mode6" 7 "Mode7" 8 "Mode8" 9 "Mode9" 10 "Mode10" 11 "Mode11" 12 "Mode12" 13 "Mode13" 14 "Mode14" 15 "Mode15" ;
VAL_ 1268 TBOX_Crash_cfm 0 "No_Crash" 1 "Crash_Happened" 2 "Reserved" 3 "Invalid" ;
VAL_ 1268 TBOX_SchedChrgnReq 0 "Scheduled_Charging_Req_Inactive" 1 "Scheduled_Charging_Req_Active" 2 "Reserved" 3 "Invalid" ;
VAL_ 1273 TBOX_OTAResFb 0 "OTA_no_request" 1 "OTA_on_going" 2 "OTA_completed" 3 "OTA_rollback_completed" 4 "OTA_error" 7 "Invalid" ;
VAL_ 1273 TBOX_SpdLim 255 "no_speed_limit" ;
VAL_ 1273 TBOX_OTA_TiRng 65535 "Invalid" ;
VAL_ 1287 VCU_OTAVehInhb_QM_Fb 0 "OTA_veh_cond_not_ok" 1 "OTA_veh_cond_ok" 2 "Fault" 3 "Invalid" ;
VAL_ 1287 VCU_OTAVehCdnChk_QM_sts 0 "OTA_veh_cond_not_ok" 1 "OTA_veh_cond_ok" 2 "Fault" 3 "Invalid" ;
VAL_ 1287 VCU_DrvAvl 0 "Invalid" 1 "Valid" ;
VAL_ 1287 VCU_CllsnSigSts 0 "Not_collided" 1 "Collided" ;
VAL_ 1287 VCU_VehSts_GB 0 "Initial_value" 1 "Vehicle_starting" 2 "Flameout" 3 "Other_states" ;
VAL_ 1287 VCU_MCUOverTFlt_GB 0 "Normal" 1 "Abnormal" ;
VAL_ 1287 VCU_DrvrMotOverTFlt_GB 0 "Normal" 1 "Abnormal" ;
VAL_ 1287 VCU_SOCTooLoAlrm 0 "No_fault" 1 "faulty" ;
VAL_ 1287 VCU_SOCJumpAlrm 0 "No_fault" 1 "faulty" ;
VAL_ 1287 VCU_PwrBattPackMismatAlrm 0 "No_fault" 1 "faulty" ;
VAL_ 1287 VCU_SOCTooHiAlrm 0 "No_fault" 1 "faulty" ;
VAL_ 1287 VCU_DCDCEnaCmd 0 "Disable" 1 "Enable" ;
VAL_ 1287 VCU_PwrBattECCEnaCmd 0 "Disable" 1 "Enable" ;
VAL_ 1287 VCU_MstRlyCtrlCmd 0 "Disconnect" 1 "Closed" ;
VAL_ 1287 VCU_GearSig_GB 0 "Neutral" 1 "1st_gear" 2 "2nd_gear" 3 "3rd_gear" 4 "4th_gear" 5 "5th_gear" 6 "6th_gear" 7 "Reserved" 8 "Reserved" 9 "Reserved" 10 "Reserved" 11 "Reserved" 12 "Reserved" 13 "Reverse_gear" 14 "automatic_D_gear" 15 "parking_gear_P" ;
VAL_ 1287 VCU_DrvrMotNr_GB 0 "Initial_value" 1 "1" 2 "2" 3 "3" 4 "4_pieces" 5 "Reserved" 6 "Reserved" 7 "Reserved" 8 "Reserved" 9 "Reserved" 10 "Reserved" 11 "Reserved" 12 "Reserved" 13 "Reserved" 14 "Reserved" 15 "Reserved" ;
VAL_ 1287 VCU_BattVolt 65535 "Invalid" ;
VAL_ 1297 VCU_BMSLVWakeUpSts 0 "Not_waken_up" 1 "waken_up" ;
VAL_ 1297 VCU_ONWakeUpSig 0 "Not_waken_up" 1 "waken_up" ;
VAL_ 1297 VCU_FCWakeUpSig 0 "Not_waken_up" 1 "waken_up" ;
VAL_ 1297 VCU_SCWakeUpSig 0 "Not_waken_up" 1 "waken_up" ;
VAL_ 1297 VCU_RemWakeUpSig 0 "Not_waken_up" 1 "waken_up" ;
VAL_ 1297 VCU_NetWakeUpSig 0 "Not_waken_up" 1 "waken_up" ;
VAL_ 1297 VCU_LVWakeUpSts_PDU 0 "Not_waken_up" 1 "waken_up" ;
VAL_ 1297 VCU_VehEOLFctFlg 0 "Normal_mode" 1 "EOL_mode" ;
VAL_ 1297 VCU_LVWakeUpSts_MCU 0 "Not_waken_up" 1 "waken_up" ;
VAL_ 1297 VCU_PwrAntithefAllwtRdyFlg 0 "READY_allowed" 1 "READY_not_allowed" ;
VAL_ 1297 VCU_LVWakeUpSts_CCU 0 "Not_waken_up" 1 "waken_up" ;
VAL_ 1297 VCU_RemECCEndCmd 0 "Not_ended" 1 "End" ;
VAL_ 1297 VCU_EvChrgElectcLockCtrlCmd 0 "Initial_value" 1 "locking_command_state" 2 "Unlocking_command_state" 3 "Invalid" ;
VAL_ 1297 VCU_RemPwrBattHeatgEndCmd 0 "Not_ended" 1 "End" ;
VAL_ 1297 VCU_RemChrgEndCmd 0 "Not_ended" 1 "End" ;
VAL_ 1297 VCU_V2L_TrAvl 0 "No" 1 "Yes" ;
VAL_ 1297 VCU_RemBattHeatgFailReason 0 "Initial_value" 1 "Current_ambient_battery_disabled_discharge" 2 "Low_SOC" 3 "vehicle_at_ON_gear" 4 "Vehicle_fault" 5 "The_temp_meets_requ,_there_is_no_need_to_remotely_heat_in_the_discharg_state" 6 "Void" 7 "Void" ;
VAL_ 1297 VCU_RemECCEndReason 0 "Initial_value" 1 "When_the_SOC_of_the_vehicle_is_lower_than_5%,_the_remote_A/C_is_prohibited." 2 "The_vehicle_is_powered_on,_and_the_remote_A/C_is_prohibited." 3 "The_A/C_system_of_the_vehicle_is_abnormal,_and_the_remote_A/C_is_prohibited." 4 "Please_turn_on_after_AC_charging_or_preheating_or_insulation" 5 "Void" 6 "Void" 7 "Void" ;
VAL_ 1297 VCU_V2L_ChrgPortAvl 0 "No" 1 "Yes" ;
VAL_ 1297 VCU_RemChrgEndReason 0 "Initial_value" 1 "abnormal_charging_system,_charging_disabled" 2 "Charging_gun_is_not_connected,_charging_is_not_turned_on" 3 "Supply_equipment_is_not_supported,_and_charging_is_forbidden." 4 "Void" 5 "Void" 6 "Void" 7 "Void" ;
VAL_ 1297 VCU_SchedChrgnStsFb 0 "Idle" 1 "Successful" 2 "Failed" 3 "Processing" ;
VAL_ 1297 VCU_V2V_Avl 0 "No" 1 "Yes" ;
VAL_ 1297 VCU_V2H_Avl 0 "No" 1 "Yes" ;
VAL_ 1297 VCU_V2G_Avl 0 "No" 1 "Yes" ;
VAL_ 1297 VCU_VehMod 0 "None" 1 "THM_Preconditioning" 2 "LV_Energy_Management_during_Parking" 3 "HV_Energy_management_during_Parking" 4 "Remote_HVAD_request" 5 "V2L_Dongle" 6 "V2L_Trunc" 7 "V2V" 8 "OTA" 9 "Workshop_Mode" 10 "LV_Energy_Management_during_Wakeup" 11 "Reserved" 12 "Reserved" 13 "Error" 14 "Initialization" 15 "Invalid" ;
VAL_ 1297 VCU_CalSwVers 0 "Reserved" 1 "G6-1" 2 "G6-2" 3 "G6-3" 4 "G6-4" 5 "G6-5" 6 "G6-6" 7 "G6-7" 8 "G6-8" 9 "G6-9" 10 "Reserved" 11 "G4-1" 12 "G4-2" 13 "G4-3" 14 "G4-4" 15 "G4-5" 16 "G4-6" 17 "G4-7" 18 "G4-8" 19 "G4-9" 20 "Reserved" 21 "G3-1" 22 "G3-2" 23 "G3-3" 24 "G3-4" 25 "G3-5" 26 "G3-6" 27 "G3-7" 28 "G3-8" 29 "G3-9" 30 "Reserved" 31 "Reserved" ;
VAL_ 1297 VCU_RemPwrBattPreheatgEndFlg 0 "Not_ended" 1 "End" ;
VAL_ 1297 VCU_VehOperMod 0 "Reserved" 1 "gear_P" 2 "gear_N" 3 "gear_D" 4 "gear_R" 5 "E_position" 6 "zero_torque_transition" 7 "Idle_at_gear_D" 8 "gear_R_idle" 9 "gear_D_coastdown_feedback" 10 "gear_D_braking_feedback" 11 "gear_E_coastdown_feedback" 12 "gear_E_braking_feedback" 13 "D_gear_limp_condition" 14 "R_gear_limp_condition" 15 "immediately_off_high-voltage_condition" 16 "High_voltage_off_delay" 17 "Cruise" 18 "gear_N_limp" 19 "Zero_torque" 20 "gear_S" 21 "Remote_driving_condition" 22 "Reserved" 23 "Reserved" 24 "Reserved" 25 "Reserved" 26 "Reserved" 27 "Reserved" 28 "Reserved" 29 "Reserved" 30 "Reserved" 31 "Reserved" ;
VAL_ 1297 VCU_VehRemRefrshModReq 0 "Initial_value" 1 "Remote_high_voltage_flash" 2 "Remote_low_voltage_flash-writing" 3 "Void" ;
VAL_ 1297 VCU_RemDTCPwrOnReq 0 "No_demand" 1 "In_demand" ;
VAL_ 1329 ICC_TotMilgVld_ODO 0 "Value_OK" 1 "Value_Unreliable" ;
VAL_ 1329 ICC_DispVehSpdUnit 0 "KMH" 1 "MPH" ;
VAL_ 1329 ICC_ADASSigFlt 0 "No_Failure" 1 "Reversible_Failure" 2 "Irrversible_Failure" 3 "Reserved" ;
VAL_ 1329 ICC_DispFlt 0 "No_Error_No_error" 1 "Error_error" ;
VAL_ 1329 ICC_WorkshopMode 0 "Init" 1 "Active" 2 "Inactive" 3 "Invalid" ;
VAL_ 1476 TBOX_OTA_ownCondchk 0 "No_Request" 1 "Request" 3 "Invalid" ;
VAL_ 1476 TBOX_TerminalRemWakeupSig 0 "Not_waken_up" 1 "Waken_up" ;
VAL_ 1476 TBOX_RemSCModReq 0 "No_remote_control" 1 "Turn_on_remote_charging" 2 "Turn_off_remote_charging" 3 "Reserved" ;
VAL_ 1476 TBOX_RemPwrBattOpenHeatgReq 0 "No_remote_control" 1 "Turn_on_remote_power_battery_heating_mode" 2 "Turn_off_remote_power_battery_heating_mode" 3 "Reserved" ;
VAL_ 1476 TBOX_RemPwrBattResvHeatgReq 0 "No_request" 1 "Request" ;
VAL_ 1476 TBOX_RemInsdInfoDispEna 0 "Disable" 1 "Enable" ;
VAL_ 1476 TBOX_RemECCDefrstModReq 0 "No_remote_control" 1 "Turn_on_remote_AC_defrost_mode" 2 "Turn_off_remote_AC_defrost_mode" 3 "Reserved" ;
VAL_ 1476 TBOX_RemECCResvDefrstReq 0 "No_remote_control" 1 "Reserve_remote_AC_deforst_mode" ;
VAL_ 1476 TBOX_RemECCSetT 0 "Inactive" 1 "Low" 2 "Low" 3 "Low" 4 "Low" 5 "Low" 6 "Low" 7 "Low" 8 "Low" 9 "Low" 10 "Low" 11 "Low" 12 "Low" 13 "Low" 14 "Low" 15 "Low" 16 "Low" 17 "Low" 18 "Low" 19 "Low" 20 "Low" 21 "Low" 22 "Low" 23 "Low" 24 "Low" 25 "Low" 26 "Low" 27 "Low" 28 "Low" 29 "Low" 30 "Low" 31 "Low" 32 "Low" 33 "Low" 34 "Low" 35 "Low" 36 "18¡ãC" 37 "18.5¡ãC" 38 "19¡ãC" 39 "19.5¡ãC" 40 "20¡ãC" 41 "20.5¡ãC" 42 "21¡ãC" 43 "21.5¡ãC" 44 "22¡ãC" 45 "22.5¡ãC" 46 "23¡ãC" 47 "23.5¡ãC" 48 "24¡ãC" 49 "24.5¡ãC" 50 "25¡ãC" 51 "25.5¡ãC" 52 "26¡ãC" 53 "26.5¡ãC" 54 "27¡ãC" 55 "27.5¡ãC" 56 "28¡ãC" 57 "28.5¡ãC" 58 "29¡ãC" 59 "29.5¡ãC" 60 "30¡ãC" 61 "30.5¡ãC" 62 "31¡ãC" 63 "31.5¡ãC" 64 "32¡ãC" 65 "High" 66 "High" 67 "High" 68 "High" 69 "High" 70 "High" 71 "High" 72 "High" 73 "High" 74 "High" 75 "High" 76 "High" 77 "High" 78 "High" 79 "High" 80 "High" 81 "High" 82 "High" 83 "High" 84 "High" 85 "High" 86 "High" 87 "High" 88 "High" 89 "High" 90 "High" 91 "High" 92 "High" 93 "High" 94 "High" 95 "High" 96 "High" 97 "High" 98 "High" 99 "High" 100 "High" 101 "High" 102 "High" 103 "High" 104 "High" 105 "High" 106 "High" 107 "High" 108 "High" 109 "High" 110 "High" 111 "High" 112 "High" 113 "High" 114 "High" 115 "High" 116 "High" 117 "High" 118 "High" 119 "High" 120 "High" 121 "High" 122 "High" 123 "High" 124 "High" 125 "High" 126 "High" 127 "High" 128 "High" 129 "High" 130 "High" 131 "High" 132 "High" 133 "High" 134 "High" 135 "High" 136 "High" 137 "High" 138 "High" 139 "High" 140 "High" 141 "High" 142 "High" 143 "High" 144 "High" 145 "High" 146 "High" 147 "High" 148 "High" 149 "High" 150 "High" 151 "High" 152 "High" 153 "High" 154 "High" 155 "High" 156 "High" 157 "High" 158 "High" 159 "High" 160 "High" 161 "High" 162 "High" 163 "High" 164 "High" 165 "High" 166 "High" 167 "High" 168 "High" 169 "High" 170 "High" 171 "High" 172 "High" 173 "High" 174 "High" 175 "High" 176 "High" 177 "High" 178 "High" 179 "High" 180 "High" 181 "High" 182 "High" 183 "High" 184 "High" 185 "High" 186 "High" 187 "High" 188 "High" 189 "High" 190 "High" 191 "High" 192 "High" 193 "High" 194 "High" 195 "High" 196 "High" 197 "High" 198 "High" 199 "High" 200 "High" 201 "High" 202 "High" 203 "High" 204 "High" 205 "High" 206 "High" 207 "High" 208 "High" 209 "High" 210 "High" 211 "High" 212 "High" 213 "High" 214 "High" 215 "High" 216 "High" 217 "High" 218 "High" 219 "High" 220 "High" 221 "High" 222 "High" 223 "High" 224 "High" 225 "High" 226 "High" 227 "High" 228 "High" 229 "High" 230 "High" 231 "High" 232 "High" 233 "High" 234 "High" 235 "High" 236 "High" 237 "High" 238 "High" 239 "High" 240 "High" 241 "High" 242 "High" 243 "High" 244 "High" 245 "High" 246 "High" 247 "High" 248 "High" 249 "High" 250 "High" 251 "High" 252 "High" 253 "High" 254 "High" 255 "Invalid" ;
VAL_ 1476 TBOX_RemResvECCSetT 0 "Inactive" 1 "Low" 2 "Low" 3 "Low" 4 "Low" 5 "Low" 6 "Low" 7 "Low" 8 "Low" 9 "Low" 10 "Low" 11 "Low" 12 "Low" 13 "Low" 14 "Low" 15 "Low" 16 "Low" 17 "Low" 18 "Low" 19 "Low" 20 "Low" 21 "Low" 22 "Low" 23 "Low" 24 "Low" 25 "Low" 26 "Low" 27 "Low" 28 "Low" 29 "Low" 30 "Low" 31 "Low" 32 "Low" 33 "Low" 34 "Low" 35 "Low" 36 "18¡ãC" 37 "18.5¡ãC" 38 "19¡ãC" 39 "19.5¡ãC" 40 "20¡ãC" 41 "20.5¡ãC" 42 "21¡ãC" 43 "21.5¡ãC" 44 "22¡ãC" 45 "22.5¡ãC" 46 "23¡ãC" 47 "23.5¡ãC" 48 "24¡ãC" 49 "24.5¡ãC" 50 "25¡ãC" 51 "25.5¡ãC" 52 "26¡ãC" 53 "26.5¡ãC" 54 "27¡ãC" 55 "27.5¡ãC" 56 "28¡ãC" 57 "28.5¡ãC" 58 "29¡ãC" 59 "29.5¡ãC" 60 "30¡ãC" 61 "30.5¡ãC" 62 "31¡ãC" 63 "31.5¡ãC" 64 "32¡ãC" 65 "High" 66 "High" 67 "High" 68 "High" 69 "High" 70 "High" 71 "High" 72 "High" 73 "High" 74 "High" 75 "High" 76 "High" 77 "High" 78 "High" 79 "High" 80 "High" 81 "High" 82 "High" 83 "High" 84 "High" 85 "High" 86 "High" 87 "High" 88 "High" 89 "High" 90 "High" 91 "High" 92 "High" 93 "High" 94 "High" 95 "High" 96 "High" 97 "High" 98 "High" 99 "High" 100 "High" 101 "High" 102 "High" 103 "High" 104 "High" 105 "High" 106 "High" 107 "High" 108 "High" 109 "High" 110 "High" 111 "High" 112 "High" 113 "High" 114 "High" 115 "High" 116 "High" 117 "High" 118 "High" 119 "High" 120 "High" 121 "High" 122 "High" 123 "High" 124 "High" 125 "High" 126 "High" 127 "High" 128 "High" 129 "High" 130 "High" 131 "High" 132 "High" 133 "High" 134 "High" 135 "High" 136 "High" 137 "High" 138 "High" 139 "High" 140 "High" 141 "High" 142 "High" 143 "High" 144 "High" 145 "High" 146 "High" 147 "High" 148 "High" 149 "High" 150 "High" 151 "High" 152 "High" 153 "High" 154 "High" 155 "High" 156 "High" 157 "High" 158 "High" 159 "High" 160 "High" 161 "High" 162 "High" 163 "High" 164 "High" 165 "High" 166 "High" 167 "High" 168 "High" 169 "High" 170 "High" 171 "High" 172 "High" 173 "High" 174 "High" 175 "High" 176 "High" 177 "High" 178 "High" 179 "High" 180 "High" 181 "High" 182 "High" 183 "High" 184 "High" 185 "High" 186 "High" 187 "High" 188 "High" 189 "High" 190 "High" 191 "High" 192 "High" 193 "High" 194 "High" 195 "High" 196 "High" 197 "High" 198 "High" 199 "High" 200 "High" 201 "High" 202 "High" 203 "High" 204 "High" 205 "High" 206 "High" 207 "High" 208 "High" 209 "High" 210 "High" 211 "High" 212 "High" 213 "High" 214 "High" 215 "High" 216 "High" 217 "High" 218 "High" 219 "High" 220 "High" 221 "High" 222 "High" 223 "High" 224 "High" 225 "High" 226 "High" 227 "High" 228 "High" 229 "High" 230 "High" 231 "High" 232 "High" 233 "High" 234 "High" 235 "High" 236 "High" 237 "High" 238 "High" 239 "High" 240 "High" 241 "High" 242 "High" 243 "High" 244 "High" 245 "High" 246 "High" 247 "High" 248 "High" 249 "High" 250 "High" 251 "High" 252 "High" 253 "High" 254 "High" 255 "Invalid" ;
VAL_ 1476 TBOX_4GSigIND 0 "No_signal" 1 "Weak" 2 "Moderate" 3 "Strong" ;
VAL_ 1476 TBOX_Conn_Typ 0 "Not_Connected" 1 "3G_or_4G_LTE_CAT-1_and_below_(downllink_less_than_10_Mbps)" 2 "4G_LTE_CAT-2_and_above_(downlink_greater_than_10_Mbps)" 3 "WiFi_2,4_GHz" 4 "WiFi_5_GHz" 5 "Reserved_for_5G_FR1_(Less_than_1_Gbps)" 6 "Reserved_for_5G_FR2_(Greater_than_1_Gbps)" 7 "Reserved_for_5G_mmWave" ;
VAL_ 1476 TBOX_TSPNotConn 0 "Normal" 1 "fault" ;
VAL_ 1476 TBOX_EHUNotCONN 0 "Normal" 1 "fault" ;
VAL_ 1476 TBOX_WIFIError 0 "Normal" 1 "fault" ;
VAL_ 1476 TBOX_InnerBattError 0 "Normal" 1 "fault" ;
VAL_ 1476 TBOX_VoltLow 0 "Normal" 1 "fault" ;
VAL_ 1476 TBOX_VoltHigh 0 "Normal" 1 "fault" ;
VAL_ 1476 TBOX_4GLoss 0 "Normal" 1 "fault" ;
VAL_ 1476 TBOX_RemSWH_Req 0 "No_request" 1 "SWH_ON" 2 "Reserved" 3 "Invalid" ;
VAL_ 1476 TBOX_OTAInhbReq 0 "No_Inhibit_request" 1 "Inhibit_Request" 2 "Reserved" 3 "Invalid" ;
VAL_ 1562 TBOX_RemDTCDmd 0 "No_demand" 1 "Demand" ;
VAL_ 1562 TBOX_DrvRngCldVld 0 "Initializing" 1 "Valid" 2 "Invalid" 3 "Reserved" ;
VAL_ 1583 TBOX_CrtTi_Day 0 "Day1" 30 "Day31" ;
VAL_ 1583 TBOX_CrtTi_Hr 0 "Hour_0" 23 "Hour_23" ;
VAL_ 1583 TBOX_CrtTi_Mins 0 "Mintue_0" 59 "Mintue_59" ;
VAL_ 1583 TBOX_CrtTi_Yr 0 "Year_2015" 255 "Year2270" ;
VAL_ 1583 TBOX_CrtTi_Mth 0 "January" 11 "December" ;
VAL_ 1583 TBOX_CrtTi_Sec 0 "Second_0" 59 "Second_59" ;
VAL_ 1594 BMS_Splr 0 "Other" 1 "Planet" 2 "Coslight" 3 "SumSung" 4 "Zhuoneng" 5 "South_Korea_SK" 6 "Gotion" 7 "Tenpower" 8 "Farasis_Energy" 9 "BJEV" 10 "Octillion" 11 "Microvast" 12 "Reserved" 13 "CATL" 14 "Reserved" 15 "Reserved" ;
VAL_ 1594 BMS_PwrBattTyp 0 "Other" 1 "Ni-MH" 2 "LFP" 3 "LMO" 4 "Li-Sulfur" 5 "NCM" 6 "Sodium-solphur" 7 "Lithium_titanate" 8 "Lead-acid" 9 "Metal-air" 10 "Reserved" 11 "Reserved" 12 "Reserved" 13 "Reserved" 14 "Reserved" 15 "Reserved" ;
VAL_ 1604 ECC_ReMotOutlT 255 "Invalid" ;
VAL_ 1604 ECC_CoolgDfct 0 "Active" 1 "Inactive" ;
VAL_ 1604 ECC_CooltHomSts 0 "not_homogenized" 1 "homogenized" ;
VAL_ 1604 ECC_PDUInlT 255 "Invalid" ;
VAL_ 1604 ECC_FrntMotOutlT 255 "Invalid" ;
VAL_ 1604 ECC_MCURInlT 255 "Invalid" ;
